VERSION "Version"

NS_ :

BS_:

BU_: LBMS CCU ZCUR_ZCUT Tester PLGM CCURT2 TMC ZCUF ZCUL ZCUR ZCUT EMS DCDC IPS NIDU DCU2 IDUR OBC OPC LPC CPC GCU DCU IPU BMS EOP DCDC2 SRS ECS SAS CBM RAS EPS RBM IBCS ICM IID IDC RCICP AMP WHUD IMR CD INU ADC IFC FAPA RRR RLR PAS PCS SCMR SCMRL SCMRR SCMRM SCMT MFS DRM IDU FCP RCP LBMSAD AVAS DLPFL FBLCM FLISD FLLCM FRLCM RLLCMA RLLCMB RRLCMA RRLCMB RLISD RRISD DLPML DLPMR PSDL PSDR HVSPRL HVSPRR TBOX2 TBOX EPB RFR SBM WCM ETC EVCC CCURT1 EDL

BO_ 1016 LBMS_3: 64 LBMS
 SG_ LBMS_UnSfLoadCurrent : 31|22@0+ (0.001,-1500) [-1500|2694.303] "A"  CCU,CCURT1,CCURT2
 SG_ LBMS_UnSftyLoadCurrentVD : 200|1@0+ (1,0) [0|1] ""  CCU,CCURT1,CCURT2
 SG_ LBMS_SfLoadCurrent : 41|22@0+ (0.001,-1500) [-1500|2694.303] "A"  CCU,CCURT1,CCURT2
 SG_ LBMS_SfLoadCurrentVD : 201|1@0+ (1,0) [0|1] ""  CCU,CCURT1,CCURT2
 SG_ LBMS_ComSoVolt : 99|12@0+ (0.01,0) [0|40.95] "V"  CCU,CCURT1,CCURT2
 SG_ LBMS_ComSoVoltVD : 202|1@0+ (1,0) [0|1] ""  CCU,CCURT1,CCURT2
 SG_ LBMS_UnSfLoadComSoVolt : 119|12@0+ (0.01,0) [0|40.95] "V"  CCU,CCURT1,CCURT2
 SG_ LBMS_UnSfLoadComSoVoltVD : 203|1@0+ (1,0) [0|1] ""  CCU,CCURT1,CCURT2
 SG_ LBMS_UnsfLoadMosst : 171|3@0+ (1,0) [0|7] ""  CCU,CCURT1,CCURT2
 SG_ LBMS_UnSfLoadMosTemp1 : 67|8@0+ (1,-40) [-40|215] "℃"  CCU,CCURT1,CCURT2
 SG_ LBMS_UnSfLoadMosTemp1VD : 204|1@0+ (1,0) [0|1] ""  CCU,CCURT1,CCURT2
 SG_ LBMS_UnSfLoadMosTemp2 : 75|8@0+ (1,-40) [-40|215] "℃"  CCU,CCURT1,CCURT2
 SG_ LBMS_UnSfLoadMosTemp2VD : 205|1@0+ (1,0) [0|1] ""  CCU,CCURT1,CCURT2
 SG_ LBMS_UnSfLoadShuntTemp : 83|8@0+ (1,-40) [-40|215] "℃"  CCU,CCURT1,CCURT2
 SG_ LBMS_UnSfLoadShuntTempVD : 206|1@0+ (1,0) [0|1] ""  CCU,CCURT1,CCURT2
 SG_ LBMS_SfLoadShuntTemp : 91|8@0+ (1,-40) [-40|215] "℃"  CCU,CCURT1,CCURT2
 SG_ LBMS_SfLoadShuntTempVD : 207|1@0+ (1,0) [0|1] ""  CCU,CCURT1,CCURT2
 SG_ LBMS_UnSfLoadChgMosDrvVolt : 123|12@0+ (0.01,0) [0|40.95] "V"  CCU,CCURT1,CCURT2
 SG_ LBMS_UnSfLoadChgMosDrvVoltVD : 212|1@0+ (1,0) [0|1] ""  CCU,CCURT1,CCURT2
 SG_ LBMS_UnSfLoadDsgMosDrvVolt : 143|12@0+ (0.01,0) [0|40.95] "V"  CCU,CCURT1,CCURT2
 SG_ LBMS_UnSfLoadDsgMosDrvVoltVD : 213|1@0+ (1,0) [0|1] ""  CCU,CCURT1,CCURT2
 SG_ LBMS_ChgMosDrvVolt : 147|12@0+ (0.01,0) [0|40.95] "V"  CCU,CCURT1,CCURT2
 SG_ LBMS_ChgMosDrvVoltVD : 214|1@0+ (1,0) [0|1] ""  CCU,CCURT1,CCURT2
 SG_ LBMS_DsgMosDrvVolt : 167|12@0+ (0.01,0) [0|40.95] "V"  CCU,CCURT1,CCURT2
 SG_ LBMS_DsgMosDrvVoltVD : 215|1@0+ (1,0) [0|1] ""  CCU,CCURT1,CCURT2
 SG_ LBMS_UnSfLoadFaultOTMOS : 185|2@0+ (1,0) [0|3] ""  CCU,CCURT1,CCURT2
 SG_ LBMS_UnSfLoadFaultOTS : 187|2@0+ (1,0) [0|3] ""  CCU,CCURT1,CCURT2
 SG_ LBMS_SfLoadFaultOTS : 189|2@0+ (1,0) [0|3] ""  CCU,CCURT1,CCURT2
 SG_ LBMS_UnSfLoadFaultChgOC : 191|2@0+ (1,0) [0|3] ""  CCU,CCURT1,CCURT2
 SG_ LBMS_UnSfLoadFaultDsgOC : 178|3@0+ (1,0) [0|7] ""  CCU,CCURT1,CCURT2
 SG_ LBMS_SfLoadFaultDsgOC : 181|3@0+ (1,0) [0|7] ""  CCU,CCURT1,CCURT2
 SG_ LBMS_UnSfLoadFaultHardTCMOS : 193|2@0+ (1,0) [0|3] ""  CCU,CCURT1,CCURT2
 SG_ LBMS_UnSfLoadFaultHardShunt : 195|2@0+ (1,0) [0|3] ""  CCU,CCURT1,CCURT2
 SG_ LBMS_SfLoadFaultHardShunt : 197|2@0+ (1,0) [0|3] ""  CCU,CCURT1,CCURT2
 SG_ LBMS_UnSfLoadFaultHardChgMOS : 199|2@0+ (1,0) [0|3] ""  CCU,CCURT1,CCURT2
 SG_ LBMS_UnSfLoadFaultHardDsgMOS : 168|3@0+ (1,0) [0|7] ""  CCU,CCURT1,CCURT2
 SG_ LBMS_SOCTolerance : 211|8@0+ (1,0) [0|255] "%"  CCU,CCURT1,CCURT2
 SG_ LBMS_ChgMosDrvCmd : 240|1@0+ (1,0) [0|1] ""  CCU,CCURT1,CCURT2
 SG_ LBMS_DsgMosDrvCmd : 241|1@0+ (1,0) [0|1] ""  CCU,CCURT1,CCURT2
 SG_ LBMS_Cell1BalCtrlCmd : 242|1@0+ (1,0) [0|1] ""  CCU,CCURT1,CCURT2
 SG_ LBMS_Cell2BalCtrlCmd : 243|1@0+ (1,0) [0|1] ""  CCU,CCURT1,CCURT2
 SG_ LBMS_Cell3BalCtrlCmd : 252|1@0+ (1,0) [0|1] ""  CCU,CCURT1,CCURT2
 SG_ LBMS_Cell4BalCtrlCmd : 253|1@0+ (1,0) [0|1] ""  CCU,CCURT1,CCURT2
 SG_ LBMS_FaultStHardPackVolCol : 233|2@0+ (1,0) [0|3] ""  CCU,CCURT1,CCURT2
 SG_ LBMS_FaultStHardUnSfPackVolCol : 235|2@0+ (1,0) [0|3] ""  CCU,CCURT1,CCURT2
 SG_ LBMS_PoleTemp : 219|8@0+ (1,-40) [-40|215] "℃"  CCU,CCURT1,CCURT2
 SG_ LBMS_PoleTempVD : 254|1@0+ (1,0) [0|1] ""  CCU,CCURT1,CCURT2
 SG_ LBMS_SfLoadPoleTemp : 227|8@0+ (1,-40) [-40|215] "℃"  CCU,CCURT1,CCURT2
 SG_ LBMS_SfLoadPoleTempVD : 255|1@0+ (1,0) [0|1] ""  CCU,CCURT1,CCURT2
 SG_ LBMS_FaultStHardCellTotVolCol : 245|2@0+ (1,0) [0|3] ""  CCU,CCURT1,CCURT2
 SG_ LBMS_FaultStHardComSoVoltCol : 247|2@0+ (1,0) [0|3] ""  CCU,CCURT1,CCURT2
 SG_ LBMS_AvailableCapacity : 374|9@0+ (0.1,0) [0|50] "Ah"  CCU,CCURT1,CCURT2
 SG_ LBMS_DCDCMosOpenReason : 291|8@0+ (1,0) [0|255] ""  CCU,CCURT1,CCURT2
 SG_ LBMS_AutoChgReason : 381|3@0+ (1,0) [0|7] ""  CCU,CCURT1,CCURT2
 SG_ LBMS_LockSOCThreshold_Trans : 299|8@0+ (1,0) [0|100] "%"  CCU,CCURT1,CCURT2
 SG_ LBMS_LockSOCThreshold_Level1 : 307|8@0+ (1,0) [0|100] "%"  CCU,CCURT1,CCURT2
 SG_ LBMS_LockSOCThreshold_Level2 : 315|8@0+ (1,0) [0|100] "%"  CCU,CCURT1,CCURT2
 SG_ LBMS_AutoChgThres_TransLo : 323|8@0+ (1,0) [0|100] "%"  CCU,CCURT1,CCURT2
 SG_ LBMS_AutoChgThres_TransUp : 331|8@0+ (1,0) [0|100] "%"  CCU,CCURT1,CCURT2
 SG_ LBMS_AutoChgThres_NtransLo : 339|8@0+ (1,0) [0|100] "%"  CCU,CCURT1,CCURT2
 SG_ LBMS_AutoChgThres_NtransUp : 347|8@0+ (1,0) [0|100] "%"  CCU,CCURT1,CCURT2
 SG_ LBMS_Last2LocWakeUpTime : 251|20@0+ (1,0) [0|1048575] "min"  CCU,CCURT1,CCURT2
 SG_ LBMS_SleepTime_NM : 279|20@0+ (1,0) [0|1048575] "min"  CCU,CCURT1,CCURT2
 SG_ LBMS_ServiceTime : 355|13@0+ (1,0) [0|8191] "day"  CCU,CCURT1,CCURT2
 SG_ LBMS_DsgMosOpenReason : 391|8@0+ (1,0) [0|255] ""  CCU,CCURT1,CCURT2
 SG_ LBMS_ChgMosOpenReason : 399|8@0+ (1,0) [0|255] ""  CCU,CCURT1,CCURT2
 SG_ LBMS_LocalNotSleep_Reason : 423|4@0+ (1,0) [0|15] ""  CCU,CCURT1,CCURT2
 SG_ LBMS_SfUpackRvsVolt : 407|12@0+ (0.01,-20) [-20|20] "V"  CCU,CCURT1,CCURT2
 SG_ LBMS_SfUpackRvsVoltVD : 378|1@0+ (1,0) [0|1] ""  CCU,CCURT1,CCURT2
 SG_ LBMS_SfFaultStHardComSoVoltCol : 377|2@0+ (1,0) [0|3] ""  CCU,CCURT1,CCURT2
 SG_ LBMS_SfChgMosDrvCmd : 411|1@0+ (1,0) [0|1] ""  CCU,CCURT1,CCURT2
 SG_ LBMS_SfDsgMosDrvCmd : 410|1@0+ (1,0) [0|1] ""  CCU,CCURT1,CCURT2
 SG_ LBMS_SfLoadUpackRvsVolt : 419|12@0+ (0.01,-20) [-20|20] "V"  CCU,CCURT1,CCURT2
 SG_ LBMS_SfLoadUpackRvsVoltVD : 409|1@0+ (1,0) [0|1] ""  CCU,CCURT1,CCURT2
 SG_ LBMS_UnSfLoadChgMosDrvCmd : 408|1@0+ (1,0) [0|1] ""  CCU,CCURT1,CCURT2
 SG_ LBMS_UnSfLoadDsgMosDrvCmd : 455|1@0+ (1,0) [0|1] ""  CCU,CCURT1,CCURT2
 SG_ LBMS_UnsfLoadDsgMosOpenReason : 439|8@0+ (1,0) [0|255] ""  CCU,CCURT1,CCURT2
 SG_ LBMS_UnsfLoadChgMosOpenReason : 447|8@0+ (1,0) [0|255] ""  CCU,CCURT1,CCURT2
 SG_ LBMS_FaultStHarddUnSfComSoVoltCol : 454|2@0+ (1,0) [0|3] ""  CCU,CCURT1,CCURT2

BO_ 794 CCU_LBMSAD_1: 64 CCU
 SG_ LBMSAD_1_CRC : 7|16@0+ (1,0) [0|65535] ""  LBMS
 SG_ LBMSAD_1_Counter : 23|8@0+ (1,0) [0|255] ""  LBMS
 SG_ LBMSAD_SOFVD : 28|1@0+ (1,0) [0|1] ""  LBMS
 SG_ LBMSAD_SOFEN : 30|2@0+ (1,0) [0|3] ""  LBMS
 SG_ LBMSAD_ChargReq : 26|3@0+ (1,0) [0|7] ""  LBMS
 SG_ LBMSAD_SOCVD : 27|1@0+ (1,0) [0|1] ""  LBMS
 SG_ LBMSAD_SOC : 39|8@0+ (1,0) [0|100] "%"  LBMS
 SG_ LBMSAD_AlrmDispSt : 60|3@0+ (1,0) [0|7] ""  LBMS
 SG_ LBMSAD_CurrentRange : 57|2@0+ (1,0) [0|3] ""  LBMS
 SG_ LBMSAD_RefChargReq : 75|2@0+ (1,0) [0|3] ""  LBMS
 SG_ LBMSAD_ThermalRunawayErr : 77|2@0+ (1,0) [0|3] ""  LBMS
 SG_ LBMSAD_ChrgVoltReq : 71|10@0+ (0.01,9) [9|19.23] "V"  LBMS
 SG_ LBMSAD_IPDS_BAT1PowerReq : 107|1@0+ (1,0) [0|1] ""  LBMS
 SG_ LBMSAD_IPDS_BAT2PowerReq : 108|1@0+ (1,0) [0|1] ""  LBMS
 SG_ LBMSAD_IPDS_GridlsoPowerReq : 109|1@0+ (1,0) [0|1] ""  LBMS

BO_ 974 CCU_LBMSAD_2: 64 CCU
 SG_ LBMSAD_SOH : 7|8@0+ (1,0) [0|255] ""  LBMS
 SG_ LBMSAD_SOHVD : 25|1@0+ (1,0) [0|1] ""  LBMS
 SG_ LBMSAD_Current : 15|22@0+ (0.001,-1500) [-1500|2694.303] "A"  LBMS
 SG_ LBMSAD_CellTotVolt : 43|11@0+ (0.01,0) [0|20.47] "V"  LBMS
 SG_ LBMSAD_CellTotVoltVD : 24|1@0+ (1,0) [0|1] ""  LBMS
 SG_ LBMSAD_ChargReqEn : 48|1@0+ (1,0) [0|1] ""  LBMS
 SG_ LBMSAD_WorkSt : 63|4@0+ (1,0) [0|15] ""  LBMS
 SG_ LBMSAD_MOSSt : 71|3@0+ (1,0) [0|7] ""  LBMS
 SG_ LBMSAD_WireHarnConSt : 202|1@0+ (1,0) [0|1] ""  LBMS
 SG_ LBMSAD_CellMaxVolt : 183|13@0+ (0.001,0) [0|8.191] "V"  LBMS
 SG_ LBMSAD_CellMinVolt : 199|13@0+ (0.001,0) [0|8.191] "V"  LBMS
 SG_ LBMSAD_CellTemp1 : 215|8@0+ (1,-40) [-40|215] "℃"  LBMS
 SG_ LBMSAD_CellTemp2 : 223|8@0+ (1,-40) [-40|215] "℃"  LBMS
 SG_ LBMSAD_CellTemp3 : 231|8@0+ (1,-40) [-40|215] "℃"  LBMS

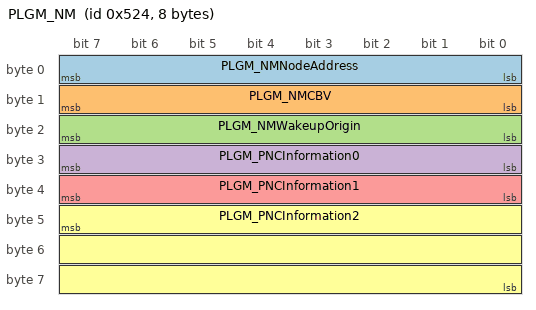
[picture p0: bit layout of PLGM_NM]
BO_ 1316 PLGM_NM: 8 PLGM
 SG_ PLGM_NMNodeAddress : 7|8@0+ (1,0) [0|255] ""  CCU,ZCUR,LBMS
 SG_ PLGM_NMCBV : 15|8@0+ (1,0) [0|0] ""  CCU,ZCUR,LBMS
 SG_ PLGM_NMWakeupOrigin : 23|8@0+ (1,0) [0|255] ""  CCU,ZCUR,LBMS
 SG_ PLGM_PNCInformation0 : 31|8@0+ (1,0) [0|255] ""  CCU,ZCUR,LBMS
 SG_ PLGM_PNCInformation1 : 39|8@0+ (1,0) [0|255] ""  CCU,ZCUR,LBMS
 SG_ PLGM_PNCInformation2 : 47|24@0+ (1,0) [0|0] ""  CCU,ZCUR,LBMS

BO_ 387 CCU_ADC_4_New: 64 CCU
 SG_ ADC_4_New_CRC : 7|16@0+ (1,0) [0|65535] ""  ZCUF,ZCUL,ZCUR,ZCUT,SRS,EPS,RBM,IBCS,LBMSAD,LBMS
 SG_ ADC_4_New_Counter : 23|8@0+ (1,0) [0|255] ""  ZCUF,ZCUL,ZCUR,ZCUT,SRS,EPS,RBM,IBCS,LBMSAD,LBMS
 SG_ ADC_AD_NetMode : 65|2@0+ (1,0) [0|3] "/"  ZCUF,ZCUL,ZCUR,ZCUT,SRS,EPS,RBM,IBCS,LBMSAD,LBMS

CM_ SG_ 1016 LBMS_UnSfLoadCurrent "Battery unsafe load current";
CM_ SG_ 1016 LBMS_UnSftyLoadCurrentVD "Battery unsafe load current validity";
CM_ SG_ 1016 LBMS_SfLoadCurrent "Battery safe load current";
CM_ SG_ 1016 LBMS_SfLoadCurrentVD "Battery safe load current validity";
CM_ SG_ 1016 LBMS_ComSoVolt "Battery  common source voltage";
CM_ SG_ 1016 LBMS_ComSoVoltVD "Battery  common source voltage validity";
CM_ SG_ 1016 LBMS_UnSfLoadComSoVolt "Battery  common source voltage of unsafe load ";
CM_ SG_ 1016 LBMS_UnSfLoadComSoVoltVD "Battery  common source voltage of unsafe load validity";
CM_ SG_ 1016 LBMS_UnsfLoadMosst "State of unsafe load mos";
CM_ SG_ 1016 LBMS_UnSfLoadMosTemp1 "UnSafe Load Mos1 temperature";
CM_ SG_ 1016 LBMS_UnSfLoadMosTemp1VD "UnSafe load Mos1 temperature validity";
CM_ SG_ 1016 LBMS_UnSfLoadMosTemp2 "UnSafe load mos2 temperature";
CM_ SG_ 1016 LBMS_UnSfLoadMosTemp2VD "UnSafe load mos2 temperature validity";
CM_ SG_ 1016 LBMS_UnSfLoadShuntTemp "UnSafe load shunt temperature signal";
CM_ SG_ 1016 LBMS_UnSfLoadShuntTempVD "UnSafe load shunt temperature signal validity";
CM_ SG_ 1016 LBMS_SfLoadShuntTemp "Safe load shunt temperature signal";
CM_ SG_ 1016 LBMS_SfLoadShuntTempVD "Safe load shunt temperature signal validity";
CM_ SG_ 1016 LBMS_UnSfLoadChgMosDrvVolt "Charge Mos driver voltage of unsafe load ";
CM_ SG_ 1016 LBMS_UnSfLoadChgMosDrvVoltVD "Charge Mos driver voltage of unsafe load Validity";
CM_ SG_ 1016 LBMS_UnSfLoadDsgMosDrvVolt "Discharge Mos driver voltage of unsafe load ";
CM_ SG_ 1016 LBMS_UnSfLoadDsgMosDrvVoltVD "Discharge Mos driver voltage of unsafe load Validity";
CM_ SG_ 1016 LBMS_ChgMosDrvVolt "Charge Mos driver voltage";
CM_ SG_ 1016 LBMS_ChgMosDrvVoltVD "Charge Mos driver voltage Validity";
CM_ SG_ 1016 LBMS_DsgMosDrvVolt "Discharge Mos driver voltage";
CM_ SG_ 1016 LBMS_DsgMosDrvVoltVD "Discharge Mos driver voltage Validity";
CM_ SG_ 1016 LBMS_UnSfLoadFaultOTMOS "Over temperature fault of UnSafe Load MOS";
CM_ SG_ 1016 LBMS_UnSfLoadFaultOTS "Over temperature fault of UnSafe Load Shunt";
CM_ SG_ 1016 LBMS_SfLoadFaultOTS "Over temperature fault of Safe Load Shunt";
CM_ SG_ 1016 LBMS_UnSfLoadFaultChgOC " UnSafe Load Charge over current fault";
CM_ SG_ 1016 LBMS_UnSfLoadFaultDsgOC " UnSafe Load Discharge over current fault";
CM_ SG_ 1016 LBMS_SfLoadFaultDsgOC " Safe Load Discharge over current fault";
CM_ SG_ 1016 LBMS_UnSfLoadFaultHardTCMOS "Temperature collect hardware fault of UnSafe Load MOS";
CM_ SG_ 1016 LBMS_UnSfLoadFaultHardShunt "UnSafe Load Shunt  hardware fault";
CM_ SG_ 1016 LBMS_SfLoadFaultHardShunt "Safe Load Shunt  hardware fault";
CM_ SG_ 1016 LBMS_UnSfLoadFaultHardChgMOS "UnSafe Load Charge mos hardware fault";
CM_ SG_ 1016 LBMS_UnSfLoadFaultHardDsgMOS "UnSafe Load Discharge mos hardware fault";
CM_ SG_ 1016 LBMS_SOCTolerance "The Tolerance of SOC";
CM_ SG_ 1016 LBMS_ChgMosDrvCmd "LBMS Charge Mosfet Driver Command";
CM_ SG_ 1016 LBMS_DsgMosDrvCmd "LBMS Discharge Mosfet Driver Command";
CM_ SG_ 1016 LBMS_Cell1BalCtrlCmd "LBMS Cell1 Balance Control Command";
CM_ SG_ 1016 LBMS_Cell2BalCtrlCmd "LBMS Cell2 Balance Control Command";
CM_ SG_ 1016 LBMS_Cell3BalCtrlCmd "LBMS Cell3 Balance Control Command";
CM_ SG_ 1016 LBMS_Cell4BalCtrlCmd "LBMS Cell4 Balance Control Command";
CM_ SG_ 1016 LBMS_FaultStHardPackVolCol "Pack volt collect open hardware fault";
CM_ SG_ 1016 LBMS_FaultStHardUnSfPackVolCol "Unsafe Load Pack volt collect open hardware fault";
CM_ SG_ 1016 LBMS_PoleTemp "UnSafe Load Pole temperature";
CM_ SG_ 1016 LBMS_PoleTempVD "UnSafe load Pole temperature validity";
CM_ SG_ 1016 LBMS_SfLoadPoleTemp "Safe Load Pole temperature";
CM_ SG_ 1016 LBMS_SfLoadPoleTempVD "Safe load Pole temperature validity";
CM_ SG_ 1016 LBMS_FaultStHardCellTotVolCol "Cell total volt collect open hardware fault";
CM_ SG_ 1016 LBMS_FaultStHardComSoVoltCol "Battery common source volt collect open hardware fault";
CM_ SG_ 1016 LBMS_AvailableCapacity "LBMS Available Capacity of Battery";
CM_ SG_ 1016 LBMS_DCDCMosOpenReason "LBMS DCDC Mosfet Open Reason";
CM_ SG_ 1016 LBMS_AutoChgReason "LBMS Automatic Charging Reason";
CM_ SG_ 1016 LBMS_LockSOCThreshold_Trans "LBMS Lock Threshold of Transport Mode";
CM_ SG_ 1016 LBMS_LockSOCThreshold_Level1 "LBMS Lock Threshold of Level1";
CM_ SG_ 1016 LBMS_LockSOCThreshold_Level2 "LBMS Lock Threshold of Level2";
CM_ SG_ 1016 LBMS_AutoChgThres_TransLo "LBMS Automatic Charging Threshold Lower Limit of Transport Mode";
CM_ SG_ 1016 LBMS_AutoChgThres_TransUp "LBMS Automatic Charging Threshold Upper Limit of Transport Mode";
CM_ SG_ 1016 LBMS_AutoChgThres_NtransLo "LBMS Automatic Charging Threshold Lower Limit of None Transport Mode";
CM_ SG_ 1016 LBMS_AutoChgThres_NtransUp "LBMS Automatic Charging Threshold Upper Limit of None Transport Mode";
CM_ SG_ 1016 LBMS_Last2LocWakeUpTime "The Time Between Last 2 Local wake up of LBMS";
CM_ SG_ 1016 LBMS_SleepTime_NM "The Sleep Time of Network";
CM_ SG_ 1016 LBMS_ServiceTime "Accumulated Battery  Service time";
CM_ SG_ 1016 LBMS_DsgMosOpenReason "LBMS Discharge Mosfet Open Reason";
CM_ SG_ 1016 LBMS_ChgMosOpenReason "LBMS Charge Mosfet Open Reason";
CM_ SG_ 1016 LBMS_LocalNotSleep_Reason "Reason of LBMS not sleep locally for a long time";
CM_ SG_ 1016 LBMS_SfUpackRvsVolt "LBMS Battery Reverse Connection Voltage of Pack";
CM_ SG_ 1016 LBMS_SfUpackRvsVoltVD "LBMS Battery Reverse Connection Voltage of Pack Validity";
CM_ SG_ 1016 LBMS_SfFaultStHardComSoVoltCol "Safe Load Battery common source volt collect open hardware fault";
CM_ SG_ 1016 LBMS_SfChgMosDrvCmd "LBMS Safe load Charge Mosfet Driver Command";
CM_ SG_ 1016 LBMS_SfDsgMosDrvCmd "LBMS Safe load Discharge Mosfet Driver Command";
CM_ SG_ 1016 LBMS_SfLoadUpackRvsVolt "LBMS Battery Negative Voltage of Pack for Sf Load";
CM_ SG_ 1016 LBMS_SfLoadUpackRvsVoltVD "LBMS Battery Negative Voltage of Pack Validity for Sf Load";
CM_ SG_ 1016 LBMS_UnSfLoadChgMosDrvCmd "LBMS Charge Mosfet Driver Command of unsafe load";
CM_ SG_ 1016 LBMS_UnSfLoadDsgMosDrvCmd "LBMS Discharge Mosfet Driver Command of unsafe load";
CM_ SG_ 1016 LBMS_UnsfLoadDsgMosOpenReason "LBMS Discharge Mosfet Open Reason";
CM_ SG_ 1016 LBMS_UnsfLoadChgMosOpenReason "LBMS Charge Mosfet Open Reason";
CM_ SG_ 1016 LBMS_FaultStHarddUnSfComSoVoltCol "Battery Unsafe Load common source volt collect open hardware fault";
CM_ SG_ 794 LBMSAD_1_CRC "E2E Profile 5 CRC";
CM_ SG_ 794 LBMSAD_1_Counter "E2E Profile 5 Counter";
CM_ SG_ 794 LBMSAD_SOFVD "LBMSAD Validity of SOF";
CM_ SG_ 794 LBMSAD_SOFEN "LBMSAD  State of Function Enable";
CM_ SG_ 794 LBMSAD_ChargReq "LBMSAD Battery Charge Request";
CM_ SG_ 794 LBMSAD_SOCVD "LBMSAD Validity of SOC";
CM_ SG_ 794 LBMSAD_SOC "LBMSAD  State of Charge";
CM_ SG_ 794 LBMSAD_AlrmDispSt "Alarm  State for Display of Low voltage battery Management System";
CM_ SG_ 794 LBMSAD_CurrentRange "LBMSAD Battery Current  Range";
CM_ SG_ 794 LBMSAD_RefChargReq "Battery fully charged signDynamic calibration";
CM_ SG_ 794 LBMSAD_ThermalRunawayErr "Lithium electrothermal runaway state signal";
CM_ SG_ 794 LBMSAD_ChrgVoltReq "Battery Charging Volt Request";
CM_ SG_ 794 LBMSAD_IPDS_BAT1PowerReq "LBMSAD Control Battery1 power Request";
CM_ SG_ 794 LBMSAD_IPDS_BAT2PowerReq "LBMSAD Control Battery2 power Request";
CM_ SG_ 794 LBMSAD_IPDS_GridlsoPowerReq "LBMSAD Control Grid Isolation Power Request";
CM_ SG_ 974 LBMSAD_SOH "LBMSAD State of Health";
CM_ SG_ 974 LBMSAD_SOHVD "LBMSAD Validity of SOH";
CM_ SG_ 974 LBMSAD_Current "LBMSAD Battery Current";
CM_ SG_ 974 LBMSAD_CellTotVolt "LBMSAD The total internal voltage of the battery";
CM_ SG_ 974 LBMSAD_CellTotVoltVD "LBMSAD The total internal voltage of the battery Validity";
CM_ SG_ 974 LBMSAD_ChargReqEn "Autocharge Request of Low voltage battery Management System Enable state";
CM_ SG_ 974 LBMSAD_WorkSt "LBMSAD Battery Working State";
CM_ SG_ 974 LBMSAD_MOSSt "State of Mos";
CM_ SG_ 974 LBMSAD_WireHarnConSt "Wire harness connect state";
CM_ SG_ 974 LBMSAD_CellMaxVolt "Cell maximum voltage";
CM_ SG_ 974 LBMSAD_CellMinVolt "Cell minimum voltage ";
CM_ SG_ 974 LBMSAD_CellTemp1 "Battery cell temperature 1";
CM_ SG_ 974 LBMSAD_CellTemp2 "Battery cell temperature 2";
CM_ SG_ 974 LBMSAD_CellTemp3 "Battery cell temperature 3";
CM_ SG_ 1316 PLGM_NMNodeAddress "PLGM node address";
CM_ SG_ 1316 PLGM_NMCBV "PLGM Network management control bit vector";
CM_ SG_ 1316 PLGM_NMWakeupOrigin "Origin of the wake up";
CM_ SG_ 1316 PLGM_PNCInformation0 "PNC Information";
CM_ SG_ 1316 PLGM_PNCInformation1 "PNC Information";
CM_ SG_ 1316 PLGM_PNCInformation2 "PNC Information";
CM_ SG_ 387 ADC_4_New_CRC "E2E Profile 5 CRC";
CM_ SG_ 387 ADC_4_New_Counter "E2E Profile 5 Counter";
CM_ SG_ 387 ADC_AD_NetMode "Autonomous_Driving Request Net Mode";

BA_DEF_ BO_  "GenMsgCycleTime" INT 0 0;
BA_DEF_ BO_  "GenMsgCycleTimeFast" INT 0 0;
BA_DEF_ BO_  "GenMsgSendType" ENUM  "Periodic","Event","IfActive","POE","PA","FixedPeriodic","Event","EnabledPeriodic","NotUsed","NotUsed","EventPeriodic","NotUsed","NotUsed","NoMsgSendType";
BA_DEF_ BO_  "VFrameFormat" ENUM  "StandardCAN","ExtendedCAN","reserved","reserved","reserved","reserved","reserved","reserved","reserved","reserved","reserved","reserved","reserved","reserved","StandardCAN_FD","ExtendedCAN_FD";
BA_DEF_ BO_  "CANFD_BRS" ENUM  "0","1";
BA_DEF_ SG_  "EventCommandSignal" ENUM  "No","Yes";
BA_DEF_ SG_  "GatewayedSignals" ENUM  "No","Yes";
BA_DEF_ SG_  "GenSigInactiveValue" HEX 0 0;
BA_DEF_ SG_  "GenSigInvalidValue" HEX 0 0;
BA_DEF_ SG_  "GenSigSendType" ENUM  "Trigger","Passive","Cyclic","OnWrite","OnWriteWithRepetition","OnChange","OnChangeWithRepetition","IfActive","IfActiveWithRepetition","NoSigSendType";
BA_DEF_ SG_  "GenSigStartValue" HEX 0 0;
BA_DEF_ SG_  "GenSigTimeoutValue" HEX 0 0;
BA_DEF_ SG_  "Remark" STRING ;
BA_ "GenMsgCycleTime" BO_ 1016 500;
BA_ "GenMsgCycleTimeFast" BO_ 1016 0;
BA_ "GenMsgSendType" BO_ 1016 0;
BA_ "VFrameFormat" BO_ 1016 14;
BA_ "CANFD_BRS" BO_ 1016 1;
BA_ "GenMsgCycleTime" BO_ 1016 500;
BA_ "GenMsgCycleTimeFast" BO_ 1016 0;
BA_ "GenMsgSendType" BO_ 1016 0;
BA_ "VFrameFormat" BO_ 1016 14;
BA_ "CANFD_BRS" BO_ 1016 1;
BA_ "GenMsgCycleTime" BO_ 1016 500;
BA_ "GenMsgCycleTimeFast" BO_ 1016 0;
BA_ "GenMsgSendType" BO_ 1016 0;
BA_ "VFrameFormat" BO_ 1016 14;
BA_ "CANFD_BRS" BO_ 1016 1;
BA_ "GenMsgCycleTime" BO_ 1016 500;
BA_ "GenMsgCycleTimeFast" BO_ 1016 0;
BA_ "GenMsgSendType" BO_ 1016 0;
BA_ "VFrameFormat" BO_ 1016 14;
BA_ "CANFD_BRS" BO_ 1016 1;
BA_ "GenMsgCycleTime" BO_ 1016 500;
BA_ "GenMsgCycleTimeFast" BO_ 1016 0;
BA_ "GenMsgSendType" BO_ 1016 0;
BA_ "VFrameFormat" BO_ 1016 14;
BA_ "CANFD_BRS" BO_ 1016 1;
BA_ "GenMsgCycleTime" BO_ 1016 500;
BA_ "GenMsgCycleTimeFast" BO_ 1016 0;
BA_ "GenMsgSendType" BO_ 1016 0;
BA_ "VFrameFormat" BO_ 1016 14;
BA_ "CANFD_BRS" BO_ 1016 1;
BA_ "GenMsgCycleTime" BO_ 1016 500;
BA_ "GenMsgCycleTimeFast" BO_ 1016 0;
BA_ "GenMsgSendType" BO_ 1016 0;
BA_ "VFrameFormat" BO_ 1016 14;
BA_ "CANFD_BRS" BO_ 1016 1;
BA_ "GenMsgCycleTime" BO_ 1016 500;
BA_ "GenMsgCycleTimeFast" BO_ 1016 0;
BA_ "GenMsgSendType" BO_ 1016 0;
BA_ "VFrameFormat" BO_ 1016 14;
BA_ "CANFD_BRS" BO_ 1016 1;
BA_ "GenMsgCycleTime" BO_ 1016 500;
BA_ "GenMsgCycleTimeFast" BO_ 1016 0;
BA_ "GenMsgSendType" BO_ 1016 0;
BA_ "VFrameFormat" BO_ 1016 14;
BA_ "CANFD_BRS" BO_ 1016 1;
BA_ "GenMsgCycleTime" BO_ 1016 500;
BA_ "GenMsgCycleTimeFast" BO_ 1016 0;
BA_ "GenMsgSendType" BO_ 1016 0;
BA_ "VFrameFormat" BO_ 1016 14;
BA_ "CANFD_BRS" BO_ 1016 1;
BA_ "GenMsgCycleTime" BO_ 1016 500;
BA_ "GenMsgCycleTimeFast" BO_ 1016 0;
BA_ "GenMsgSendType" BO_ 1016 0;
BA_ "VFrameFormat" BO_ 1016 14;
BA_ "CANFD_BRS" BO_ 1016 1;
BA_ "GenMsgCycleTime" BO_ 1016 500;
BA_ "GenMsgCycleTimeFast" BO_ 1016 0;
BA_ "GenMsgSendType" BO_ 1016 0;
BA_ "VFrameFormat" BO_ 1016 14;
BA_ "CANFD_BRS" BO_ 1016 1;
BA_ "GenMsgCycleTime" BO_ 1016 500;
BA_ "GenMsgCycleTimeFast" BO_ 1016 0;
BA_ "GenMsgSendType" BO_ 1016 0;
BA_ "VFrameFormat" BO_ 1016 14;
BA_ "CANFD_BRS" BO_ 1016 1;
BA_ "GenMsgCycleTime" BO_ 1016 500;
BA_ "GenMsgCycleTimeFast" BO_ 1016 0;
BA_ "GenMsgSendType" BO_ 1016 0;
BA_ "VFrameFormat" BO_ 1016 14;
BA_ "CANFD_BRS" BO_ 1016 1;
BA_ "GenMsgCycleTime" BO_ 1016 500;
BA_ "GenMsgCycleTimeFast" BO_ 1016 0;
BA_ "GenMsgSendType" BO_ 1016 0;
BA_ "VFrameFormat" BO_ 1016 14;
BA_ "CANFD_BRS" BO_ 1016 1;
BA_ "GenMsgCycleTime" BO_ 1016 500;
BA_ "GenMsgCycleTimeFast" BO_ 1016 0;
BA_ "GenMsgSendType" BO_ 1016 0;
BA_ "VFrameFormat" BO_ 1016 14;
BA_ "CANFD_BRS" BO_ 1016 1;
BA_ "GenMsgCycleTime" BO_ 1016 500;
BA_ "GenMsgCycleTimeFast" BO_ 1016 0;
BA_ "GenMsgSendType" BO_ 1016 0;
BA_ "VFrameFormat" BO_ 1016 14;
BA_ "CANFD_BRS" BO_ 1016 1;
BA_ "GenMsgCycleTime" BO_ 1016 500;
BA_ "GenMsgCycleTimeFast" BO_ 1016 0;
BA_ "GenMsgSendType" BO_ 1016 0;
BA_ "VFrameFormat" BO_ 1016 14;
BA_ "CANFD_BRS" BO_ 1016 1;
BA_ "GenMsgCycleTime" BO_ 1016 500;
BA_ "GenMsgCycleTimeFast" BO_ 1016 0;
BA_ "GenMsgSendType" BO_ 1016 0;
BA_ "VFrameFormat" BO_ 1016 14;
BA_ "CANFD_BRS" BO_ 1016 1;
BA_ "GenMsgCycleTime" BO_ 1016 500;
BA_ "GenMsgCycleTimeFast" BO_ 1016 0;
BA_ "GenMsgSendType" BO_ 1016 0;
BA_ "VFrameFormat" BO_ 1016 14;
BA_ "CANFD_BRS" BO_ 1016 1;
BA_ "GenMsgCycleTime" BO_ 1016 500;
BA_ "GenMsgCycleTimeFast" BO_ 1016 0;
BA_ "GenMsgSendType" BO_ 1016 0;
BA_ "VFrameFormat" BO_ 1016 14;
BA_ "CANFD_BRS" BO_ 1016 1;
BA_ "GenMsgCycleTime" BO_ 1016 500;
BA_ "GenMsgCycleTimeFast" BO_ 1016 0;
BA_ "GenMsgSendType" BO_ 1016 0;
BA_ "VFrameFormat" BO_ 1016 14;
BA_ "CANFD_BRS" BO_ 1016 1;
BA_ "GenMsgCycleTime" BO_ 1016 500;
BA_ "GenMsgCycleTimeFast" BO_ 1016 0;
BA_ "GenMsgSendType" BO_ 1016 0;
BA_ "VFrameFormat" BO_ 1016 14;
BA_ "CANFD_BRS" BO_ 1016 1;
BA_ "GenMsgCycleTime" BO_ 1016 500;
BA_ "GenMsgCycleTimeFast" BO_ 1016 0;
BA_ "GenMsgSendType" BO_ 1016 0;
BA_ "VFrameFormat" BO_ 1016 14;
BA_ "CANFD_BRS" BO_ 1016 1;
BA_ "GenMsgCycleTime" BO_ 1016 500;
BA_ "GenMsgCycleTimeFast" BO_ 1016 0;
BA_ "GenMsgSendType" BO_ 1016 0;
BA_ "VFrameFormat" BO_ 1016 14;
BA_ "CANFD_BRS" BO_ 1016 1;
BA_ "GenMsgCycleTime" BO_ 1016 500;
BA_ "GenMsgCycleTimeFast" BO_ 1016 0;
BA_ "GenMsgSendType" BO_ 1016 0;
BA_ "VFrameFormat" BO_ 1016 14;
BA_ "CANFD_BRS" BO_ 1016 1;
BA_ "GenMsgCycleTime" BO_ 1016 500;
BA_ "GenMsgCycleTimeFast" BO_ 1016 0;
BA_ "GenMsgSendType" BO_ 1016 0;
BA_ "VFrameFormat" BO_ 1016 14;
BA_ "CANFD_BRS" BO_ 1016 1;
BA_ "GenMsgCycleTime" BO_ 1016 500;
BA_ "GenMsgCycleTimeFast" BO_ 1016 0;
BA_ "GenMsgSendType" BO_ 1016 0;
BA_ "VFrameFormat" BO_ 1016 14;
BA_ "CANFD_BRS" BO_ 1016 1;
BA_ "GenMsgCycleTime" BO_ 1016 500;
BA_ "GenMsgCycleTimeFast" BO_ 1016 0;
BA_ "GenMsgSendType" BO_ 1016 0;
BA_ "VFrameFormat" BO_ 1016 14;
BA_ "CANFD_BRS" BO_ 1016 1;
BA_ "GenMsgCycleTime" BO_ 1016 500;
BA_ "GenMsgCycleTimeFast" BO_ 1016 0;
BA_ "GenMsgSendType" BO_ 1016 0;
BA_ "VFrameFormat" BO_ 1016 14;
BA_ "CANFD_BRS" BO_ 1016 1;
BA_ "GenMsgCycleTime" BO_ 1016 500;
BA_ "GenMsgCycleTimeFast" BO_ 1016 0;
BA_ "GenMsgSendType" BO_ 1016 0;
BA_ "VFrameFormat" BO_ 1016 14;
BA_ "CANFD_BRS" BO_ 1016 1;
BA_ "GenMsgCycleTime" BO_ 1016 500;
BA_ "GenMsgCycleTimeFast" BO_ 1016 0;
BA_ "GenMsgSendType" BO_ 1016 0;
BA_ "VFrameFormat" BO_ 1016 14;
BA_ "CANFD_BRS" BO_ 1016 1;
BA_ "GenMsgCycleTime" BO_ 1016 500;
BA_ "GenMsgCycleTimeFast" BO_ 1016 0;
BA_ "GenMsgSendType" BO_ 1016 0;
BA_ "VFrameFormat" BO_ 1016 14;
BA_ "CANFD_BRS" BO_ 1016 1;
BA_ "GenMsgCycleTime" BO_ 1016 500;
BA_ "GenMsgCycleTimeFast" BO_ 1016 0;
BA_ "GenMsgSendType" BO_ 1016 0;
BA_ "VFrameFormat" BO_ 1016 14;
BA_ "CANFD_BRS" BO_ 1016 1;
BA_ "GenMsgCycleTime" BO_ 1016 500;
BA_ "GenMsgCycleTimeFast" BO_ 1016 0;
BA_ "GenMsgSendType" BO_ 1016 0;
BA_ "VFrameFormat" BO_ 1016 14;
BA_ "CANFD_BRS" BO_ 1016 1;
BA_ "GenMsgCycleTime" BO_ 1016 500;
BA_ "GenMsgCycleTimeFast" BO_ 1016 0;
BA_ "GenMsgSendType" BO_ 1016 0;
BA_ "VFrameFormat" BO_ 1016 14;
BA_ "CANFD_BRS" BO_ 1016 1;
BA_ "GenMsgCycleTime" BO_ 1016 500;
BA_ "GenMsgCycleTimeFast" BO_ 1016 0;
BA_ "GenMsgSendType" BO_ 1016 0;
BA_ "VFrameFormat" BO_ 1016 14;
BA_ "CANFD_BRS" BO_ 1016 1;
BA_ "GenMsgCycleTime" BO_ 1016 500;
BA_ "GenMsgCycleTimeFast" BO_ 1016 0;
BA_ "GenMsgSendType" BO_ 1016 0;
BA_ "VFrameFormat" BO_ 1016 14;
BA_ "CANFD_BRS" BO_ 1016 1;
BA_ "GenMsgCycleTime" BO_ 1016 500;
BA_ "GenMsgCycleTimeFast" BO_ 1016 0;
BA_ "GenMsgSendType" BO_ 1016 0;
BA_ "VFrameFormat" BO_ 1016 14;
BA_ "CANFD_BRS" BO_ 1016 1;
BA_ "GenMsgCycleTime" BO_ 1016 500;
BA_ "GenMsgCycleTimeFast" BO_ 1016 0;
BA_ "GenMsgSendType" BO_ 1016 0;
BA_ "VFrameFormat" BO_ 1016 14;
BA_ "CANFD_BRS" BO_ 1016 1;
BA_ "GenMsgCycleTime" BO_ 1016 500;
BA_ "GenMsgCycleTimeFast" BO_ 1016 0;
BA_ "GenMsgSendType" BO_ 1016 0;
BA_ "VFrameFormat" BO_ 1016 14;
BA_ "CANFD_BRS" BO_ 1016 1;
BA_ "GenMsgCycleTime" BO_ 1016 500;
BA_ "GenMsgCycleTimeFast" BO_ 1016 0;
BA_ "GenMsgSendType" BO_ 1016 0;
BA_ "VFrameFormat" BO_ 1016 14;
BA_ "CANFD_BRS" BO_ 1016 1;
BA_ "GenMsgCycleTime" BO_ 1016 500;
BA_ "GenMsgCycleTimeFast" BO_ 1016 0;
BA_ "GenMsgSendType" BO_ 1016 0;
BA_ "VFrameFormat" BO_ 1016 14;
BA_ "CANFD_BRS" BO_ 1016 1;
BA_ "GenMsgCycleTime" BO_ 1016 500;
BA_ "GenMsgCycleTimeFast" BO_ 1016 0;
BA_ "GenMsgSendType" BO_ 1016 0;
BA_ "VFrameFormat" BO_ 1016 14;
BA_ "CANFD_BRS" BO_ 1016 1;
BA_ "GenMsgCycleTime" BO_ 1016 500;
BA_ "GenMsgCycleTimeFast" BO_ 1016 0;
BA_ "GenMsgSendType" BO_ 1016 0;
BA_ "VFrameFormat" BO_ 1016 14;
BA_ "CANFD_BRS" BO_ 1016 1;
BA_ "GenMsgCycleTime" BO_ 1016 500;
BA_ "GenMsgCycleTimeFast" BO_ 1016 0;
BA_ "GenMsgSendType" BO_ 1016 0;
BA_ "VFrameFormat" BO_ 1016 14;
BA_ "CANFD_BRS" BO_ 1016 1;
BA_ "GenMsgCycleTime" BO_ 1016 500;
BA_ "GenMsgCycleTimeFast" BO_ 1016 0;
BA_ "GenMsgSendType" BO_ 1016 0;
BA_ "VFrameFormat" BO_ 1016 14;
BA_ "CANFD_BRS" BO_ 1016 1;
BA_ "GenMsgCycleTime" BO_ 1016 500;
BA_ "GenMsgCycleTimeFast" BO_ 1016 0;
BA_ "GenMsgSendType" BO_ 1016 0;
BA_ "VFrameFormat" BO_ 1016 14;
BA_ "CANFD_BRS" BO_ 1016 1;
BA_ "GenMsgCycleTime" BO_ 1016 500;
BA_ "GenMsgCycleTimeFast" BO_ 1016 0;
BA_ "GenMsgSendType" BO_ 1016 0;
BA_ "VFrameFormat" BO_ 1016 14;
BA_ "CANFD_BRS" BO_ 1016 1;
BA_ "GenMsgCycleTime" BO_ 1016 500;
BA_ "GenMsgCycleTimeFast" BO_ 1016 0;
BA_ "GenMsgSendType" BO_ 1016 0;
BA_ "VFrameFormat" BO_ 1016 14;
BA_ "CANFD_BRS" BO_ 1016 1;
BA_ "GenMsgCycleTime" BO_ 1016 500;
BA_ "GenMsgCycleTimeFast" BO_ 1016 0;
BA_ "GenMsgSendType" BO_ 1016 0;
BA_ "VFrameFormat" BO_ 1016 14;
BA_ "CANFD_BRS" BO_ 1016 1;
BA_ "GenMsgCycleTime" BO_ 1016 500;
BA_ "GenMsgCycleTimeFast" BO_ 1016 0;
BA_ "GenMsgSendType" BO_ 1016 0;
BA_ "VFrameFormat" BO_ 1016 14;
BA_ "CANFD_BRS" BO_ 1016 1;
BA_ "GenMsgCycleTime" BO_ 1016 500;
BA_ "GenMsgCycleTimeFast" BO_ 1016 0;
BA_ "GenMsgSendType" BO_ 1016 0;
BA_ "VFrameFormat" BO_ 1016 14;
BA_ "CANFD_BRS" BO_ 1016 1;
BA_ "GenMsgCycleTime" BO_ 1016 500;
BA_ "GenMsgCycleTimeFast" BO_ 1016 0;
BA_ "GenMsgSendType" BO_ 1016 0;
BA_ "VFrameFormat" BO_ 1016 14;
BA_ "CANFD_BRS" BO_ 1016 1;
BA_ "GenMsgCycleTime" BO_ 1016 500;
BA_ "GenMsgCycleTimeFast" BO_ 1016 0;
BA_ "GenMsgSendType" BO_ 1016 0;
BA_ "VFrameFormat" BO_ 1016 14;
BA_ "CANFD_BRS" BO_ 1016 1;
BA_ "GenMsgCycleTime" BO_ 1016 500;
BA_ "GenMsgCycleTimeFast" BO_ 1016 0;
BA_ "GenMsgSendType" BO_ 1016 0;
BA_ "VFrameFormat" BO_ 1016 14;
BA_ "CANFD_BRS" BO_ 1016 1;
BA_ "GenMsgCycleTime" BO_ 1016 500;
BA_ "GenMsgCycleTimeFast" BO_ 1016 0;
BA_ "GenMsgSendType" BO_ 1016 0;
BA_ "VFrameFormat" BO_ 1016 14;
BA_ "CANFD_BRS" BO_ 1016 1;
BA_ "GenMsgCycleTime" BO_ 1016 500;
BA_ "GenMsgCycleTimeFast" BO_ 1016 0;
BA_ "GenMsgSendType" BO_ 1016 0;
BA_ "VFrameFormat" BO_ 1016 14;
BA_ "CANFD_BRS" BO_ 1016 1;
BA_ "GenMsgCycleTime" BO_ 1016 500;
BA_ "GenMsgCycleTimeFast" BO_ 1016 0;
BA_ "GenMsgSendType" BO_ 1016 0;
BA_ "VFrameFormat" BO_ 1016 14;
BA_ "CANFD_BRS" BO_ 1016 1;
BA_ "GenMsgCycleTime" BO_ 1016 500;
BA_ "GenMsgCycleTimeFast" BO_ 1016 0;
BA_ "GenMsgSendType" BO_ 1016 0;
BA_ "VFrameFormat" BO_ 1016 14;
BA_ "CANFD_BRS" BO_ 1016 1;
BA_ "GenMsgCycleTime" BO_ 1016 500;
BA_ "GenMsgCycleTimeFast" BO_ 1016 0;
BA_ "GenMsgSendType" BO_ 1016 0;
BA_ "VFrameFormat" BO_ 1016 14;
BA_ "CANFD_BRS" BO_ 1016 1;
BA_ "GenMsgCycleTime" BO_ 1016 500;
BA_ "GenMsgCycleTimeFast" BO_ 1016 0;
BA_ "GenMsgSendType" BO_ 1016 0;
BA_ "VFrameFormat" BO_ 1016 14;
BA_ "CANFD_BRS" BO_ 1016 1;
BA_ "GenMsgCycleTime" BO_ 1016 500;
BA_ "GenMsgCycleTimeFast" BO_ 1016 0;
BA_ "GenMsgSendType" BO_ 1016 0;
BA_ "VFrameFormat" BO_ 1016 14;
BA_ "CANFD_BRS" BO_ 1016 1;
BA_ "GenMsgCycleTime" BO_ 1016 500;
BA_ "GenMsgCycleTimeFast" BO_ 1016 0;
BA_ "GenMsgSendType" BO_ 1016 0;
BA_ "VFrameFormat" BO_ 1016 14;
BA_ "CANFD_BRS" BO_ 1016 1;
BA_ "GenMsgCycleTime" BO_ 1016 500;
BA_ "GenMsgCycleTimeFast" BO_ 1016 0;
BA_ "GenMsgSendType" BO_ 1016 0;
BA_ "VFrameFormat" BO_ 1016 14;
BA_ "CANFD_BRS" BO_ 1016 1;
BA_ "GenMsgCycleTime" BO_ 1016 500;
BA_ "GenMsgCycleTimeFast" BO_ 1016 0;
BA_ "GenMsgSendType" BO_ 1016 0;
BA_ "VFrameFormat" BO_ 1016 14;
BA_ "CANFD_BRS" BO_ 1016 1;
BA_ "GenMsgCycleTime" BO_ 1016 500;
BA_ "GenMsgCycleTimeFast" BO_ 1016 0;
BA_ "GenMsgSendType" BO_ 1016 0;
BA_ "VFrameFormat" BO_ 1016 14;
BA_ "CANFD_BRS" BO_ 1016 1;
BA_ "GenMsgCycleTime" BO_ 1016 500;
BA_ "GenMsgCycleTimeFast" BO_ 1016 0;
BA_ "GenMsgSendType" BO_ 1016 0;
BA_ "VFrameFormat" BO_ 1016 14;
BA_ "CANFD_BRS" BO_ 1016 1;
BA_ "GenMsgCycleTime" BO_ 1016 500;
BA_ "GenMsgCycleTimeFast" BO_ 1016 0;
BA_ "GenMsgSendType" BO_ 1016 0;
BA_ "VFrameFormat" BO_ 1016 14;
BA_ "CANFD_BRS" BO_ 1016 1;
BA_ "GenMsgCycleTime" BO_ 1016 500;
BA_ "GenMsgCycleTimeFast" BO_ 1016 0;
BA_ "GenMsgSendType" BO_ 1016 0;
BA_ "VFrameFormat" BO_ 1016 14;
BA_ "CANFD_BRS" BO_ 1016 1;
BA_ "GenMsgCycleTime" BO_ 1016 500;
BA_ "GenMsgCycleTimeFast" BO_ 1016 0;
BA_ "GenMsgSendType" BO_ 1016 0;
BA_ "VFrameFormat" BO_ 1016 14;
BA_ "CANFD_BRS" BO_ 1016 1;
BA_ "GenMsgCycleTime" BO_ 1016 500;
BA_ "GenMsgCycleTimeFast" BO_ 1016 0;
BA_ "GenMsgSendType" BO_ 1016 0;
BA_ "VFrameFormat" BO_ 1016 14;
BA_ "CANFD_BRS" BO_ 1016 1;
BA_ "GenMsgCycleTime" BO_ 1016 500;
BA_ "GenMsgCycleTimeFast" BO_ 1016 0;
BA_ "GenMsgSendType" BO_ 1016 0;
BA_ "VFrameFormat" BO_ 1016 14;
BA_ "CANFD_BRS" BO_ 1016 1;
BA_ "GenMsgCycleTime" BO_ 1016 500;
BA_ "GenMsgCycleTimeFast" BO_ 1016 0;
BA_ "GenMsgSendType" BO_ 1016 0;
BA_ "VFrameFormat" BO_ 1016 14;
BA_ "CANFD_BRS" BO_ 1016 1;
BA_ "GenMsgCycleTime" BO_ 1016 500;
BA_ "GenMsgCycleTimeFast" BO_ 1016 0;
BA_ "GenMsgSendType" BO_ 1016 0;
BA_ "VFrameFormat" BO_ 1016 14;
BA_ "CANFD_BRS" BO_ 1016 1;
BA_ "GenMsgCycleTime" BO_ 1016 500;
BA_ "GenMsgCycleTimeFast" BO_ 1016 0;
BA_ "GenMsgSendType" BO_ 1016 0;
BA_ "VFrameFormat" BO_ 1016 14;
BA_ "CANFD_BRS" BO_ 1016 1;
BA_ "GenMsgCycleTime" BO_ 1016 500;
BA_ "GenMsgCycleTimeFast" BO_ 1016 0;
BA_ "GenMsgSendType" BO_ 1016 0;
BA_ "VFrameFormat" BO_ 1016 14;
BA_ "CANFD_BRS" BO_ 1016 1;
BA_ "GenMsgCycleTime" BO_ 1016 500;
BA_ "GenMsgCycleTimeFast" BO_ 1016 0;
BA_ "GenMsgSendType" BO_ 1016 0;
BA_ "VFrameFormat" BO_ 1016 14;
BA_ "CANFD_BRS" BO_ 1016 1;
BA_ "GenMsgCycleTime" BO_ 1016 500;
BA_ "GenMsgCycleTimeFast" BO_ 1016 0;
BA_ "GenMsgSendType" BO_ 1016 0;
BA_ "VFrameFormat" BO_ 1016 14;
BA_ "CANFD_BRS" BO_ 1016 1;
BA_ "GenMsgCycleTime" BO_ 794 100;
BA_ "GenMsgCycleTimeFast" BO_ 794 0;
BA_ "GenMsgSendType" BO_ 794 0;
BA_ "VFrameFormat" BO_ 794 14;
BA_ "CANFD_BRS" BO_ 794 1;
BA_ "GenMsgCycleTime" BO_ 794 100;
BA_ "GenMsgCycleTimeFast" BO_ 794 0;
BA_ "GenMsgSendType" BO_ 794 0;
BA_ "VFrameFormat" BO_ 794 14;
BA_ "CANFD_BRS" BO_ 794 1;
BA_ "GenMsgCycleTime" BO_ 794 100;
BA_ "GenMsgCycleTimeFast" BO_ 794 0;
BA_ "GenMsgSendType" BO_ 794 0;
BA_ "VFrameFormat" BO_ 794 14;
BA_ "CANFD_BRS" BO_ 794 1;
BA_ "GenMsgCycleTime" BO_ 794 100;
BA_ "GenMsgCycleTimeFast" BO_ 794 0;
BA_ "GenMsgSendType" BO_ 794 0;
BA_ "VFrameFormat" BO_ 794 14;
BA_ "CANFD_BRS" BO_ 794 1;
BA_ "GenMsgCycleTime" BO_ 794 100;
BA_ "GenMsgCycleTimeFast" BO_ 794 0;
BA_ "GenMsgSendType" BO_ 794 0;
BA_ "VFrameFormat" BO_ 794 14;
BA_ "CANFD_BRS" BO_ 794 1;
BA_ "GenMsgCycleTime" BO_ 794 100;
BA_ "GenMsgCycleTimeFast" BO_ 794 0;
BA_ "GenMsgSendType" BO_ 794 0;
BA_ "VFrameFormat" BO_ 794 14;
BA_ "CANFD_BRS" BO_ 794 1;
BA_ "GenMsgCycleTime" BO_ 794 100;
BA_ "GenMsgCycleTimeFast" BO_ 794 0;
BA_ "GenMsgSendType" BO_ 794 0;
BA_ "VFrameFormat" BO_ 794 14;
BA_ "CANFD_BRS" BO_ 794 1;
BA_ "GenMsgCycleTime" BO_ 794 100;
BA_ "GenMsgCycleTimeFast" BO_ 794 0;
BA_ "GenMsgSendType" BO_ 794 0;
BA_ "VFrameFormat" BO_ 794 14;
BA_ "CANFD_BRS" BO_ 794 1;
BA_ "GenMsgCycleTime" BO_ 794 100;
BA_ "GenMsgCycleTimeFast" BO_ 794 0;
BA_ "GenMsgSendType" BO_ 794 0;
BA_ "VFrameFormat" BO_ 794 14;
BA_ "CANFD_BRS" BO_ 794 1;
BA_ "GenMsgCycleTime" BO_ 794 100;
BA_ "GenMsgCycleTimeFast" BO_ 794 0;
BA_ "GenMsgSendType" BO_ 794 0;
BA_ "VFrameFormat" BO_ 794 14;
BA_ "CANFD_BRS" BO_ 794 1;
BA_ "GenMsgCycleTime" BO_ 794 100;
BA_ "GenMsgCycleTimeFast" BO_ 794 0;
BA_ "GenMsgSendType" BO_ 794 0;
BA_ "VFrameFormat" BO_ 794 14;
BA_ "CANFD_BRS" BO_ 794 1;
BA_ "GenMsgCycleTime" BO_ 794 100;
BA_ "GenMsgCycleTimeFast" BO_ 794 0;
BA_ "GenMsgSendType" BO_ 794 0;
BA_ "VFrameFormat" BO_ 794 14;
BA_ "CANFD_BRS" BO_ 794 1;
BA_ "GenMsgCycleTime" BO_ 794 100;
BA_ "GenMsgCycleTimeFast" BO_ 794 0;
BA_ "GenMsgSendType" BO_ 794 0;
BA_ "VFrameFormat" BO_ 794 14;
BA_ "CANFD_BRS" BO_ 794 1;
BA_ "GenMsgCycleTime" BO_ 794 100;
BA_ "GenMsgCycleTimeFast" BO_ 794 0;
BA_ "GenMsgSendType" BO_ 794 0;
BA_ "VFrameFormat" BO_ 794 14;
BA_ "CANFD_BRS" BO_ 794 1;
BA_ "GenMsgCycleTime" BO_ 794 100;
BA_ "GenMsgCycleTimeFast" BO_ 794 0;
BA_ "GenMsgSendType" BO_ 794 0;
BA_ "VFrameFormat" BO_ 794 14;
BA_ "CANFD_BRS" BO_ 794 1;
BA_ "GenMsgCycleTime" BO_ 974 500;
BA_ "GenMsgCycleTimeFast" BO_ 974 0;
BA_ "GenMsgSendType" BO_ 974 0;
BA_ "VFrameFormat" BO_ 974 14;
BA_ "CANFD_BRS" BO_ 974 1;
BA_ "GenMsgCycleTime" BO_ 974 500;
BA_ "GenMsgCycleTimeFast" BO_ 974 0;
BA_ "GenMsgSendType" BO_ 974 0;
BA_ "VFrameFormat" BO_ 974 14;
BA_ "CANFD_BRS" BO_ 974 1;
BA_ "GenMsgCycleTime" BO_ 974 500;
BA_ "GenMsgCycleTimeFast" BO_ 974 0;
BA_ "GenMsgSendType" BO_ 974 0;
BA_ "VFrameFormat" BO_ 974 14;
BA_ "CANFD_BRS" BO_ 974 1;
BA_ "GenMsgCycleTime" BO_ 974 500;
BA_ "GenMsgCycleTimeFast" BO_ 974 0;
BA_ "GenMsgSendType" BO_ 974 0;
BA_ "VFrameFormat" BO_ 974 14;
BA_ "CANFD_BRS" BO_ 974 1;
BA_ "GenMsgCycleTime" BO_ 974 500;
BA_ "GenMsgCycleTimeFast" BO_ 974 0;
BA_ "GenMsgSendType" BO_ 974 0;
BA_ "VFrameFormat" BO_ 974 14;
BA_ "CANFD_BRS" BO_ 974 1;
BA_ "GenMsgCycleTime" BO_ 974 500;
BA_ "GenMsgCycleTimeFast" BO_ 974 0;
BA_ "GenMsgSendType" BO_ 974 0;
BA_ "VFrameFormat" BO_ 974 14;
BA_ "CANFD_BRS" BO_ 974 1;
BA_ "GenMsgCycleTime" BO_ 974 500;
BA_ "GenMsgCycleTimeFast" BO_ 974 0;
BA_ "GenMsgSendType" BO_ 974 0;
BA_ "VFrameFormat" BO_ 974 14;
BA_ "CANFD_BRS" BO_ 974 1;
BA_ "GenMsgCycleTime" BO_ 974 500;
BA_ "GenMsgCycleTimeFast" BO_ 974 0;
BA_ "GenMsgSendType" BO_ 974 0;
BA_ "VFrameFormat" BO_ 974 14;
BA_ "CANFD_BRS" BO_ 974 1;
BA_ "GenMsgCycleTime" BO_ 974 500;
BA_ "GenMsgCycleTimeFast" BO_ 974 0;
BA_ "GenMsgSendType" BO_ 974 0;
BA_ "VFrameFormat" BO_ 974 14;
BA_ "CANFD_BRS" BO_ 974 1;
BA_ "GenMsgCycleTime" BO_ 974 500;
BA_ "GenMsgCycleTimeFast" BO_ 974 0;
BA_ "GenMsgSendType" BO_ 974 0;
BA_ "VFrameFormat" BO_ 974 14;
BA_ "CANFD_BRS" BO_ 974 1;
BA_ "GenMsgCycleTime" BO_ 974 500;
BA_ "GenMsgCycleTimeFast" BO_ 974 0;
BA_ "GenMsgSendType" BO_ 974 0;
BA_ "VFrameFormat" BO_ 974 14;
BA_ "CANFD_BRS" BO_ 974 1;
BA_ "GenMsgCycleTime" BO_ 974 500;
BA_ "GenMsgCycleTimeFast" BO_ 974 0;
BA_ "GenMsgSendType" BO_ 974 0;
BA_ "VFrameFormat" BO_ 974 14;
BA_ "CANFD_BRS" BO_ 974 1;
BA_ "GenMsgCycleTime" BO_ 974 500;
BA_ "GenMsgCycleTimeFast" BO_ 974 0;
BA_ "GenMsgSendType" BO_ 974 0;
BA_ "VFrameFormat" BO_ 974 14;
BA_ "CANFD_BRS" BO_ 974 1;
BA_ "GenMsgCycleTime" BO_ 974 500;
BA_ "GenMsgCycleTimeFast" BO_ 974 0;
BA_ "GenMsgSendType" BO_ 974 0;
BA_ "VFrameFormat" BO_ 974 14;
BA_ "CANFD_BRS" BO_ 974 1;
BA_ "GenMsgCycleTime" BO_ 1316 200;
BA_ "GenMsgCycleTimeFast" BO_ 1316 0;
BA_ "GenMsgSendType" BO_ 1316 0;
BA_ "VFrameFormat" BO_ 1316 0;
BA_ "CANFD_BRS" BO_ 1316 1;
BA_ "GenMsgCycleTime" BO_ 1316 200;
BA_ "GenMsgCycleTimeFast" BO_ 1316 0;
BA_ "GenMsgSendType" BO_ 1316 0;
BA_ "VFrameFormat" BO_ 1316 0;
BA_ "CANFD_BRS" BO_ 1316 1;
BA_ "GenMsgCycleTime" BO_ 1316 200;
BA_ "GenMsgCycleTimeFast" BO_ 1316 0;
BA_ "GenMsgSendType" BO_ 1316 0;
BA_ "VFrameFormat" BO_ 1316 0;
BA_ "CANFD_BRS" BO_ 1316 1;
BA_ "GenMsgCycleTime" BO_ 1316 200;
BA_ "GenMsgCycleTimeFast" BO_ 1316 0;
BA_ "GenMsgSendType" BO_ 1316 0;
BA_ "VFrameFormat" BO_ 1316 0;
BA_ "CANFD_BRS" BO_ 1316 1;
BA_ "GenMsgCycleTime" BO_ 1316 200;
BA_ "GenMsgCycleTimeFast" BO_ 1316 0;
BA_ "GenMsgSendType" BO_ 1316 0;
BA_ "VFrameFormat" BO_ 1316 0;
BA_ "CANFD_BRS" BO_ 1316 1;
BA_ "GenMsgCycleTime" BO_ 1316 200;
BA_ "GenMsgCycleTimeFast" BO_ 1316 0;
BA_ "GenMsgSendType" BO_ 1316 0;
BA_ "VFrameFormat" BO_ 1316 0;
BA_ "CANFD_BRS" BO_ 1316 1;
BA_ "GenMsgCycleTime" BO_ 387 10;
BA_ "GenMsgCycleTimeFast" BO_ 387 0;
BA_ "GenMsgSendType" BO_ 387 0;
BA_ "VFrameFormat" BO_ 387 14;
BA_ "CANFD_BRS" BO_ 387 1;
BA_ "GenMsgCycleTime" BO_ 387 10;
BA_ "GenMsgCycleTimeFast" BO_ 387 0;
BA_ "GenMsgSendType" BO_ 387 0;
BA_ "VFrameFormat" BO_ 387 14;
BA_ "CANFD_BRS" BO_ 387 1;
BA_ "GenMsgCycleTime" BO_ 387 10;
BA_ "GenMsgCycleTimeFast" BO_ 387 0;
BA_ "GenMsgSendType" BO_ 387 0;
BA_ "VFrameFormat" BO_ 387 14;
BA_ "CANFD_BRS" BO_ 387 1;
BA_ "EventCommandSignal" SG_ 1016 LBMS_UnSfLoadCurrent 0;
BA_ "GatewayedSignals" SG_ 1016 LBMS_UnSfLoadCurrent 0;
BA_ "GenSigInactiveValue" SG_ 1016 LBMS_UnSfLoadCurrent 0;
BA_ "GenSigInvalidValue" SG_ 1016 LBMS_UnSfLoadCurrent 0;
BA_ "GenSigSendType" SG_ 1016 LBMS_UnSfLoadCurrent 1;
BA_ "GenSigStartValue" SG_ 1016 LBMS_UnSfLoadCurrent 4194303;
BA_ "GenSigTimeoutValue" SG_ 1016 LBMS_UnSfLoadCurrent 0;
BA_ "Remark" SG_ 1016 LBMS_UnSfLoadCurrent "";
BA_ "EventCommandSignal" SG_ 1016 LBMS_UnSftyLoadCurrentVD 0;
BA_ "GatewayedSignals" SG_ 1016 LBMS_UnSftyLoadCurrentVD 0;
BA_ "GenSigInactiveValue" SG_ 1016 LBMS_UnSftyLoadCurrentVD 0;
BA_ "GenSigInvalidValue" SG_ 1016 LBMS_UnSftyLoadCurrentVD 0;
BA_ "GenSigSendType" SG_ 1016 LBMS_UnSftyLoadCurrentVD 1;
BA_ "GenSigStartValue" SG_ 1016 LBMS_UnSftyLoadCurrentVD 0;
BA_ "GenSigTimeoutValue" SG_ 1016 LBMS_UnSftyLoadCurrentVD 0;
BA_ "Remark" SG_ 1016 LBMS_UnSftyLoadCurrentVD "";
BA_ "EventCommandSignal" SG_ 1016 LBMS_SfLoadCurrent 0;
BA_ "GatewayedSignals" SG_ 1016 LBMS_SfLoadCurrent 0;
BA_ "GenSigInactiveValue" SG_ 1016 LBMS_SfLoadCurrent 0;
BA_ "GenSigInvalidValue" SG_ 1016 LBMS_SfLoadCurrent 0;
BA_ "GenSigSendType" SG_ 1016 LBMS_SfLoadCurrent 1;
BA_ "GenSigStartValue" SG_ 1016 LBMS_SfLoadCurrent 4194303;
BA_ "GenSigTimeoutValue" SG_ 1016 LBMS_SfLoadCurrent 0;
BA_ "Remark" SG_ 1016 LBMS_SfLoadCurrent "";
BA_ "EventCommandSignal" SG_ 1016 LBMS_SfLoadCurrentVD 0;
BA_ "GatewayedSignals" SG_ 1016 LBMS_SfLoadCurrentVD 0;
BA_ "GenSigInactiveValue" SG_ 1016 LBMS_SfLoadCurrentVD 0;
BA_ "GenSigInvalidValue" SG_ 1016 LBMS_SfLoadCurrentVD 0;
BA_ "GenSigSendType" SG_ 1016 LBMS_SfLoadCurrentVD 1;
BA_ "GenSigStartValue" SG_ 1016 LBMS_SfLoadCurrentVD 0;
BA_ "GenSigTimeoutValue" SG_ 1016 LBMS_SfLoadCurrentVD 0;
BA_ "Remark" SG_ 1016 LBMS_SfLoadCurrentVD "";
BA_ "EventCommandSignal" SG_ 1016 LBMS_ComSoVolt 0;
BA_ "GatewayedSignals" SG_ 1016 LBMS_ComSoVolt 0;
BA_ "GenSigInactiveValue" SG_ 1016 LBMS_ComSoVolt 0;
BA_ "GenSigInvalidValue" SG_ 1016 LBMS_ComSoVolt 0;
BA_ "GenSigSendType" SG_ 1016 LBMS_ComSoVolt 1;
BA_ "GenSigStartValue" SG_ 1016 LBMS_ComSoVolt 4095;
BA_ "GenSigTimeoutValue" SG_ 1016 LBMS_ComSoVolt 0;
BA_ "Remark" SG_ 1016 LBMS_ComSoVolt "";
BA_ "EventCommandSignal" SG_ 1016 LBMS_ComSoVoltVD 0;
BA_ "GatewayedSignals" SG_ 1016 LBMS_ComSoVoltVD 0;
BA_ "GenSigInactiveValue" SG_ 1016 LBMS_ComSoVoltVD 0;
BA_ "GenSigInvalidValue" SG_ 1016 LBMS_ComSoVoltVD 0;
BA_ "GenSigSendType" SG_ 1016 LBMS_ComSoVoltVD 1;
BA_ "GenSigStartValue" SG_ 1016 LBMS_ComSoVoltVD 0;
BA_ "GenSigTimeoutValue" SG_ 1016 LBMS_ComSoVoltVD 0;
BA_ "Remark" SG_ 1016 LBMS_ComSoVoltVD "";
BA_ "EventCommandSignal" SG_ 1016 LBMS_UnSfLoadComSoVolt 0;
BA_ "GatewayedSignals" SG_ 1016 LBMS_UnSfLoadComSoVolt 0;
BA_ "GenSigInactiveValue" SG_ 1016 LBMS_UnSfLoadComSoVolt 0;
BA_ "GenSigInvalidValue" SG_ 1016 LBMS_UnSfLoadComSoVolt 0;
BA_ "GenSigSendType" SG_ 1016 LBMS_UnSfLoadComSoVolt 1;
BA_ "GenSigStartValue" SG_ 1016 LBMS_UnSfLoadComSoVolt 4095;
BA_ "GenSigTimeoutValue" SG_ 1016 LBMS_UnSfLoadComSoVolt 0;
BA_ "Remark" SG_ 1016 LBMS_UnSfLoadComSoVolt "";
BA_ "EventCommandSignal" SG_ 1016 LBMS_UnSfLoadComSoVoltVD 0;
BA_ "GatewayedSignals" SG_ 1016 LBMS_UnSfLoadComSoVoltVD 0;
BA_ "GenSigInactiveValue" SG_ 1016 LBMS_UnSfLoadComSoVoltVD 0;
BA_ "GenSigInvalidValue" SG_ 1016 LBMS_UnSfLoadComSoVoltVD 0;
BA_ "GenSigSendType" SG_ 1016 LBMS_UnSfLoadComSoVoltVD 1;
BA_ "GenSigStartValue" SG_ 1016 LBMS_UnSfLoadComSoVoltVD 0;
BA_ "GenSigTimeoutValue" SG_ 1016 LBMS_UnSfLoadComSoVoltVD 0;
BA_ "Remark" SG_ 1016 LBMS_UnSfLoadComSoVoltVD "";
BA_ "EventCommandSignal" SG_ 1016 LBMS_UnsfLoadMosst 0;
BA_ "GatewayedSignals" SG_ 1016 LBMS_UnsfLoadMosst 0;
BA_ "GenSigInactiveValue" SG_ 1016 LBMS_UnsfLoadMosst 0;
BA_ "GenSigInvalidValue" SG_ 1016 LBMS_UnsfLoadMosst 0;
BA_ "GenSigSendType" SG_ 1016 LBMS_UnsfLoadMosst 1;
BA_ "GenSigStartValue" SG_ 1016 LBMS_UnsfLoadMosst 7;
BA_ "GenSigTimeoutValue" SG_ 1016 LBMS_UnsfLoadMosst 0;
BA_ "Remark" SG_ 1016 LBMS_UnsfLoadMosst "";
BA_ "EventCommandSignal" SG_ 1016 LBMS_UnSfLoadMosTemp1 0;
BA_ "GatewayedSignals" SG_ 1016 LBMS_UnSfLoadMosTemp1 0;
BA_ "GenSigInactiveValue" SG_ 1016 LBMS_UnSfLoadMosTemp1 0;
BA_ "GenSigInvalidValue" SG_ 1016 LBMS_UnSfLoadMosTemp1 0;
BA_ "GenSigSendType" SG_ 1016 LBMS_UnSfLoadMosTemp1 1;
BA_ "GenSigStartValue" SG_ 1016 LBMS_UnSfLoadMosTemp1 255;
BA_ "GenSigTimeoutValue" SG_ 1016 LBMS_UnSfLoadMosTemp1 0;
BA_ "Remark" SG_ 1016 LBMS_UnSfLoadMosTemp1 "";
BA_ "EventCommandSignal" SG_ 1016 LBMS_UnSfLoadMosTemp1VD 0;
BA_ "GatewayedSignals" SG_ 1016 LBMS_UnSfLoadMosTemp1VD 0;
BA_ "GenSigInactiveValue" SG_ 1016 LBMS_UnSfLoadMosTemp1VD 0;
BA_ "GenSigInvalidValue" SG_ 1016 LBMS_UnSfLoadMosTemp1VD 0;
BA_ "GenSigSendType" SG_ 1016 LBMS_UnSfLoadMosTemp1VD 1;
BA_ "GenSigStartValue" SG_ 1016 LBMS_UnSfLoadMosTemp1VD 0;
BA_ "GenSigTimeoutValue" SG_ 1016 LBMS_UnSfLoadMosTemp1VD 0;
BA_ "Remark" SG_ 1016 LBMS_UnSfLoadMosTemp1VD "";
BA_ "EventCommandSignal" SG_ 1016 LBMS_UnSfLoadMosTemp2 0;
BA_ "GatewayedSignals" SG_ 1016 LBMS_UnSfLoadMosTemp2 0;
BA_ "GenSigInactiveValue" SG_ 1016 LBMS_UnSfLoadMosTemp2 0;
BA_ "GenSigInvalidValue" SG_ 1016 LBMS_UnSfLoadMosTemp2 0;
BA_ "GenSigSendType" SG_ 1016 LBMS_UnSfLoadMosTemp2 1;
BA_ "GenSigStartValue" SG_ 1016 LBMS_UnSfLoadMosTemp2 255;
BA_ "GenSigTimeoutValue" SG_ 1016 LBMS_UnSfLoadMosTemp2 0;
BA_ "Remark" SG_ 1016 LBMS_UnSfLoadMosTemp2 "";
BA_ "EventCommandSignal" SG_ 1016 LBMS_UnSfLoadMosTemp2VD 0;
BA_ "GatewayedSignals" SG_ 1016 LBMS_UnSfLoadMosTemp2VD 0;
BA_ "GenSigInactiveValue" SG_ 1016 LBMS_UnSfLoadMosTemp2VD 0;
BA_ "GenSigInvalidValue" SG_ 1016 LBMS_UnSfLoadMosTemp2VD 0;
BA_ "GenSigSendType" SG_ 1016 LBMS_UnSfLoadMosTemp2VD 1;
BA_ "GenSigStartValue" SG_ 1016 LBMS_UnSfLoadMosTemp2VD 0;
BA_ "GenSigTimeoutValue" SG_ 1016 LBMS_UnSfLoadMosTemp2VD 0;
BA_ "Remark" SG_ 1016 LBMS_UnSfLoadMosTemp2VD "";
BA_ "EventCommandSignal" SG_ 1016 LBMS_UnSfLoadShuntTemp 0;
BA_ "GatewayedSignals" SG_ 1016 LBMS_UnSfLoadShuntTemp 0;
BA_ "GenSigInactiveValue" SG_ 1016 LBMS_UnSfLoadShuntTemp 0;
BA_ "GenSigInvalidValue" SG_ 1016 LBMS_UnSfLoadShuntTemp 0;
BA_ "GenSigSendType" SG_ 1016 LBMS_UnSfLoadShuntTemp 1;
BA_ "GenSigStartValue" SG_ 1016 LBMS_UnSfLoadShuntTemp 255;
BA_ "GenSigTimeoutValue" SG_ 1016 LBMS_UnSfLoadShuntTemp 0;
BA_ "Remark" SG_ 1016 LBMS_UnSfLoadShuntTemp "";
BA_ "EventCommandSignal" SG_ 1016 LBMS_UnSfLoadShuntTempVD 0;
BA_ "GatewayedSignals" SG_ 1016 LBMS_UnSfLoadShuntTempVD 0;
BA_ "GenSigInactiveValue" SG_ 1016 LBMS_UnSfLoadShuntTempVD 0;
BA_ "GenSigInvalidValue" SG_ 1016 LBMS_UnSfLoadShuntTempVD 0;
BA_ "GenSigSendType" SG_ 1016 LBMS_UnSfLoadShuntTempVD 1;
BA_ "GenSigStartValue" SG_ 1016 LBMS_UnSfLoadShuntTempVD 0;
BA_ "GenSigTimeoutValue" SG_ 1016 LBMS_UnSfLoadShuntTempVD 0;
BA_ "Remark" SG_ 1016 LBMS_UnSfLoadShuntTempVD "";
BA_ "EventCommandSignal" SG_ 1016 LBMS_SfLoadShuntTemp 0;
BA_ "GatewayedSignals" SG_ 1016 LBMS_SfLoadShuntTemp 0;
BA_ "GenSigInactiveValue" SG_ 1016 LBMS_SfLoadShuntTemp 0;
BA_ "GenSigInvalidValue" SG_ 1016 LBMS_SfLoadShuntTemp 0;
BA_ "GenSigSendType" SG_ 1016 LBMS_SfLoadShuntTemp 1;
BA_ "GenSigStartValue" SG_ 1016 LBMS_SfLoadShuntTemp 255;
BA_ "GenSigTimeoutValue" SG_ 1016 LBMS_SfLoadShuntTemp 0;
BA_ "Remark" SG_ 1016 LBMS_SfLoadShuntTemp "";
BA_ "EventCommandSignal" SG_ 1016 LBMS_SfLoadShuntTempVD 0;
BA_ "GatewayedSignals" SG_ 1016 LBMS_SfLoadShuntTempVD 0;
BA_ "GenSigInactiveValue" SG_ 1016 LBMS_SfLoadShuntTempVD 0;
BA_ "GenSigInvalidValue" SG_ 1016 LBMS_SfLoadShuntTempVD 0;
BA_ "GenSigSendType" SG_ 1016 LBMS_SfLoadShuntTempVD 1;
BA_ "GenSigStartValue" SG_ 1016 LBMS_SfLoadShuntTempVD 0;
BA_ "GenSigTimeoutValue" SG_ 1016 LBMS_SfLoadShuntTempVD 0;
BA_ "Remark" SG_ 1016 LBMS_SfLoadShuntTempVD "";
BA_ "EventCommandSignal" SG_ 1016 LBMS_UnSfLoadChgMosDrvVolt 0;
BA_ "GatewayedSignals" SG_ 1016 LBMS_UnSfLoadChgMosDrvVolt 0;
BA_ "GenSigInactiveValue" SG_ 1016 LBMS_UnSfLoadChgMosDrvVolt 0;
BA_ "GenSigInvalidValue" SG_ 1016 LBMS_UnSfLoadChgMosDrvVolt 0;
BA_ "GenSigSendType" SG_ 1016 LBMS_UnSfLoadChgMosDrvVolt 1;
BA_ "GenSigStartValue" SG_ 1016 LBMS_UnSfLoadChgMosDrvVolt 4095;
BA_ "GenSigTimeoutValue" SG_ 1016 LBMS_UnSfLoadChgMosDrvVolt 0;
BA_ "Remark" SG_ 1016 LBMS_UnSfLoadChgMosDrvVolt "";
BA_ "EventCommandSignal" SG_ 1016 LBMS_UnSfLoadChgMosDrvVoltVD 0;
BA_ "GatewayedSignals" SG_ 1016 LBMS_UnSfLoadChgMosDrvVoltVD 0;
BA_ "GenSigInactiveValue" SG_ 1016 LBMS_UnSfLoadChgMosDrvVoltVD 0;
BA_ "GenSigInvalidValue" SG_ 1016 LBMS_UnSfLoadChgMosDrvVoltVD 0;
BA_ "GenSigSendType" SG_ 1016 LBMS_UnSfLoadChgMosDrvVoltVD 1;
BA_ "GenSigStartValue" SG_ 1016 LBMS_UnSfLoadChgMosDrvVoltVD 0;
BA_ "GenSigTimeoutValue" SG_ 1016 LBMS_UnSfLoadChgMosDrvVoltVD 0;
BA_ "Remark" SG_ 1016 LBMS_UnSfLoadChgMosDrvVoltVD "";
BA_ "EventCommandSignal" SG_ 1016 LBMS_UnSfLoadDsgMosDrvVolt 0;
BA_ "GatewayedSignals" SG_ 1016 LBMS_UnSfLoadDsgMosDrvVolt 0;
BA_ "GenSigInactiveValue" SG_ 1016 LBMS_UnSfLoadDsgMosDrvVolt 0;
BA_ "GenSigInvalidValue" SG_ 1016 LBMS_UnSfLoadDsgMosDrvVolt 0;
BA_ "GenSigSendType" SG_ 1016 LBMS_UnSfLoadDsgMosDrvVolt 1;
BA_ "GenSigStartValue" SG_ 1016 LBMS_UnSfLoadDsgMosDrvVolt 4095;
BA_ "GenSigTimeoutValue" SG_ 1016 LBMS_UnSfLoadDsgMosDrvVolt 0;
BA_ "Remark" SG_ 1016 LBMS_UnSfLoadDsgMosDrvVolt "";
BA_ "EventCommandSignal" SG_ 1016 LBMS_UnSfLoadDsgMosDrvVoltVD 0;
BA_ "GatewayedSignals" SG_ 1016 LBMS_UnSfLoadDsgMosDrvVoltVD 0;
BA_ "GenSigInactiveValue" SG_ 1016 LBMS_UnSfLoadDsgMosDrvVoltVD 0;
BA_ "GenSigInvalidValue" SG_ 1016 LBMS_UnSfLoadDsgMosDrvVoltVD 0;
BA_ "GenSigSendType" SG_ 1016 LBMS_UnSfLoadDsgMosDrvVoltVD 1;
BA_ "GenSigStartValue" SG_ 1016 LBMS_UnSfLoadDsgMosDrvVoltVD 0;
BA_ "GenSigTimeoutValue" SG_ 1016 LBMS_UnSfLoadDsgMosDrvVoltVD 0;
BA_ "Remark" SG_ 1016 LBMS_UnSfLoadDsgMosDrvVoltVD "";
BA_ "EventCommandSignal" SG_ 1016 LBMS_ChgMosDrvVolt 0;
BA_ "GatewayedSignals" SG_ 1016 LBMS_ChgMosDrvVolt 0;
BA_ "GenSigInactiveValue" SG_ 1016 LBMS_ChgMosDrvVolt 0;
BA_ "GenSigInvalidValue" SG_ 1016 LBMS_ChgMosDrvVolt 0;
BA_ "GenSigSendType" SG_ 1016 LBMS_ChgMosDrvVolt 1;
BA_ "GenSigStartValue" SG_ 1016 LBMS_ChgMosDrvVolt 4095;
BA_ "GenSigTimeoutValue" SG_ 1016 LBMS_ChgMosDrvVolt 0;
BA_ "Remark" SG_ 1016 LBMS_ChgMosDrvVolt "";
BA_ "EventCommandSignal" SG_ 1016 LBMS_ChgMosDrvVoltVD 0;
BA_ "GatewayedSignals" SG_ 1016 LBMS_ChgMosDrvVoltVD 0;
BA_ "GenSigInactiveValue" SG_ 1016 LBMS_ChgMosDrvVoltVD 0;
BA_ "GenSigInvalidValue" SG_ 1016 LBMS_ChgMosDrvVoltVD 0;
BA_ "GenSigSendType" SG_ 1016 LBMS_ChgMosDrvVoltVD 1;
BA_ "GenSigStartValue" SG_ 1016 LBMS_ChgMosDrvVoltVD 0;
BA_ "GenSigTimeoutValue" SG_ 1016 LBMS_ChgMosDrvVoltVD 0;
BA_ "Remark" SG_ 1016 LBMS_ChgMosDrvVoltVD "";
BA_ "EventCommandSignal" SG_ 1016 LBMS_DsgMosDrvVolt 0;
BA_ "GatewayedSignals" SG_ 1016 LBMS_DsgMosDrvVolt 0;
BA_ "GenSigInactiveValue" SG_ 1016 LBMS_DsgMosDrvVolt 0;
BA_ "GenSigInvalidValue" SG_ 1016 LBMS_DsgMosDrvVolt 0;
BA_ "GenSigSendType" SG_ 1016 LBMS_DsgMosDrvVolt 1;
BA_ "GenSigStartValue" SG_ 1016 LBMS_DsgMosDrvVolt 4095;
BA_ "GenSigTimeoutValue" SG_ 1016 LBMS_DsgMosDrvVolt 0;
BA_ "Remark" SG_ 1016 LBMS_DsgMosDrvVolt "";
BA_ "EventCommandSignal" SG_ 1016 LBMS_DsgMosDrvVoltVD 0;
BA_ "GatewayedSignals" SG_ 1016 LBMS_DsgMosDrvVoltVD 0;
BA_ "GenSigInactiveValue" SG_ 1016 LBMS_DsgMosDrvVoltVD 0;
BA_ "GenSigInvalidValue" SG_ 1016 LBMS_DsgMosDrvVoltVD 0;
BA_ "GenSigSendType" SG_ 1016 LBMS_DsgMosDrvVoltVD 1;
BA_ "GenSigStartValue" SG_ 1016 LBMS_DsgMosDrvVoltVD 0;
BA_ "GenSigTimeoutValue" SG_ 1016 LBMS_DsgMosDrvVoltVD 0;
BA_ "Remark" SG_ 1016 LBMS_DsgMosDrvVoltVD "";
BA_ "EventCommandSignal" SG_ 1016 LBMS_UnSfLoadFaultOTMOS 0;
BA_ "GatewayedSignals" SG_ 1016 LBMS_UnSfLoadFaultOTMOS 0;
BA_ "GenSigInactiveValue" SG_ 1016 LBMS_UnSfLoadFaultOTMOS 0;
BA_ "GenSigInvalidValue" SG_ 1016 LBMS_UnSfLoadFaultOTMOS 0;
BA_ "GenSigSendType" SG_ 1016 LBMS_UnSfLoadFaultOTMOS 1;
BA_ "GenSigStartValue" SG_ 1016 LBMS_UnSfLoadFaultOTMOS 0;
BA_ "GenSigTimeoutValue" SG_ 1016 LBMS_UnSfLoadFaultOTMOS 0;
BA_ "Remark" SG_ 1016 LBMS_UnSfLoadFaultOTMOS "";
BA_ "EventCommandSignal" SG_ 1016 LBMS_UnSfLoadFaultOTS 0;
BA_ "GatewayedSignals" SG_ 1016 LBMS_UnSfLoadFaultOTS 0;
BA_ "GenSigInactiveValue" SG_ 1016 LBMS_UnSfLoadFaultOTS 0;
BA_ "GenSigInvalidValue" SG_ 1016 LBMS_UnSfLoadFaultOTS 0;
BA_ "GenSigSendType" SG_ 1016 LBMS_UnSfLoadFaultOTS 1;
BA_ "GenSigStartValue" SG_ 1016 LBMS_UnSfLoadFaultOTS 0;
BA_ "GenSigTimeoutValue" SG_ 1016 LBMS_UnSfLoadFaultOTS 0;
BA_ "Remark" SG_ 1016 LBMS_UnSfLoadFaultOTS "";
BA_ "EventCommandSignal" SG_ 1016 LBMS_SfLoadFaultOTS 0;
BA_ "GatewayedSignals" SG_ 1016 LBMS_SfLoadFaultOTS 0;
BA_ "GenSigInactiveValue" SG_ 1016 LBMS_SfLoadFaultOTS 0;
BA_ "GenSigInvalidValue" SG_ 1016 LBMS_SfLoadFaultOTS 0;
BA_ "GenSigSendType" SG_ 1016 LBMS_SfLoadFaultOTS 1;
BA_ "GenSigStartValue" SG_ 1016 LBMS_SfLoadFaultOTS 0;
BA_ "GenSigTimeoutValue" SG_ 1016 LBMS_SfLoadFaultOTS 0;
BA_ "Remark" SG_ 1016 LBMS_SfLoadFaultOTS "";
BA_ "EventCommandSignal" SG_ 1016 LBMS_UnSfLoadFaultChgOC 0;
BA_ "GatewayedSignals" SG_ 1016 LBMS_UnSfLoadFaultChgOC 0;
BA_ "GenSigInactiveValue" SG_ 1016 LBMS_UnSfLoadFaultChgOC 0;
BA_ "GenSigInvalidValue" SG_ 1016 LBMS_UnSfLoadFaultChgOC 0;
BA_ "GenSigSendType" SG_ 1016 LBMS_UnSfLoadFaultChgOC 1;
BA_ "GenSigStartValue" SG_ 1016 LBMS_UnSfLoadFaultChgOC 0;
BA_ "GenSigTimeoutValue" SG_ 1016 LBMS_UnSfLoadFaultChgOC 0;
BA_ "Remark" SG_ 1016 LBMS_UnSfLoadFaultChgOC "";
BA_ "EventCommandSignal" SG_ 1016 LBMS_UnSfLoadFaultDsgOC 0;
BA_ "GatewayedSignals" SG_ 1016 LBMS_UnSfLoadFaultDsgOC 0;
BA_ "GenSigInactiveValue" SG_ 1016 LBMS_UnSfLoadFaultDsgOC 0;
BA_ "GenSigInvalidValue" SG_ 1016 LBMS_UnSfLoadFaultDsgOC 0;
BA_ "GenSigSendType" SG_ 1016 LBMS_UnSfLoadFaultDsgOC 1;
BA_ "GenSigStartValue" SG_ 1016 LBMS_UnSfLoadFaultDsgOC 0;
BA_ "GenSigTimeoutValue" SG_ 1016 LBMS_UnSfLoadFaultDsgOC 0;
BA_ "Remark" SG_ 1016 LBMS_UnSfLoadFaultDsgOC "";
BA_ "EventCommandSignal" SG_ 1016 LBMS_SfLoadFaultDsgOC 0;
BA_ "GatewayedSignals" SG_ 1016 LBMS_SfLoadFaultDsgOC 0;
BA_ "GenSigInactiveValue" SG_ 1016 LBMS_SfLoadFaultDsgOC 0;
BA_ "GenSigInvalidValue" SG_ 1016 LBMS_SfLoadFaultDsgOC 0;
BA_ "GenSigSendType" SG_ 1016 LBMS_SfLoadFaultDsgOC 1;
BA_ "GenSigStartValue" SG_ 1016 LBMS_SfLoadFaultDsgOC 0;
BA_ "GenSigTimeoutValue" SG_ 1016 LBMS_SfLoadFaultDsgOC 0;
BA_ "Remark" SG_ 1016 LBMS_SfLoadFaultDsgOC "";
BA_ "EventCommandSignal" SG_ 1016 LBMS_UnSfLoadFaultHardTCMOS 0;
BA_ "GatewayedSignals" SG_ 1016 LBMS_UnSfLoadFaultHardTCMOS 0;
BA_ "GenSigInactiveValue" SG_ 1016 LBMS_UnSfLoadFaultHardTCMOS 0;
BA_ "GenSigInvalidValue" SG_ 1016 LBMS_UnSfLoadFaultHardTCMOS 0;
BA_ "GenSigSendType" SG_ 1016 LBMS_UnSfLoadFaultHardTCMOS 1;
BA_ "GenSigStartValue" SG_ 1016 LBMS_UnSfLoadFaultHardTCMOS 0;
BA_ "GenSigTimeoutValue" SG_ 1016 LBMS_UnSfLoadFaultHardTCMOS 0;
BA_ "Remark" SG_ 1016 LBMS_UnSfLoadFaultHardTCMOS "";
BA_ "EventCommandSignal" SG_ 1016 LBMS_UnSfLoadFaultHardShunt 0;
BA_ "GatewayedSignals" SG_ 1016 LBMS_UnSfLoadFaultHardShunt 0;
BA_ "GenSigInactiveValue" SG_ 1016 LBMS_UnSfLoadFaultHardShunt 0;
BA_ "GenSigInvalidValue" SG_ 1016 LBMS_UnSfLoadFaultHardShunt 0;
BA_ "GenSigSendType" SG_ 1016 LBMS_UnSfLoadFaultHardShunt 1;
BA_ "GenSigStartValue" SG_ 1016 LBMS_UnSfLoadFaultHardShunt 0;
BA_ "GenSigTimeoutValue" SG_ 1016 LBMS_UnSfLoadFaultHardShunt 0;
BA_ "Remark" SG_ 1016 LBMS_UnSfLoadFaultHardShunt "";
BA_ "EventCommandSignal" SG_ 1016 LBMS_SfLoadFaultHardShunt 0;
BA_ "GatewayedSignals" SG_ 1016 LBMS_SfLoadFaultHardShunt 0;
BA_ "GenSigInactiveValue" SG_ 1016 LBMS_SfLoadFaultHardShunt 0;
BA_ "GenSigInvalidValue" SG_ 1016 LBMS_SfLoadFaultHardShunt 0;
BA_ "GenSigSendType" SG_ 1016 LBMS_SfLoadFaultHardShunt 1;
BA_ "GenSigStartValue" SG_ 1016 LBMS_SfLoadFaultHardShunt 0;
BA_ "GenSigTimeoutValue" SG_ 1016 LBMS_SfLoadFaultHardShunt 0;
BA_ "Remark" SG_ 1016 LBMS_SfLoadFaultHardShunt "";
BA_ "EventCommandSignal" SG_ 1016 LBMS_UnSfLoadFaultHardChgMOS 0;
BA_ "GatewayedSignals" SG_ 1016 LBMS_UnSfLoadFaultHardChgMOS 0;
BA_ "GenSigInactiveValue" SG_ 1016 LBMS_UnSfLoadFaultHardChgMOS 0;
BA_ "GenSigInvalidValue" SG_ 1016 LBMS_UnSfLoadFaultHardChgMOS 0;
BA_ "GenSigSendType" SG_ 1016 LBMS_UnSfLoadFaultHardChgMOS 1;
BA_ "GenSigStartValue" SG_ 1016 LBMS_UnSfLoadFaultHardChgMOS 0;
BA_ "GenSigTimeoutValue" SG_ 1016 LBMS_UnSfLoadFaultHardChgMOS 0;
BA_ "Remark" SG_ 1016 LBMS_UnSfLoadFaultHardChgMOS "";
BA_ "EventCommandSignal" SG_ 1016 LBMS_UnSfLoadFaultHardDsgMOS 0;
BA_ "GatewayedSignals" SG_ 1016 LBMS_UnSfLoadFaultHardDsgMOS 0;
BA_ "GenSigInactiveValue" SG_ 1016 LBMS_UnSfLoadFaultHardDsgMOS 0;
BA_ "GenSigInvalidValue" SG_ 1016 LBMS_UnSfLoadFaultHardDsgMOS 0;
BA_ "GenSigSendType" SG_ 1016 LBMS_UnSfLoadFaultHardDsgMOS 1;
BA_ "GenSigStartValue" SG_ 1016 LBMS_UnSfLoadFaultHardDsgMOS 0;
BA_ "GenSigTimeoutValue" SG_ 1016 LBMS_UnSfLoadFaultHardDsgMOS 0;
BA_ "Remark" SG_ 1016 LBMS_UnSfLoadFaultHardDsgMOS "";
BA_ "EventCommandSignal" SG_ 1016 LBMS_SOCTolerance 0;
BA_ "GatewayedSignals" SG_ 1016 LBMS_SOCTolerance 0;
BA_ "GenSigInactiveValue" SG_ 1016 LBMS_SOCTolerance 0;
BA_ "GenSigInvalidValue" SG_ 1016 LBMS_SOCTolerance 0;
BA_ "GenSigSendType" SG_ 1016 LBMS_SOCTolerance 1;
BA_ "GenSigStartValue" SG_ 1016 LBMS_SOCTolerance 0;
BA_ "GenSigTimeoutValue" SG_ 1016 LBMS_SOCTolerance 0;
BA_ "Remark" SG_ 1016 LBMS_SOCTolerance "";
BA_ "EventCommandSignal" SG_ 1016 LBMS_ChgMosDrvCmd 0;
BA_ "GatewayedSignals" SG_ 1016 LBMS_ChgMosDrvCmd 0;
BA_ "GenSigInactiveValue" SG_ 1016 LBMS_ChgMosDrvCmd 0;
BA_ "GenSigInvalidValue" SG_ 1016 LBMS_ChgMosDrvCmd 0;
BA_ "GenSigSendType" SG_ 1016 LBMS_ChgMosDrvCmd 1;
BA_ "GenSigStartValue" SG_ 1016 LBMS_ChgMosDrvCmd 0;
BA_ "GenSigTimeoutValue" SG_ 1016 LBMS_ChgMosDrvCmd 0;
BA_ "Remark" SG_ 1016 LBMS_ChgMosDrvCmd "";
BA_ "EventCommandSignal" SG_ 1016 LBMS_DsgMosDrvCmd 0;
BA_ "GatewayedSignals" SG_ 1016 LBMS_DsgMosDrvCmd 0;
BA_ "GenSigInactiveValue" SG_ 1016 LBMS_DsgMosDrvCmd 0;
BA_ "GenSigInvalidValue" SG_ 1016 LBMS_DsgMosDrvCmd 0;
BA_ "GenSigSendType" SG_ 1016 LBMS_DsgMosDrvCmd 1;
BA_ "GenSigStartValue" SG_ 1016 LBMS_DsgMosDrvCmd 0;
BA_ "GenSigTimeoutValue" SG_ 1016 LBMS_DsgMosDrvCmd 0;
BA_ "Remark" SG_ 1016 LBMS_DsgMosDrvCmd "";
BA_ "EventCommandSignal" SG_ 1016 LBMS_Cell1BalCtrlCmd 0;
BA_ "GatewayedSignals" SG_ 1016 LBMS_Cell1BalCtrlCmd 0;
BA_ "GenSigInactiveValue" SG_ 1016 LBMS_Cell1BalCtrlCmd 0;
BA_ "GenSigInvalidValue" SG_ 1016 LBMS_Cell1BalCtrlCmd 0;
BA_ "GenSigSendType" SG_ 1016 LBMS_Cell1BalCtrlCmd 1;
BA_ "GenSigStartValue" SG_ 1016 LBMS_Cell1BalCtrlCmd 0;
BA_ "GenSigTimeoutValue" SG_ 1016 LBMS_Cell1BalCtrlCmd 0;
BA_ "Remark" SG_ 1016 LBMS_Cell1BalCtrlCmd "";
BA_ "EventCommandSignal" SG_ 1016 LBMS_Cell2BalCtrlCmd 0;
BA_ "GatewayedSignals" SG_ 1016 LBMS_Cell2BalCtrlCmd 0;
BA_ "GenSigInactiveValue" SG_ 1016 LBMS_Cell2BalCtrlCmd 0;
BA_ "GenSigInvalidValue" SG_ 1016 LBMS_Cell2BalCtrlCmd 0;
BA_ "GenSigSendType" SG_ 1016 LBMS_Cell2BalCtrlCmd 1;
BA_ "GenSigStartValue" SG_ 1016 LBMS_Cell2BalCtrlCmd 0;
BA_ "GenSigTimeoutValue" SG_ 1016 LBMS_Cell2BalCtrlCmd 0;
BA_ "Remark" SG_ 1016 LBMS_Cell2BalCtrlCmd "";
BA_ "EventCommandSignal" SG_ 1016 LBMS_Cell3BalCtrlCmd 0;
BA_ "GatewayedSignals" SG_ 1016 LBMS_Cell3BalCtrlCmd 0;
BA_ "GenSigInactiveValue" SG_ 1016 LBMS_Cell3BalCtrlCmd 0;
BA_ "GenSigInvalidValue" SG_ 1016 LBMS_Cell3BalCtrlCmd 0;
BA_ "GenSigSendType" SG_ 1016 LBMS_Cell3BalCtrlCmd 1;
BA_ "GenSigStartValue" SG_ 1016 LBMS_Cell3BalCtrlCmd 0;
BA_ "GenSigTimeoutValue" SG_ 1016 LBMS_Cell3BalCtrlCmd 0;
BA_ "Remark" SG_ 1016 LBMS_Cell3BalCtrlCmd "";
BA_ "EventCommandSignal" SG_ 1016 LBMS_Cell4BalCtrlCmd 0;
BA_ "GatewayedSignals" SG_ 1016 LBMS_Cell4BalCtrlCmd 0;
BA_ "GenSigInactiveValue" SG_ 1016 LBMS_Cell4BalCtrlCmd 0;
BA_ "GenSigInvalidValue" SG_ 1016 LBMS_Cell4BalCtrlCmd 0;
BA_ "GenSigSendType" SG_ 1016 LBMS_Cell4BalCtrlCmd 1;
BA_ "GenSigStartValue" SG_ 1016 LBMS_Cell4BalCtrlCmd 0;
BA_ "GenSigTimeoutValue" SG_ 1016 LBMS_Cell4BalCtrlCmd 0;
BA_ "Remark" SG_ 1016 LBMS_Cell4BalCtrlCmd "";
BA_ "EventCommandSignal" SG_ 1016 LBMS_FaultStHardPackVolCol 0;
BA_ "GatewayedSignals" SG_ 1016 LBMS_FaultStHardPackVolCol 0;
BA_ "GenSigInactiveValue" SG_ 1016 LBMS_FaultStHardPackVolCol 0;
BA_ "GenSigInvalidValue" SG_ 1016 LBMS_FaultStHardPackVolCol 0;
BA_ "GenSigSendType" SG_ 1016 LBMS_FaultStHardPackVolCol 1;
BA_ "GenSigStartValue" SG_ 1016 LBMS_FaultStHardPackVolCol 0;
BA_ "GenSigTimeoutValue" SG_ 1016 LBMS_FaultStHardPackVolCol 0;
BA_ "Remark" SG_ 1016 LBMS_FaultStHardPackVolCol "";
BA_ "EventCommandSignal" SG_ 1016 LBMS_FaultStHardUnSfPackVolCol 0;
BA_ "GatewayedSignals" SG_ 1016 LBMS_FaultStHardUnSfPackVolCol 0;
BA_ "GenSigInactiveValue" SG_ 1016 LBMS_FaultStHardUnSfPackVolCol 0;
BA_ "GenSigInvalidValue" SG_ 1016 LBMS_FaultStHardUnSfPackVolCol 0;
BA_ "GenSigSendType" SG_ 1016 LBMS_FaultStHardUnSfPackVolCol 1;
BA_ "GenSigStartValue" SG_ 1016 LBMS_FaultStHardUnSfPackVolCol 0;
BA_ "GenSigTimeoutValue" SG_ 1016 LBMS_FaultStHardUnSfPackVolCol 0;
BA_ "Remark" SG_ 1016 LBMS_FaultStHardUnSfPackVolCol "";
BA_ "EventCommandSignal" SG_ 1016 LBMS_PoleTemp 0;
BA_ "GatewayedSignals" SG_ 1016 LBMS_PoleTemp 0;
BA_ "GenSigInactiveValue" SG_ 1016 LBMS_PoleTemp 0;
BA_ "GenSigInvalidValue" SG_ 1016 LBMS_PoleTemp 0;
BA_ "GenSigSendType" SG_ 1016 LBMS_PoleTemp 1;
BA_ "GenSigStartValue" SG_ 1016 LBMS_PoleTemp 255;
BA_ "GenSigTimeoutValue" SG_ 1016 LBMS_PoleTemp 0;
BA_ "Remark" SG_ 1016 LBMS_PoleTemp "";
BA_ "EventCommandSignal" SG_ 1016 LBMS_PoleTempVD 0;
BA_ "GatewayedSignals" SG_ 1016 LBMS_PoleTempVD 0;
BA_ "GenSigInactiveValue" SG_ 1016 LBMS_PoleTempVD 0;
BA_ "GenSigInvalidValue" SG_ 1016 LBMS_PoleTempVD 0;
BA_ "GenSigSendType" SG_ 1016 LBMS_PoleTempVD 1;
BA_ "GenSigStartValue" SG_ 1016 LBMS_PoleTempVD 0;
BA_ "GenSigTimeoutValue" SG_ 1016 LBMS_PoleTempVD 0;
BA_ "Remark" SG_ 1016 LBMS_PoleTempVD "";
BA_ "EventCommandSignal" SG_ 1016 LBMS_SfLoadPoleTemp 0;
BA_ "GatewayedSignals" SG_ 1016 LBMS_SfLoadPoleTemp 0;
BA_ "GenSigInactiveValue" SG_ 1016 LBMS_SfLoadPoleTemp 0;
BA_ "GenSigInvalidValue" SG_ 1016 LBMS_SfLoadPoleTemp 0;
BA_ "GenSigSendType" SG_ 1016 LBMS_SfLoadPoleTemp 1;
BA_ "GenSigStartValue" SG_ 1016 LBMS_SfLoadPoleTemp 255;
BA_ "GenSigTimeoutValue" SG_ 1016 LBMS_SfLoadPoleTemp 0;
BA_ "Remark" SG_ 1016 LBMS_SfLoadPoleTemp "";
BA_ "EventCommandSignal" SG_ 1016 LBMS_SfLoadPoleTempVD 0;
BA_ "GatewayedSignals" SG_ 1016 LBMS_SfLoadPoleTempVD 0;
BA_ "GenSigInactiveValue" SG_ 1016 LBMS_SfLoadPoleTempVD 0;
BA_ "GenSigInvalidValue" SG_ 1016 LBMS_SfLoadPoleTempVD 0;
BA_ "GenSigSendType" SG_ 1016 LBMS_SfLoadPoleTempVD 1;
BA_ "GenSigStartValue" SG_ 1016 LBMS_SfLoadPoleTempVD 0;
BA_ "GenSigTimeoutValue" SG_ 1016 LBMS_SfLoadPoleTempVD 0;
BA_ "Remark" SG_ 1016 LBMS_SfLoadPoleTempVD "";
BA_ "EventCommandSignal" SG_ 1016 LBMS_FaultStHardCellTotVolCol 0;
BA_ "GatewayedSignals" SG_ 1016 LBMS_FaultStHardCellTotVolCol 0;
BA_ "GenSigInactiveValue" SG_ 1016 LBMS_FaultStHardCellTotVolCol 0;
BA_ "GenSigInvalidValue" SG_ 1016 LBMS_FaultStHardCellTotVolCol 0;
BA_ "GenSigSendType" SG_ 1016 LBMS_FaultStHardCellTotVolCol 1;
BA_ "GenSigStartValue" SG_ 1016 LBMS_FaultStHardCellTotVolCol 0;
BA_ "GenSigTimeoutValue" SG_ 1016 LBMS_FaultStHardCellTotVolCol 0;
BA_ "Remark" SG_ 1016 LBMS_FaultStHardCellTotVolCol "";
BA_ "EventCommandSignal" SG_ 1016 LBMS_FaultStHardComSoVoltCol 0;
BA_ "GatewayedSignals" SG_ 1016 LBMS_FaultStHardComSoVoltCol 0;
BA_ "GenSigInactiveValue" SG_ 1016 LBMS_FaultStHardComSoVoltCol 0;
BA_ "GenSigInvalidValue" SG_ 1016 LBMS_FaultStHardComSoVoltCol 0;
BA_ "GenSigSendType" SG_ 1016 LBMS_FaultStHardComSoVoltCol 1;
BA_ "GenSigStartValue" SG_ 1016 LBMS_FaultStHardComSoVoltCol 0;
BA_ "GenSigTimeoutValue" SG_ 1016 LBMS_FaultStHardComSoVoltCol 0;
BA_ "Remark" SG_ 1016 LBMS_FaultStHardComSoVoltCol "";
BA_ "EventCommandSignal" SG_ 1016 LBMS_AvailableCapacity 0;
BA_ "GatewayedSignals" SG_ 1016 LBMS_AvailableCapacity 0;
BA_ "GenSigInactiveValue" SG_ 1016 LBMS_AvailableCapacity 0;
BA_ "GenSigInvalidValue" SG_ 1016 LBMS_AvailableCapacity 0;
BA_ "GenSigSendType" SG_ 1016 LBMS_AvailableCapacity 1;
BA_ "GenSigStartValue" SG_ 1016 LBMS_AvailableCapacity 40;
BA_ "GenSigTimeoutValue" SG_ 1016 LBMS_AvailableCapacity 0;
BA_ "Remark" SG_ 1016 LBMS_AvailableCapacity "";
BA_ "EventCommandSignal" SG_ 1016 LBMS_DCDCMosOpenReason 0;
BA_ "GatewayedSignals" SG_ 1016 LBMS_DCDCMosOpenReason 0;
BA_ "GenSigInactiveValue" SG_ 1016 LBMS_DCDCMosOpenReason 0;
BA_ "GenSigInvalidValue" SG_ 1016 LBMS_DCDCMosOpenReason 0;
BA_ "GenSigSendType" SG_ 1016 LBMS_DCDCMosOpenReason 1;
BA_ "GenSigStartValue" SG_ 1016 LBMS_DCDCMosOpenReason 0;
BA_ "GenSigTimeoutValue" SG_ 1016 LBMS_DCDCMosOpenReason 0;
BA_ "Remark" SG_ 1016 LBMS_DCDCMosOpenReason "";
BA_ "EventCommandSignal" SG_ 1016 LBMS_AutoChgReason 0;
BA_ "GatewayedSignals" SG_ 1016 LBMS_AutoChgReason 0;
BA_ "GenSigInactiveValue" SG_ 1016 LBMS_AutoChgReason 0;
BA_ "GenSigInvalidValue" SG_ 1016 LBMS_AutoChgReason 0;
BA_ "GenSigSendType" SG_ 1016 LBMS_AutoChgReason 1;
BA_ "GenSigStartValue" SG_ 1016 LBMS_AutoChgReason 0;
BA_ "GenSigTimeoutValue" SG_ 1016 LBMS_AutoChgReason 0;
BA_ "Remark" SG_ 1016 LBMS_AutoChgReason "";
BA_ "EventCommandSignal" SG_ 1016 LBMS_LockSOCThreshold_Trans 0;
BA_ "GatewayedSignals" SG_ 1016 LBMS_LockSOCThreshold_Trans 0;
BA_ "GenSigInactiveValue" SG_ 1016 LBMS_LockSOCThreshold_Trans 0;
BA_ "GenSigInvalidValue" SG_ 1016 LBMS_LockSOCThreshold_Trans 0;
BA_ "GenSigSendType" SG_ 1016 LBMS_LockSOCThreshold_Trans 1;
BA_ "GenSigStartValue" SG_ 1016 LBMS_LockSOCThreshold_Trans 255;
BA_ "GenSigTimeoutValue" SG_ 1016 LBMS_LockSOCThreshold_Trans 0;
BA_ "Remark" SG_ 1016 LBMS_LockSOCThreshold_Trans "";
BA_ "EventCommandSignal" SG_ 1016 LBMS_LockSOCThreshold_Level1 0;
BA_ "GatewayedSignals" SG_ 1016 LBMS_LockSOCThreshold_Level1 0;
BA_ "GenSigInactiveValue" SG_ 1016 LBMS_LockSOCThreshold_Level1 0;
BA_ "GenSigInvalidValue" SG_ 1016 LBMS_LockSOCThreshold_Level1 0;
BA_ "GenSigSendType" SG_ 1016 LBMS_LockSOCThreshold_Level1 1;
BA_ "GenSigStartValue" SG_ 1016 LBMS_LockSOCThreshold_Level1 255;
BA_ "GenSigTimeoutValue" SG_ 1016 LBMS_LockSOCThreshold_Level1 0;
BA_ "Remark" SG_ 1016 LBMS_LockSOCThreshold_Level1 "";
BA_ "EventCommandSignal" SG_ 1016 LBMS_LockSOCThreshold_Level2 0;
BA_ "GatewayedSignals" SG_ 1016 LBMS_LockSOCThreshold_Level2 0;
BA_ "GenSigInactiveValue" SG_ 1016 LBMS_LockSOCThreshold_Level2 0;
BA_ "GenSigInvalidValue" SG_ 1016 LBMS_LockSOCThreshold_Level2 0;
BA_ "GenSigSendType" SG_ 1016 LBMS_LockSOCThreshold_Level2 1;
BA_ "GenSigStartValue" SG_ 1016 LBMS_LockSOCThreshold_Level2 255;
BA_ "GenSigTimeoutValue" SG_ 1016 LBMS_LockSOCThreshold_Level2 0;
BA_ "Remark" SG_ 1016 LBMS_LockSOCThreshold_Level2 "";
BA_ "EventCommandSignal" SG_ 1016 LBMS_AutoChgThres_TransLo 0;
BA_ "GatewayedSignals" SG_ 1016 LBMS_AutoChgThres_TransLo 0;
BA_ "GenSigInactiveValue" SG_ 1016 LBMS_AutoChgThres_TransLo 0;
BA_ "GenSigInvalidValue" SG_ 1016 LBMS_AutoChgThres_TransLo 0;
BA_ "GenSigSendType" SG_ 1016 LBMS_AutoChgThres_TransLo 1;
BA_ "GenSigStartValue" SG_ 1016 LBMS_AutoChgThres_TransLo 255;
BA_ "GenSigTimeoutValue" SG_ 1016 LBMS_AutoChgThres_TransLo 0;
BA_ "Remark" SG_ 1016 LBMS_AutoChgThres_TransLo "";
BA_ "EventCommandSignal" SG_ 1016 LBMS_AutoChgThres_TransUp 0;
BA_ "GatewayedSignals" SG_ 1016 LBMS_AutoChgThres_TransUp 0;
BA_ "GenSigInactiveValue" SG_ 1016 LBMS_AutoChgThres_TransUp 0;
BA_ "GenSigInvalidValue" SG_ 1016 LBMS_AutoChgThres_TransUp 0;
BA_ "GenSigSendType" SG_ 1016 LBMS_AutoChgThres_TransUp 1;
BA_ "GenSigStartValue" SG_ 1016 LBMS_AutoChgThres_TransUp 255;
BA_ "GenSigTimeoutValue" SG_ 1016 LBMS_AutoChgThres_TransUp 0;
BA_ "Remark" SG_ 1016 LBMS_AutoChgThres_TransUp "";
BA_ "EventCommandSignal" SG_ 1016 LBMS_AutoChgThres_NtransLo 0;
BA_ "GatewayedSignals" SG_ 1016 LBMS_AutoChgThres_NtransLo 0;
BA_ "GenSigInactiveValue" SG_ 1016 LBMS_AutoChgThres_NtransLo 0;
BA_ "GenSigInvalidValue" SG_ 1016 LBMS_AutoChgThres_NtransLo 0;
BA_ "GenSigSendType" SG_ 1016 LBMS_AutoChgThres_NtransLo 1;
BA_ "GenSigStartValue" SG_ 1016 LBMS_AutoChgThres_NtransLo 255;
BA_ "GenSigTimeoutValue" SG_ 1016 LBMS_AutoChgThres_NtransLo 0;
BA_ "Remark" SG_ 1016 LBMS_AutoChgThres_NtransLo "";
BA_ "EventCommandSignal" SG_ 1016 LBMS_AutoChgThres_NtransUp 0;
BA_ "GatewayedSignals" SG_ 1016 LBMS_AutoChgThres_NtransUp 0;
BA_ "GenSigInactiveValue" SG_ 1016 LBMS_AutoChgThres_NtransUp 0;
BA_ "GenSigInvalidValue" SG_ 1016 LBMS_AutoChgThres_NtransUp 0;
BA_ "GenSigSendType" SG_ 1016 LBMS_AutoChgThres_NtransUp 1;
BA_ "GenSigStartValue" SG_ 1016 LBMS_AutoChgThres_NtransUp 255;
BA_ "GenSigTimeoutValue" SG_ 1016 LBMS_AutoChgThres_NtransUp 0;
BA_ "Remark" SG_ 1016 LBMS_AutoChgThres_NtransUp "";
BA_ "EventCommandSignal" SG_ 1016 LBMS_Last2LocWakeUpTime 0;
BA_ "GatewayedSignals" SG_ 1016 LBMS_Last2LocWakeUpTime 0;
BA_ "GenSigInactiveValue" SG_ 1016 LBMS_Last2LocWakeUpTime 0;
BA_ "GenSigInvalidValue" SG_ 1016 LBMS_Last2LocWakeUpTime 0;
BA_ "GenSigSendType" SG_ 1016 LBMS_Last2LocWakeUpTime 1;
BA_ "GenSigStartValue" SG_ 1016 LBMS_Last2LocWakeUpTime 0;
BA_ "GenSigTimeoutValue" SG_ 1016 LBMS_Last2LocWakeUpTime 0;
BA_ "Remark" SG_ 1016 LBMS_Last2LocWakeUpTime "";
BA_ "EventCommandSignal" SG_ 1016 LBMS_SleepTime_NM 0;
BA_ "GatewayedSignals" SG_ 1016 LBMS_SleepTime_NM 0;
BA_ "GenSigInactiveValue" SG_ 1016 LBMS_SleepTime_NM 0;
BA_ "GenSigInvalidValue" SG_ 1016 LBMS_SleepTime_NM 0;
BA_ "GenSigSendType" SG_ 1016 LBMS_SleepTime_NM 1;
BA_ "GenSigStartValue" SG_ 1016 LBMS_SleepTime_NM 0;
BA_ "GenSigTimeoutValue" SG_ 1016 LBMS_SleepTime_NM 0;
BA_ "Remark" SG_ 1016 LBMS_SleepTime_NM "";
BA_ "EventCommandSignal" SG_ 1016 LBMS_ServiceTime 0;
BA_ "GatewayedSignals" SG_ 1016 LBMS_ServiceTime 0;
BA_ "GenSigInactiveValue" SG_ 1016 LBMS_ServiceTime 0;
BA_ "GenSigInvalidValue" SG_ 1016 LBMS_ServiceTime 0;
BA_ "GenSigSendType" SG_ 1016 LBMS_ServiceTime 1;
BA_ "GenSigStartValue" SG_ 1016 LBMS_ServiceTime 0;
BA_ "GenSigTimeoutValue" SG_ 1016 LBMS_ServiceTime 0;
BA_ "Remark" SG_ 1016 LBMS_ServiceTime "";
BA_ "EventCommandSignal" SG_ 1016 LBMS_DsgMosOpenReason 0;
BA_ "GatewayedSignals" SG_ 1016 LBMS_DsgMosOpenReason 0;
BA_ "GenSigInactiveValue" SG_ 1016 LBMS_DsgMosOpenReason 0;
BA_ "GenSigInvalidValue" SG_ 1016 LBMS_DsgMosOpenReason 0;
BA_ "GenSigSendType" SG_ 1016 LBMS_DsgMosOpenReason 1;
BA_ "GenSigStartValue" SG_ 1016 LBMS_DsgMosOpenReason 0;
BA_ "GenSigTimeoutValue" SG_ 1016 LBMS_DsgMosOpenReason 0;
BA_ "Remark" SG_ 1016 LBMS_DsgMosOpenReason "";
BA_ "EventCommandSignal" SG_ 1016 LBMS_ChgMosOpenReason 0;
BA_ "GatewayedSignals" SG_ 1016 LBMS_ChgMosOpenReason 0;
BA_ "GenSigInactiveValue" SG_ 1016 LBMS_ChgMosOpenReason 0;
BA_ "GenSigInvalidValue" SG_ 1016 LBMS_ChgMosOpenReason 0;
BA_ "GenSigSendType" SG_ 1016 LBMS_ChgMosOpenReason 1;
BA_ "GenSigStartValue" SG_ 1016 LBMS_ChgMosOpenReason 0;
BA_ "GenSigTimeoutValue" SG_ 1016 LBMS_ChgMosOpenReason 0;
BA_ "Remark" SG_ 1016 LBMS_ChgMosOpenReason "";
BA_ "EventCommandSignal" SG_ 1016 LBMS_LocalNotSleep_Reason 0;
BA_ "GatewayedSignals" SG_ 1016 LBMS_LocalNotSleep_Reason 0;
BA_ "GenSigInactiveValue" SG_ 1016 LBMS_LocalNotSleep_Reason 0;
BA_ "GenSigInvalidValue" SG_ 1016 LBMS_LocalNotSleep_Reason 15;
BA_ "GenSigSendType" SG_ 1016 LBMS_LocalNotSleep_Reason 1;
BA_ "GenSigStartValue" SG_ 1016 LBMS_LocalNotSleep_Reason 0;
BA_ "GenSigTimeoutValue" SG_ 1016 LBMS_LocalNotSleep_Reason 0;
BA_ "Remark" SG_ 1016 LBMS_LocalNotSleep_Reason "";
BA_ "EventCommandSignal" SG_ 1016 LBMS_SfUpackRvsVolt 0;
BA_ "GatewayedSignals" SG_ 1016 LBMS_SfUpackRvsVolt 0;
BA_ "GenSigInactiveValue" SG_ 1016 LBMS_SfUpackRvsVolt 0;
BA_ "GenSigInvalidValue" SG_ 1016 LBMS_SfUpackRvsVolt 0;
BA_ "GenSigSendType" SG_ 1016 LBMS_SfUpackRvsVolt 1;
BA_ "GenSigStartValue" SG_ 1016 LBMS_SfUpackRvsVolt 4095;
BA_ "GenSigTimeoutValue" SG_ 1016 LBMS_SfUpackRvsVolt 0;
BA_ "Remark" SG_ 1016 LBMS_SfUpackRvsVolt "";
BA_ "EventCommandSignal" SG_ 1016 LBMS_SfUpackRvsVoltVD 0;
BA_ "GatewayedSignals" SG_ 1016 LBMS_SfUpackRvsVoltVD 0;
BA_ "GenSigInactiveValue" SG_ 1016 LBMS_SfUpackRvsVoltVD 0;
BA_ "GenSigInvalidValue" SG_ 1016 LBMS_SfUpackRvsVoltVD 0;
BA_ "GenSigSendType" SG_ 1016 LBMS_SfUpackRvsVoltVD 1;
BA_ "GenSigStartValue" SG_ 1016 LBMS_SfUpackRvsVoltVD 0;
BA_ "GenSigTimeoutValue" SG_ 1016 LBMS_SfUpackRvsVoltVD 0;
BA_ "Remark" SG_ 1016 LBMS_SfUpackRvsVoltVD "";
BA_ "EventCommandSignal" SG_ 1016 LBMS_SfFaultStHardComSoVoltCol 0;
BA_ "GatewayedSignals" SG_ 1016 LBMS_SfFaultStHardComSoVoltCol 0;
BA_ "GenSigInactiveValue" SG_ 1016 LBMS_SfFaultStHardComSoVoltCol 0;
BA_ "GenSigInvalidValue" SG_ 1016 LBMS_SfFaultStHardComSoVoltCol 0;
BA_ "GenSigSendType" SG_ 1016 LBMS_SfFaultStHardComSoVoltCol 1;
BA_ "GenSigStartValue" SG_ 1016 LBMS_SfFaultStHardComSoVoltCol 0;
BA_ "GenSigTimeoutValue" SG_ 1016 LBMS_SfFaultStHardComSoVoltCol 0;
BA_ "Remark" SG_ 1016 LBMS_SfFaultStHardComSoVoltCol "";
BA_ "EventCommandSignal" SG_ 1016 LBMS_SfChgMosDrvCmd 0;
BA_ "GatewayedSignals" SG_ 1016 LBMS_SfChgMosDrvCmd 0;
BA_ "GenSigInactiveValue" SG_ 1016 LBMS_SfChgMosDrvCmd 0;
BA_ "GenSigInvalidValue" SG_ 1016 LBMS_SfChgMosDrvCmd 0;
BA_ "GenSigSendType" SG_ 1016 LBMS_SfChgMosDrvCmd 1;
BA_ "GenSigStartValue" SG_ 1016 LBMS_SfChgMosDrvCmd 0;
BA_ "GenSigTimeoutValue" SG_ 1016 LBMS_SfChgMosDrvCmd 0;
BA_ "Remark" SG_ 1016 LBMS_SfChgMosDrvCmd "";
BA_ "EventCommandSignal" SG_ 1016 LBMS_SfDsgMosDrvCmd 0;
BA_ "GatewayedSignals" SG_ 1016 LBMS_SfDsgMosDrvCmd 0;
BA_ "GenSigInactiveValue" SG_ 1016 LBMS_SfDsgMosDrvCmd 0;
BA_ "GenSigInvalidValue" SG_ 1016 LBMS_SfDsgMosDrvCmd 0;
BA_ "GenSigSendType" SG_ 1016 LBMS_SfDsgMosDrvCmd 1;
BA_ "GenSigStartValue" SG_ 1016 LBMS_SfDsgMosDrvCmd 0;
BA_ "GenSigTimeoutValue" SG_ 1016 LBMS_SfDsgMosDrvCmd 0;
BA_ "Remark" SG_ 1016 LBMS_SfDsgMosDrvCmd "";
BA_ "EventCommandSignal" SG_ 1016 LBMS_SfLoadUpackRvsVolt 0;
BA_ "GatewayedSignals" SG_ 1016 LBMS_SfLoadUpackRvsVolt 0;
BA_ "GenSigInactiveValue" SG_ 1016 LBMS_SfLoadUpackRvsVolt 0;
BA_ "GenSigInvalidValue" SG_ 1016 LBMS_SfLoadUpackRvsVolt 0;
BA_ "GenSigSendType" SG_ 1016 LBMS_SfLoadUpackRvsVolt 1;
BA_ "GenSigStartValue" SG_ 1016 LBMS_SfLoadUpackRvsVolt 4095;
BA_ "GenSigTimeoutValue" SG_ 1016 LBMS_SfLoadUpackRvsVolt 0;
BA_ "Remark" SG_ 1016 LBMS_SfLoadUpackRvsVolt "";
BA_ "EventCommandSignal" SG_ 1016 LBMS_SfLoadUpackRvsVoltVD 0;
BA_ "GatewayedSignals" SG_ 1016 LBMS_SfLoadUpackRvsVoltVD 0;
BA_ "GenSigInactiveValue" SG_ 1016 LBMS_SfLoadUpackRvsVoltVD 0;
BA_ "GenSigInvalidValue" SG_ 1016 LBMS_SfLoadUpackRvsVoltVD 0;
BA_ "GenSigSendType" SG_ 1016 LBMS_SfLoadUpackRvsVoltVD 1;
BA_ "GenSigStartValue" SG_ 1016 LBMS_SfLoadUpackRvsVoltVD 0;
BA_ "GenSigTimeoutValue" SG_ 1016 LBMS_SfLoadUpackRvsVoltVD 0;
BA_ "Remark" SG_ 1016 LBMS_SfLoadUpackRvsVoltVD "";
BA_ "EventCommandSignal" SG_ 1016 LBMS_UnSfLoadChgMosDrvCmd 0;
BA_ "GatewayedSignals" SG_ 1016 LBMS_UnSfLoadChgMosDrvCmd 0;
BA_ "GenSigInactiveValue" SG_ 1016 LBMS_UnSfLoadChgMosDrvCmd 0;
BA_ "GenSigInvalidValue" SG_ 1016 LBMS_UnSfLoadChgMosDrvCmd 0;
BA_ "GenSigSendType" SG_ 1016 LBMS_UnSfLoadChgMosDrvCmd 1;
BA_ "GenSigStartValue" SG_ 1016 LBMS_UnSfLoadChgMosDrvCmd 0;
BA_ "GenSigTimeoutValue" SG_ 1016 LBMS_UnSfLoadChgMosDrvCmd 0;
BA_ "Remark" SG_ 1016 LBMS_UnSfLoadChgMosDrvCmd "";
BA_ "EventCommandSignal" SG_ 1016 LBMS_UnSfLoadDsgMosDrvCmd 0;
BA_ "GatewayedSignals" SG_ 1016 LBMS_UnSfLoadDsgMosDrvCmd 0;
BA_ "GenSigInactiveValue" SG_ 1016 LBMS_UnSfLoadDsgMosDrvCmd 0;
BA_ "GenSigInvalidValue" SG_ 1016 LBMS_UnSfLoadDsgMosDrvCmd 0;
BA_ "GenSigSendType" SG_ 1016 LBMS_UnSfLoadDsgMosDrvCmd 1;
BA_ "GenSigStartValue" SG_ 1016 LBMS_UnSfLoadDsgMosDrvCmd 0;
BA_ "GenSigTimeoutValue" SG_ 1016 LBMS_UnSfLoadDsgMosDrvCmd 0;
BA_ "Remark" SG_ 1016 LBMS_UnSfLoadDsgMosDrvCmd "";
BA_ "EventCommandSignal" SG_ 1016 LBMS_UnsfLoadDsgMosOpenReason 0;
BA_ "GatewayedSignals" SG_ 1016 LBMS_UnsfLoadDsgMosOpenReason 0;
BA_ "GenSigInactiveValue" SG_ 1016 LBMS_UnsfLoadDsgMosOpenReason 0;
BA_ "GenSigInvalidValue" SG_ 1016 LBMS_UnsfLoadDsgMosOpenReason 0;
BA_ "GenSigSendType" SG_ 1016 LBMS_UnsfLoadDsgMosOpenReason 1;
BA_ "GenSigStartValue" SG_ 1016 LBMS_UnsfLoadDsgMosOpenReason 0;
BA_ "GenSigTimeoutValue" SG_ 1016 LBMS_UnsfLoadDsgMosOpenReason 0;
BA_ "Remark" SG_ 1016 LBMS_UnsfLoadDsgMosOpenReason "";
BA_ "EventCommandSignal" SG_ 1016 LBMS_UnsfLoadChgMosOpenReason 0;
BA_ "GatewayedSignals" SG_ 1016 LBMS_UnsfLoadChgMosOpenReason 0;
BA_ "GenSigInactiveValue" SG_ 1016 LBMS_UnsfLoadChgMosOpenReason 0;
BA_ "GenSigInvalidValue" SG_ 1016 LBMS_UnsfLoadChgMosOpenReason 0;
BA_ "GenSigSendType" SG_ 1016 LBMS_UnsfLoadChgMosOpenReason 1;
BA_ "GenSigStartValue" SG_ 1016 LBMS_UnsfLoadChgMosOpenReason 0;
BA_ "GenSigTimeoutValue" SG_ 1016 LBMS_UnsfLoadChgMosOpenReason 0;
BA_ "Remark" SG_ 1016 LBMS_UnsfLoadChgMosOpenReason "";
BA_ "EventCommandSignal" SG_ 1016 LBMS_FaultStHarddUnSfComSoVoltCol 0;
BA_ "GatewayedSignals" SG_ 1016 LBMS_FaultStHarddUnSfComSoVoltCol 0;
BA_ "GenSigInactiveValue" SG_ 1016 LBMS_FaultStHarddUnSfComSoVoltCol 0;
BA_ "GenSigInvalidValue" SG_ 1016 LBMS_FaultStHarddUnSfComSoVoltCol 0;
BA_ "GenSigSendType" SG_ 1016 LBMS_FaultStHarddUnSfComSoVoltCol 1;
BA_ "GenSigStartValue" SG_ 1016 LBMS_FaultStHarddUnSfComSoVoltCol 0;
BA_ "GenSigTimeoutValue" SG_ 1016 LBMS_FaultStHarddUnSfComSoVoltCol 0;
BA_ "Remark" SG_ 1016 LBMS_FaultStHarddUnSfComSoVoltCol "";
BA_ "EventCommandSignal" SG_ 794 LBMSAD_1_CRC 0;
BA_ "GatewayedSignals" SG_ 794 LBMSAD_1_CRC 0;
BA_ "GenSigInactiveValue" SG_ 794 LBMSAD_1_CRC 0;
BA_ "GenSigInvalidValue" SG_ 794 LBMSAD_1_CRC 0;
BA_ "GenSigSendType" SG_ 794 LBMSAD_1_CRC 1;
BA_ "GenSigStartValue" SG_ 794 LBMSAD_1_CRC 0;
BA_ "GenSigTimeoutValue" SG_ 794 LBMSAD_1_CRC 0;
BA_ "Remark" SG_ 794 LBMSAD_1_CRC "";
BA_ "EventCommandSignal" SG_ 794 LBMSAD_1_Counter 0;
BA_ "GatewayedSignals" SG_ 794 LBMSAD_1_Counter 0;
BA_ "GenSigInactiveValue" SG_ 794 LBMSAD_1_Counter 0;
BA_ "GenSigInvalidValue" SG_ 794 LBMSAD_1_Counter 0;
BA_ "GenSigSendType" SG_ 794 LBMSAD_1_Counter 1;
BA_ "GenSigStartValue" SG_ 794 LBMSAD_1_Counter 0;
BA_ "GenSigTimeoutValue" SG_ 794 LBMSAD_1_Counter 0;
BA_ "Remark" SG_ 794 LBMSAD_1_Counter "";
BA_ "EventCommandSignal" SG_ 794 LBMSAD_SOFVD 0;
BA_ "GatewayedSignals" SG_ 794 LBMSAD_SOFVD 0;
BA_ "GenSigInactiveValue" SG_ 794 LBMSAD_SOFVD 0;
BA_ "GenSigInvalidValue" SG_ 794 LBMSAD_SOFVD 0;
BA_ "GenSigSendType" SG_ 794 LBMSAD_SOFVD 1;
BA_ "GenSigStartValue" SG_ 794 LBMSAD_SOFVD 0;
BA_ "GenSigTimeoutValue" SG_ 794 LBMSAD_SOFVD 0;
BA_ "Remark" SG_ 794 LBMSAD_SOFVD "";
BA_ "EventCommandSignal" SG_ 794 LBMSAD_SOFEN 0;
BA_ "GatewayedSignals" SG_ 794 LBMSAD_SOFEN 0;
BA_ "GenSigInactiveValue" SG_ 794 LBMSAD_SOFEN 0;
BA_ "GenSigInvalidValue" SG_ 794 LBMSAD_SOFEN 0;
BA_ "GenSigSendType" SG_ 794 LBMSAD_SOFEN 1;
BA_ "GenSigStartValue" SG_ 794 LBMSAD_SOFEN 0;
BA_ "GenSigTimeoutValue" SG_ 794 LBMSAD_SOFEN 0;
BA_ "Remark" SG_ 794 LBMSAD_SOFEN "";
BA_ "EventCommandSignal" SG_ 794 LBMSAD_ChargReq 0;
BA_ "GatewayedSignals" SG_ 794 LBMSAD_ChargReq 0;
BA_ "GenSigInactiveValue" SG_ 794 LBMSAD_ChargReq 0;
BA_ "GenSigInvalidValue" SG_ 794 LBMSAD_ChargReq 0;
BA_ "GenSigSendType" SG_ 794 LBMSAD_ChargReq 1;
BA_ "GenSigStartValue" SG_ 794 LBMSAD_ChargReq 0;
BA_ "GenSigTimeoutValue" SG_ 794 LBMSAD_ChargReq 0;
BA_ "Remark" SG_ 794 LBMSAD_ChargReq "";
BA_ "EventCommandSignal" SG_ 794 LBMSAD_SOCVD 0;
BA_ "GatewayedSignals" SG_ 794 LBMSAD_SOCVD 0;
BA_ "GenSigInactiveValue" SG_ 794 LBMSAD_SOCVD 0;
BA_ "GenSigInvalidValue" SG_ 794 LBMSAD_SOCVD 0;
BA_ "GenSigSendType" SG_ 794 LBMSAD_SOCVD 1;
BA_ "GenSigStartValue" SG_ 794 LBMSAD_SOCVD 0;
BA_ "GenSigTimeoutValue" SG_ 794 LBMSAD_SOCVD 0;
BA_ "Remark" SG_ 794 LBMSAD_SOCVD "";
BA_ "EventCommandSignal" SG_ 794 LBMSAD_SOC 0;
BA_ "GatewayedSignals" SG_ 794 LBMSAD_SOC 0;
BA_ "GenSigInactiveValue" SG_ 794 LBMSAD_SOC 0;
BA_ "GenSigInvalidValue" SG_ 794 LBMSAD_SOC 0;
BA_ "GenSigSendType" SG_ 794 LBMSAD_SOC 1;
BA_ "GenSigStartValue" SG_ 794 LBMSAD_SOC 255;
BA_ "GenSigTimeoutValue" SG_ 794 LBMSAD_SOC 0;
BA_ "Remark" SG_ 794 LBMSAD_SOC "";
BA_ "EventCommandSignal" SG_ 794 LBMSAD_AlrmDispSt 0;
BA_ "GatewayedSignals" SG_ 794 LBMSAD_AlrmDispSt 0;
BA_ "GenSigInactiveValue" SG_ 794 LBMSAD_AlrmDispSt 0;
BA_ "GenSigInvalidValue" SG_ 794 LBMSAD_AlrmDispSt 0;
BA_ "GenSigSendType" SG_ 794 LBMSAD_AlrmDispSt 1;
BA_ "GenSigStartValue" SG_ 794 LBMSAD_AlrmDispSt 0;
BA_ "GenSigTimeoutValue" SG_ 794 LBMSAD_AlrmDispSt 0;
BA_ "Remark" SG_ 794 LBMSAD_AlrmDispSt "";
BA_ "EventCommandSignal" SG_ 794 LBMSAD_CurrentRange 0;
BA_ "GatewayedSignals" SG_ 794 LBMSAD_CurrentRange 0;
BA_ "GenSigInactiveValue" SG_ 794 LBMSAD_CurrentRange 0;
BA_ "GenSigInvalidValue" SG_ 794 LBMSAD_CurrentRange 0;
BA_ "GenSigSendType" SG_ 794 LBMSAD_CurrentRange 1;
BA_ "GenSigStartValue" SG_ 794 LBMSAD_CurrentRange 0;
BA_ "GenSigTimeoutValue" SG_ 794 LBMSAD_CurrentRange 0;
BA_ "Remark" SG_ 794 LBMSAD_CurrentRange "";
BA_ "EventCommandSignal" SG_ 794 LBMSAD_RefChargReq 0;
BA_ "GatewayedSignals" SG_ 794 LBMSAD_RefChargReq 0;
BA_ "GenSigInactiveValue" SG_ 794 LBMSAD_RefChargReq 0;
BA_ "GenSigInvalidValue" SG_ 794 LBMSAD_RefChargReq 0;
BA_ "GenSigSendType" SG_ 794 LBMSAD_RefChargReq 1;
BA_ "GenSigStartValue" SG_ 794 LBMSAD_RefChargReq 0;
BA_ "GenSigTimeoutValue" SG_ 794 LBMSAD_RefChargReq 0;
BA_ "Remark" SG_ 794 LBMSAD_RefChargReq "";
BA_ "EventCommandSignal" SG_ 794 LBMSAD_ThermalRunawayErr 0;
BA_ "GatewayedSignals" SG_ 794 LBMSAD_ThermalRunawayErr 0;
BA_ "GenSigInactiveValue" SG_ 794 LBMSAD_ThermalRunawayErr 0;
BA_ "GenSigInvalidValue" SG_ 794 LBMSAD_ThermalRunawayErr 0;
BA_ "GenSigSendType" SG_ 794 LBMSAD_ThermalRunawayErr 1;
BA_ "GenSigStartValue" SG_ 794 LBMSAD_ThermalRunawayErr 0;
BA_ "GenSigTimeoutValue" SG_ 794 LBMSAD_ThermalRunawayErr 0;
BA_ "Remark" SG_ 794 LBMSAD_ThermalRunawayErr "";
BA_ "EventCommandSignal" SG_ 794 LBMSAD_ChrgVoltReq 0;
BA_ "GatewayedSignals" SG_ 794 LBMSAD_ChrgVoltReq 0;
BA_ "GenSigInactiveValue" SG_ 794 LBMSAD_ChrgVoltReq 0;
BA_ "GenSigInvalidValue" SG_ 794 LBMSAD_ChrgVoltReq 0;
BA_ "GenSigSendType" SG_ 794 LBMSAD_ChrgVoltReq 1;
BA_ "GenSigStartValue" SG_ 794 LBMSAD_ChrgVoltReq 1023;
BA_ "GenSigTimeoutValue" SG_ 794 LBMSAD_ChrgVoltReq 0;
BA_ "Remark" SG_ 794 LBMSAD_ChrgVoltReq "";
BA_ "EventCommandSignal" SG_ 794 LBMSAD_IPDS_BAT1PowerReq 0;
BA_ "GatewayedSignals" SG_ 794 LBMSAD_IPDS_BAT1PowerReq 0;
BA_ "GenSigInactiveValue" SG_ 794 LBMSAD_IPDS_BAT1PowerReq 0;
BA_ "GenSigInvalidValue" SG_ 794 LBMSAD_IPDS_BAT1PowerReq 0;
BA_ "GenSigSendType" SG_ 794 LBMSAD_IPDS_BAT1PowerReq 1;
BA_ "GenSigStartValue" SG_ 794 LBMSAD_IPDS_BAT1PowerReq 1;
BA_ "GenSigTimeoutValue" SG_ 794 LBMSAD_IPDS_BAT1PowerReq 0;
BA_ "Remark" SG_ 794 LBMSAD_IPDS_BAT1PowerReq "";
BA_ "EventCommandSignal" SG_ 794 LBMSAD_IPDS_BAT2PowerReq 0;
BA_ "GatewayedSignals" SG_ 794 LBMSAD_IPDS_BAT2PowerReq 0;
BA_ "GenSigInactiveValue" SG_ 794 LBMSAD_IPDS_BAT2PowerReq 0;
BA_ "GenSigInvalidValue" SG_ 794 LBMSAD_IPDS_BAT2PowerReq 0;
BA_ "GenSigSendType" SG_ 794 LBMSAD_IPDS_BAT2PowerReq 1;
BA_ "GenSigStartValue" SG_ 794 LBMSAD_IPDS_BAT2PowerReq 1;
BA_ "GenSigTimeoutValue" SG_ 794 LBMSAD_IPDS_BAT2PowerReq 0;
BA_ "Remark" SG_ 794 LBMSAD_IPDS_BAT2PowerReq "";
BA_ "EventCommandSignal" SG_ 794 LBMSAD_IPDS_GridlsoPowerReq 0;
BA_ "GatewayedSignals" SG_ 794 LBMSAD_IPDS_GridlsoPowerReq 0;
BA_ "GenSigInactiveValue" SG_ 794 LBMSAD_IPDS_GridlsoPowerReq 0;
BA_ "GenSigInvalidValue" SG_ 794 LBMSAD_IPDS_GridlsoPowerReq 0;
BA_ "GenSigSendType" SG_ 794 LBMSAD_IPDS_GridlsoPowerReq 1;
BA_ "GenSigStartValue" SG_ 794 LBMSAD_IPDS_GridlsoPowerReq 1;
BA_ "GenSigTimeoutValue" SG_ 794 LBMSAD_IPDS_GridlsoPowerReq 0;
BA_ "Remark" SG_ 794 LBMSAD_IPDS_GridlsoPowerReq "功能需求纯电混动信号默认值不一致";
BA_ "EventCommandSignal" SG_ 974 LBMSAD_SOH 0;
BA_ "GatewayedSignals" SG_ 974 LBMSAD_SOH 0;
BA_ "GenSigInactiveValue" SG_ 974 LBMSAD_SOH 0;
BA_ "GenSigInvalidValue" SG_ 974 LBMSAD_SOH 0;
BA_ "GenSigSendType" SG_ 974 LBMSAD_SOH 1;
BA_ "GenSigStartValue" SG_ 974 LBMSAD_SOH 255;
BA_ "GenSigTimeoutValue" SG_ 974 LBMSAD_SOH 0;
BA_ "Remark" SG_ 974 LBMSAD_SOH "";
BA_ "EventCommandSignal" SG_ 974 LBMSAD_SOHVD 0;
BA_ "GatewayedSignals" SG_ 974 LBMSAD_SOHVD 0;
BA_ "GenSigInactiveValue" SG_ 974 LBMSAD_SOHVD 0;
BA_ "GenSigInvalidValue" SG_ 974 LBMSAD_SOHVD 0;
BA_ "GenSigSendType" SG_ 974 LBMSAD_SOHVD 1;
BA_ "GenSigStartValue" SG_ 974 LBMSAD_SOHVD 0;
BA_ "GenSigTimeoutValue" SG_ 974 LBMSAD_SOHVD 0;
BA_ "Remark" SG_ 974 LBMSAD_SOHVD "";
BA_ "EventCommandSignal" SG_ 974 LBMSAD_Current 0;
BA_ "GatewayedSignals" SG_ 974 LBMSAD_Current 0;
BA_ "GenSigInactiveValue" SG_ 974 LBMSAD_Current 0;
BA_ "GenSigInvalidValue" SG_ 974 LBMSAD_Current 0;
BA_ "GenSigSendType" SG_ 974 LBMSAD_Current 1;
BA_ "GenSigStartValue" SG_ 974 LBMSAD_Current 4194303;
BA_ "GenSigTimeoutValue" SG_ 974 LBMSAD_Current 0;
BA_ "Remark" SG_ 974 LBMSAD_Current "";
BA_ "EventCommandSignal" SG_ 974 LBMSAD_CellTotVolt 0;
BA_ "GatewayedSignals" SG_ 974 LBMSAD_CellTotVolt 0;
BA_ "GenSigInactiveValue" SG_ 974 LBMSAD_CellTotVolt 0;
BA_ "GenSigInvalidValue" SG_ 974 LBMSAD_CellTotVolt 0;
BA_ "GenSigSendType" SG_ 974 LBMSAD_CellTotVolt 1;
BA_ "GenSigStartValue" SG_ 974 LBMSAD_CellTotVolt 2047;
BA_ "GenSigTimeoutValue" SG_ 974 LBMSAD_CellTotVolt 0;
BA_ "Remark" SG_ 974 LBMSAD_CellTotVolt "";
BA_ "EventCommandSignal" SG_ 974 LBMSAD_CellTotVoltVD 0;
BA_ "GatewayedSignals" SG_ 974 LBMSAD_CellTotVoltVD 0;
BA_ "GenSigInactiveValue" SG_ 974 LBMSAD_CellTotVoltVD 0;
BA_ "GenSigInvalidValue" SG_ 974 LBMSAD_CellTotVoltVD 0;
BA_ "GenSigSendType" SG_ 974 LBMSAD_CellTotVoltVD 1;
BA_ "GenSigStartValue" SG_ 974 LBMSAD_CellTotVoltVD 0;
BA_ "GenSigTimeoutValue" SG_ 974 LBMSAD_CellTotVoltVD 0;
BA_ "Remark" SG_ 974 LBMSAD_CellTotVoltVD "";
BA_ "EventCommandSignal" SG_ 974 LBMSAD_ChargReqEn 0;
BA_ "GatewayedSignals" SG_ 974 LBMSAD_ChargReqEn 0;
BA_ "GenSigInactiveValue" SG_ 974 LBMSAD_ChargReqEn 0;
BA_ "GenSigInvalidValue" SG_ 974 LBMSAD_ChargReqEn 0;
BA_ "GenSigSendType" SG_ 974 LBMSAD_ChargReqEn 1;
BA_ "GenSigStartValue" SG_ 974 LBMSAD_ChargReqEn 0;
BA_ "GenSigTimeoutValue" SG_ 974 LBMSAD_ChargReqEn 0;
BA_ "Remark" SG_ 974 LBMSAD_ChargReqEn "";
BA_ "EventCommandSignal" SG_ 974 LBMSAD_WorkSt 0;
BA_ "GatewayedSignals" SG_ 974 LBMSAD_WorkSt 0;
BA_ "GenSigInactiveValue" SG_ 974 LBMSAD_WorkSt 0;
BA_ "GenSigInvalidValue" SG_ 974 LBMSAD_WorkSt 0;
BA_ "GenSigSendType" SG_ 974 LBMSAD_WorkSt 1;
BA_ "GenSigStartValue" SG_ 974 LBMSAD_WorkSt 0;
BA_ "GenSigTimeoutValue" SG_ 974 LBMSAD_WorkSt 0;
BA_ "Remark" SG_ 974 LBMSAD_WorkSt "";
BA_ "EventCommandSignal" SG_ 974 LBMSAD_MOSSt 0;
BA_ "GatewayedSignals" SG_ 974 LBMSAD_MOSSt 0;
BA_ "GenSigInactiveValue" SG_ 974 LBMSAD_MOSSt 0;
BA_ "GenSigInvalidValue" SG_ 974 LBMSAD_MOSSt 0;
BA_ "GenSigSendType" SG_ 974 LBMSAD_MOSSt 1;
BA_ "GenSigStartValue" SG_ 974 LBMSAD_MOSSt 7;
BA_ "GenSigTimeoutValue" SG_ 974 LBMSAD_MOSSt 0;
BA_ "Remark" SG_ 974 LBMSAD_MOSSt "";
BA_ "EventCommandSignal" SG_ 974 LBMSAD_WireHarnConSt 0;
BA_ "GatewayedSignals" SG_ 974 LBMSAD_WireHarnConSt 0;
BA_ "GenSigInactiveValue" SG_ 974 LBMSAD_WireHarnConSt 0;
BA_ "GenSigInvalidValue" SG_ 974 LBMSAD_WireHarnConSt 1;
BA_ "GenSigSendType" SG_ 974 LBMSAD_WireHarnConSt 1;
BA_ "GenSigStartValue" SG_ 974 LBMSAD_WireHarnConSt 0;
BA_ "GenSigTimeoutValue" SG_ 974 LBMSAD_WireHarnConSt 0;
BA_ "Remark" SG_ 974 LBMSAD_WireHarnConSt "";
BA_ "EventCommandSignal" SG_ 974 LBMSAD_CellMaxVolt 0;
BA_ "GatewayedSignals" SG_ 974 LBMSAD_CellMaxVolt 0;
BA_ "GenSigInactiveValue" SG_ 974 LBMSAD_CellMaxVolt 0;
BA_ "GenSigInvalidValue" SG_ 974 LBMSAD_CellMaxVolt 0;
BA_ "GenSigSendType" SG_ 974 LBMSAD_CellMaxVolt 1;
BA_ "GenSigStartValue" SG_ 974 LBMSAD_CellMaxVolt 8191;
BA_ "GenSigTimeoutValue" SG_ 974 LBMSAD_CellMaxVolt 0;
BA_ "Remark" SG_ 974 LBMSAD_CellMaxVolt "";
BA_ "EventCommandSignal" SG_ 974 LBMSAD_CellMinVolt 0;
BA_ "GatewayedSignals" SG_ 974 LBMSAD_CellMinVolt 0;
BA_ "GenSigInactiveValue" SG_ 974 LBMSAD_CellMinVolt 0;
BA_ "GenSigInvalidValue" SG_ 974 LBMSAD_CellMinVolt 0;
BA_ "GenSigSendType" SG_ 974 LBMSAD_CellMinVolt 1;
BA_ "GenSigStartValue" SG_ 974 LBMSAD_CellMinVolt 8191;
BA_ "GenSigTimeoutValue" SG_ 974 LBMSAD_CellMinVolt 0;
BA_ "Remark" SG_ 974 LBMSAD_CellMinVolt "";
BA_ "EventCommandSignal" SG_ 974 LBMSAD_CellTemp1 0;
BA_ "GatewayedSignals" SG_ 974 LBMSAD_CellTemp1 0;
BA_ "GenSigInactiveValue" SG_ 974 LBMSAD_CellTemp1 0;
BA_ "GenSigInvalidValue" SG_ 974 LBMSAD_CellTemp1 0;
BA_ "GenSigSendType" SG_ 974 LBMSAD_CellTemp1 1;
BA_ "GenSigStartValue" SG_ 974 LBMSAD_CellTemp1 255;
BA_ "GenSigTimeoutValue" SG_ 974 LBMSAD_CellTemp1 0;
BA_ "Remark" SG_ 974 LBMSAD_CellTemp1 "";
BA_ "EventCommandSignal" SG_ 974 LBMSAD_CellTemp2 0;
BA_ "GatewayedSignals" SG_ 974 LBMSAD_CellTemp2 0;
BA_ "GenSigInactiveValue" SG_ 974 LBMSAD_CellTemp2 0;
BA_ "GenSigInvalidValue" SG_ 974 LBMSAD_CellTemp2 0;
BA_ "GenSigSendType" SG_ 974 LBMSAD_CellTemp2 1;
BA_ "GenSigStartValue" SG_ 974 LBMSAD_CellTemp2 255;
BA_ "GenSigTimeoutValue" SG_ 974 LBMSAD_CellTemp2 0;
BA_ "Remark" SG_ 974 LBMSAD_CellTemp2 "";
BA_ "EventCommandSignal" SG_ 974 LBMSAD_CellTemp3 0;
BA_ "GatewayedSignals" SG_ 974 LBMSAD_CellTemp3 0;
BA_ "GenSigInactiveValue" SG_ 974 LBMSAD_CellTemp3 0;
BA_ "GenSigInvalidValue" SG_ 974 LBMSAD_CellTemp3 0;
BA_ "GenSigSendType" SG_ 974 LBMSAD_CellTemp3 1;
BA_ "GenSigStartValue" SG_ 974 LBMSAD_CellTemp3 255;
BA_ "GenSigTimeoutValue" SG_ 974 LBMSAD_CellTemp3 0;
BA_ "Remark" SG_ 974 LBMSAD_CellTemp3 "";
BA_ "EventCommandSignal" SG_ 1316 PLGM_NMNodeAddress 0;
BA_ "GatewayedSignals" SG_ 1316 PLGM_NMNodeAddress 0;
BA_ "GenSigInactiveValue" SG_ 1316 PLGM_NMNodeAddress 0;
BA_ "GenSigInvalidValue" SG_ 1316 PLGM_NMNodeAddress 0;
BA_ "GenSigSendType" SG_ 1316 PLGM_NMNodeAddress 1;
BA_ "GenSigStartValue" SG_ 1316 PLGM_NMNodeAddress 115;
BA_ "GenSigTimeoutValue" SG_ 1316 PLGM_NMNodeAddress 0;
BA_ "Remark" SG_ 1316 PLGM_NMNodeAddress "";
BA_ "EventCommandSignal" SG_ 1316 PLGM_NMCBV 0;
BA_ "GatewayedSignals" SG_ 1316 PLGM_NMCBV 0;
BA_ "GenSigInactiveValue" SG_ 1316 PLGM_NMCBV 0;
BA_ "GenSigInvalidValue" SG_ 1316 PLGM_NMCBV 0;
BA_ "GenSigSendType" SG_ 1316 PLGM_NMCBV 1;
BA_ "GenSigStartValue" SG_ 1316 PLGM_NMCBV 0;
BA_ "GenSigTimeoutValue" SG_ 1316 PLGM_NMCBV 0;
BA_ "Remark" SG_ 1316 PLGM_NMCBV "";
BA_ "EventCommandSignal" SG_ 1316 PLGM_NMWakeupOrigin 0;
BA_ "GatewayedSignals" SG_ 1316 PLGM_NMWakeupOrigin 0;
BA_ "GenSigInactiveValue" SG_ 1316 PLGM_NMWakeupOrigin 0;
BA_ "GenSigInvalidValue" SG_ 1316 PLGM_NMWakeupOrigin 0;
BA_ "GenSigSendType" SG_ 1316 PLGM_NMWakeupOrigin 1;
BA_ "GenSigStartValue" SG_ 1316 PLGM_NMWakeupOrigin 0;
BA_ "GenSigTimeoutValue" SG_ 1316 PLGM_NMWakeupOrigin 0;
BA_ "Remark" SG_ 1316 PLGM_NMWakeupOrigin "";
BA_ "EventCommandSignal" SG_ 1316 PLGM_PNCInformation0 0;
BA_ "GatewayedSignals" SG_ 1316 PLGM_PNCInformation0 0;
BA_ "GenSigInactiveValue" SG_ 1316 PLGM_PNCInformation0 0;
BA_ "GenSigInvalidValue" SG_ 1316 PLGM_PNCInformation0 0;
BA_ "GenSigSendType" SG_ 1316 PLGM_PNCInformation0 1;
BA_ "GenSigStartValue" SG_ 1316 PLGM_PNCInformation0 0;
BA_ "GenSigTimeoutValue" SG_ 1316 PLGM_PNCInformation0 0;
BA_ "Remark" SG_ 1316 PLGM_PNCInformation0 "";
BA_ "EventCommandSignal" SG_ 1316 PLGM_PNCInformation1 0;
BA_ "GatewayedSignals" SG_ 1316 PLGM_PNCInformation1 0;
BA_ "GenSigInactiveValue" SG_ 1316 PLGM_PNCInformation1 0;
BA_ "GenSigInvalidValue" SG_ 1316 PLGM_PNCInformation1 0;
BA_ "GenSigSendType" SG_ 1316 PLGM_PNCInformation1 1;
BA_ "GenSigStartValue" SG_ 1316 PLGM_PNCInformation1 0;
BA_ "GenSigTimeoutValue" SG_ 1316 PLGM_PNCInformation1 0;
BA_ "Remark" SG_ 1316 PLGM_PNCInformation1 "";
BA_ "EventCommandSignal" SG_ 1316 PLGM_PNCInformation2 0;
BA_ "GatewayedSignals" SG_ 1316 PLGM_PNCInformation2 0;
BA_ "GenSigInactiveValue" SG_ 1316 PLGM_PNCInformation2 0;
BA_ "GenSigInvalidValue" SG_ 1316 PLGM_PNCInformation2 0;
BA_ "GenSigSendType" SG_ 1316 PLGM_PNCInformation2 1;
BA_ "GenSigStartValue" SG_ 1316 PLGM_PNCInformation2 0;
BA_ "GenSigTimeoutValue" SG_ 1316 PLGM_PNCInformation2 0;
BA_ "Remark" SG_ 1316 PLGM_PNCInformation2 "";
BA_ "EventCommandSignal" SG_ 387 ADC_4_New_CRC 0;
BA_ "GatewayedSignals" SG_ 387 ADC_4_New_CRC 0;
BA_ "GenSigInactiveValue" SG_ 387 ADC_4_New_CRC 0;
BA_ "GenSigInvalidValue" SG_ 387 ADC_4_New_CRC 0;
BA_ "GenSigSendType" SG_ 387 ADC_4_New_CRC 1;
BA_ "GenSigStartValue" SG_ 387 ADC_4_New_CRC 0;
BA_ "GenSigTimeoutValue" SG_ 387 ADC_4_New_CRC 0;
BA_ "Remark" SG_ 387 ADC_4_New_CRC "";
BA_ "EventCommandSignal" SG_ 387 ADC_4_New_Counter 0;
BA_ "GatewayedSignals" SG_ 387 ADC_4_New_Counter 0;
BA_ "GenSigInactiveValue" SG_ 387 ADC_4_New_Counter 0;
BA_ "GenSigInvalidValue" SG_ 387 ADC_4_New_Counter 0;
BA_ "GenSigSendType" SG_ 387 ADC_4_New_Counter 1;
BA_ "GenSigStartValue" SG_ 387 ADC_4_New_Counter 0;
BA_ "GenSigTimeoutValue" SG_ 387 ADC_4_New_Counter 0;
BA_ "Remark" SG_ 387 ADC_4_New_Counter "";
BA_ "EventCommandSignal" SG_ 387 ADC_AD_NetMode 0;
BA_ "GatewayedSignals" SG_ 387 ADC_AD_NetMode 0;
BA_ "GenSigInactiveValue" SG_ 387 ADC_AD_NetMode 0;
BA_ "GenSigInvalidValue" SG_ 387 ADC_AD_NetMode 0;
BA_ "GenSigSendType" SG_ 387 ADC_AD_NetMode 1;
BA_ "GenSigStartValue" SG_ 387 ADC_AD_NetMode 0;
BA_ "GenSigTimeoutValue" SG_ 387 ADC_AD_NetMode 0;
BA_ "Remark" SG_ 387 ADC_AD_NetMode "";
VAL_ 1016 LBMS_UnSftyLoadCurrentVD 0 "Invalid" 1 "Valid"  ;
VAL_ 1016 LBMS_SfLoadCurrentVD 0 "Invalid" 1 "Valid"  ;
VAL_ 1016 LBMS_ComSoVoltVD 0 "Invalid" 1 "Valid"  ;
VAL_ 1016 LBMS_UnSfLoadComSoVoltVD 0 "Invalid" 1 "Valid"  ;
VAL_ 1016 LBMS_UnsfLoadMosst 0 "All Opened" 1 "All Closed" 2 "Unsafe Load Charge Mos Closed&Unsafe Load Dischrge Mos Opened" 3 "Unsafe Load Charge Mos Opened&Unsafe Load Discharge Mos Closed"  ;
VAL_ 1016 LBMS_UnSfLoadMosTemp1VD 0 "Invalid" 1 "Valid"  ;
VAL_ 1016 LBMS_UnSfLoadMosTemp2VD 0 "Invalid" 1 "Valid"  ;
VAL_ 1016 LBMS_UnSfLoadShuntTempVD 0 "Invalid" 1 "Valid"  ;
VAL_ 1016 LBMS_SfLoadShuntTempVD 0 "Invalid" 1 "Valid"  ;
VAL_ 1016 LBMS_UnSfLoadChgMosDrvVoltVD 0 "Invalid" 1 "Valid"  ;
VAL_ 1016 LBMS_UnSfLoadDsgMosDrvVoltVD 0 "Invalid" 1 "Valid"  ;
VAL_ 1016 LBMS_ChgMosDrvVoltVD 0 "Invalid" 1 "Valid"  ;
VAL_ 1016 LBMS_DsgMosDrvVoltVD 0 "Invalid" 1 "Valid"  ;
VAL_ 1016 LBMS_UnSfLoadFaultOTMOS 0 "No Fault" 1 "LBMS_UnSafeLoad_FaultSt_MOSOT_Level1" 2 "LBMS_UnSafeLoad_FaultSt_MOSOT_Level2" 3 "Occurred LBMS_UnSafeLoad_FaultSt_MOSOT_Level1"  ;
VAL_ 1016 LBMS_UnSfLoadFaultOTS 0 "No Fault" 1 "LBMS_UnSafeLoad_FaultSt_ShuntOT_Level1" 2 "LBMS_UnSafeLoad_FaultSt_ShuntOT_Level2" 3 "Occurred LBMS_UnSafeLoad_FaultSt_ShuntOT_Level1"  ;
VAL_ 1016 LBMS_SfLoadFaultOTS 0 "No Fault" 1 "LBMS_SafeLoad_FaultSt_ShuntOT_Level1" 2 "LBMS_SafeLoad_FaultSt_ShuntOT_Level2" 3 "Occurred LBMS_SafeLoad_FaultSt_ShuntOT_Level1"  ;
VAL_ 1016 LBMS_UnSfLoadFaultChgOC 0 "No Fault" 1 "LBMS_UnSafeLoad_FaultSt_ChgOC_Extremity" 2 "LBMS_UnSafeLoad_FaultSt_ChgOC_Level1" 3 "LBMS_UnSafeLoad_FaultSt_ChgOC_Level2"  ;
VAL_ 1016 LBMS_UnSfLoadFaultDsgOC 0 "No Fault" 1 "LBMS_UnSafeLoad_FaultSt_DsgOC_ShortCircuit" 2 "LBMS_UnSafeLoad_FaultSt_DsgOC_Level1" 3 "LBMS_UnSafeLoad_FaultSt_DsgOC_Level2" 4 "Occurred LBMS_UnSafeLoad_FaultSt_DsgOC_ShortCircuit" 5 "Occurred LBMS_UnSafeLoad_FaultSt_DsgOC_Level1" 6 "Occurred LBMS_UnSafeLoad_FaultSt_DsgOC_Level2" 7 "Reserved"  ;
VAL_ 1016 LBMS_SfLoadFaultDsgOC 0 "No Fault" 1 "LBMS_SafeLoad_FaultSt_DsgOC_ShortCircuit" 2 "LBMS_SafeLoad_FaultSt_DsgOC_Level1" 3 "LBMS_SafeLoad_FaultSt_DsgOC_Level2" 4 "Occurred LBMS_SafeLoad_FaultSt_DsgOC_ShortCircuit" 5 "Occurred LBMS_SafeLoad_FaultSt_DsgOC_Level1" 6 "Occurred LBMS_SafeLoad_FaultSt_DsgOC_Level2" 7 "Reserved"  ;
VAL_ 1016 LBMS_UnSfLoadFaultHardTCMOS 0 "No Fault" 1 "LBMS_UnSafeLoad_FaultSt_Hard_MOSTemSensor;" 2 "LBMS_UnSafeLoad_FaultSt_Hard_MOSTemColShort" 3 "LBMS_UnSafeLoad_FaultSt_Hard_MOSTemColOpen"  ;
VAL_ 1016 LBMS_UnSfLoadFaultHardShunt 0 "No Fault" 1 "LBMS_UnSafeLoad_FaultSt_Hard_ShuntOpen"  ;
VAL_ 1016 LBMS_SfLoadFaultHardShunt 0 "No Fault" 1 "LBMS_SafeLoad_FaultSt_Hard_ShuntOpen"  ;
VAL_ 1016 LBMS_UnSfLoadFaultHardChgMOS 0 "No Fault" 1 "LBMS_UnSafeLoad_FaultSt_Hard_ChgMOSAdhesion" 2 "LBMS_UnSafeLoad_FaultSt_Hard_ChgMOSOpen" 3 "LBMS_UnSafeLoad_FaultSt_Hard_ChgMOSDriverErr"  ;
VAL_ 1016 LBMS_UnSfLoadFaultHardDsgMOS 0 "No Fault" 1 "LBMS_UnSafeLoad_FaultSt_Hard_DsgMOSAdhesion" 2 "LBMS_UnSafeLoad_FaultSt_Hard_DsgMOSOpen" 3 "LBMS_UnSafeLoad_FaultSt_Hard_DsgMOSDriverErr" 4 "Occurred LBMS_FaultSt_Hard_DsgMOSOpen"  ;
VAL_ 1016 LBMS_ChgMosDrvCmd 0 "Open" 1 "Close"  ;
VAL_ 1016 LBMS_DsgMosDrvCmd 0 "Open" 1 "Close"  ;
VAL_ 1016 LBMS_Cell1BalCtrlCmd 0 "Open" 1 "Close"  ;
VAL_ 1016 LBMS_Cell2BalCtrlCmd 0 "Open" 1 "Close"  ;
VAL_ 1016 LBMS_Cell3BalCtrlCmd 0 "Open" 1 "Close"  ;
VAL_ 1016 LBMS_Cell4BalCtrlCmd 0 "Open" 1 "Close"  ;
VAL_ 1016 LBMS_FaultStHardPackVolCol 0 "No Fault" 1 "Fault"  ;
VAL_ 1016 LBMS_FaultStHardUnSfPackVolCol 0 "No Fault" 1 "Fault"  ;
VAL_ 1016 LBMS_PoleTempVD 0 "Invalid" 1 "Valid"  ;
VAL_ 1016 LBMS_SfLoadPoleTempVD 0 "Invalid" 1 "Valid"  ;
VAL_ 1016 LBMS_FaultStHardCellTotVolCol 0 "No Fault" 1 "Fault"  ;
VAL_ 1016 LBMS_FaultStHardComSoVoltCol 0 "No Fault" 1 "Fault"  ;
VAL_ 1016 LBMS_DCDCMosOpenReason 0 "None" 1 "Cell Over Voltage Fault" 2 "Cell Under Voltage Fault" 3 "Cell Total Over Voltage Fault" 4 "Cell Total Under Voltage Fault" 5 "Pack Over Charge Current Fault" 6 "Pack Over Discharge Current Fault" 7 "Pack Over Temperature Fault" 8 "Pack Under Temperature Fault" 9 "Pack Thermal Runaway Fault" 10 "MOS Over Temperature Fault" 11 "MCU Over Temperature Fault" 12 "Shunt Over Temperature Fault" 13 "ChgMosfet Stuck Open Fault" 14 "Pack Output Line Conect Reverse" 15 "LBMS Hardware Fault" 16 "Reserved" 17 "Reserved" 18 "Reserved" 19 "Reserved" 20 "Reserved" 21 "Reserved" 22 "Reserved" 23 "Reserved" 24 "Reserved" 25 "Reserved" 26 "Reserved" 27 "Reserved" 28 "Reserved" 29 "Reserved" 30 "Reserved" 31 "Reserved" 32 "Reserved" 33 "Reserved" 34 "Reserved" 35 "Reserved" 36 "Reserved" 37 "Reserved" 38 "Reserved" 39 "Reserved" 40 "Reserved" 41 "Reserved" 42 "Reserved" 43 "Reserved" 44 "Reserved" 45 "Reserved" 46 "Reserved" 47 "Reserved" 48 "Reserved" 49 "Reserved" 50 "Reserved" 51 "Reserved" 52 "Reserved" 53 "Reserved" 54 "Reserved" 55 "Reserved" 56 "Reserved" 57 "Reserved" 58 "Reserved" 59 "Reserved" 60 "Reserved" 61 "Reserved" 62 "Reserved" 63 "Reserved" 64 "Reserved" 65 "Reserved" 66 "Reserved" 67 "Reserved" 68 "Reserved" 69 "Reserved" 70 "Reserved" 71 "Reserved" 72 "Reserved" 73 "Reserved" 74 "Reserved" 75 "Reserved" 76 "Reserved" 77 "Reserved" 78 "Reserved" 79 "Reserved" 80 "Reserved" 81 "Reserved" 82 "Reserved" 83 "Reserved" 84 "Reserved" 85 "Reserved" 86 "Reserved" 87 "Reserved" 88 "Reserved" 89 "Reserved" 90 "Reserved" 91 "Reserved" 92 "Reserved" 93 "Reserved" 94 "Reserved" 95 "Reserved" 96 "Reserved" 97 "Reserved" 98 "Reserved" 99 "Reserved" 100 "Reserved" 101 "Reserved" 102 "Reserved" 103 "Reserved" 104 "Reserved" 105 "Reserved" 106 "Reserved" 107 "Reserved" 108 "Reserved" 109 "Reserved" 110 "Reserved" 111 "Reserved" 112 "Reserved" 113 "Reserved" 114 "Reserved" 115 "Reserved" 116 "Reserved" 117 "Reserved" 118 "Reserved" 119 "Reserved" 120 "Reserved" 121 "Reserved" 122 "Reserved" 123 "Reserved" 124 "Reserved" 125 "Reserved" 126 "Reserved" 127 "Reserved" 128 "Reserved" 129 "Reserved" 130 "Reserved" 131 "Reserved" 132 "Reserved" 133 "Reserved" 134 "Reserved" 135 "Reserved" 136 "Reserved" 137 "Reserved" 138 "Reserved" 139 "Reserved" 140 "Reserved" 141 "Reserved" 142 "Reserved" 143 "Reserved" 144 "Reserved" 145 "Reserved" 146 "Reserved" 147 "Reserved" 148 "Reserved" 149 "Reserved" 150 "Reserved" 151 "Reserved" 152 "Reserved" 153 "Reserved" 154 "Reserved" 155 "Reserved" 156 "Reserved" 157 "Reserved" 158 "Reserved" 159 "Reserved" 160 "Reserved" 161 "Reserved" 162 "Reserved" 163 "Reserved" 164 "Reserved" 165 "Reserved" 166 "Reserved" 167 "Reserved" 168 "Reserved" 169 "Reserved" 170 "Reserved" 171 "Reserved" 172 "Reserved" 173 "Reserved" 174 "Reserved" 175 "Reserved" 176 "Reserved" 177 "Reserved" 178 "Reserved" 179 "Reserved" 180 "Reserved" 181 "Reserved" 182 "Reserved" 183 "Reserved" 184 "Reserved" 185 "Reserved" 186 "Reserved" 187 "Reserved" 188 "Reserved" 189 "Reserved" 190 "Reserved" 191 "Reserved" 192 "Reserved" 193 "Reserved" 194 "Reserved" 195 "Reserved" 196 "Reserved" 197 "Reserved" 198 "Reserved" 199 "Reserved" 200 "Reserved" 201 "Reserved" 202 "Reserved" 203 "Reserved" 204 "Reserved" 205 "Reserved" 206 "Reserved" 207 "Reserved" 208 "Reserved" 209 "Reserved" 210 "Reserved" 211 "Reserved" 212 "Reserved" 213 "Reserved" 214 "Reserved" 215 "Reserved" 216 "Reserved" 217 "Reserved" 218 "Reserved" 219 "Reserved" 220 "Reserved" 221 "Reserved" 222 "Reserved" 223 "Reserved" 224 "Reserved" 225 "Reserved" 226 "Reserved" 227 "Reserved" 228 "Reserved" 229 "Reserved" 230 "Reserved" 231 "Reserved" 232 "Reserved" 233 "Reserved" 234 "Reserved" 235 "Reserved" 236 "Reserved" 237 "Reserved" 238 "Reserved" 239 "Reserved" 240 "Reserved" 241 "Reserved" 242 "Reserved" 243 "Reserved" 244 "Reserved" 245 "Reserved" 246 "Reserved" 247 "Reserved" 248 "Reserved" 249 "Reserved" 250 "Reserved" 251 "Reserved" 252 "Reserved" 253 "Reserved" 254 "Reserved" 255 "Reserved"  ;
VAL_ 1016 LBMS_AutoChgReason 0 "None" 1 "SOC Satisfy The Thershold of Transport" 2 "SOC Satisfy The Thershold of None Transport" 3 "SOFEN_False" 4 "LBMS_RefChargReq Reach The Thershold" 5 "LBMS_LastFullChargeTime Reach The Thershold" 6 "Reserved" 7 "Reserved"  ;
VAL_ 1016 LBMS_DsgMosOpenReason 0 "None" 1 "Cell Over Voltage Fault" 2 "Cell Under Voltage Fault" 3 "Cell Total Over Voltage Fault" 4 "Cell Total Under Voltage Fault" 5 "Pack Over Charge Current Fault" 6 "Pack Over Discharge Current Fault" 7 "Pack Over Temperature Fault" 8 "Pack Under Temperature Fault" 9 "Pack Thermal Runaway Fault" 10 "MOS Over Temperature Fault" 11 "MCU Over Temperature Fault" 12 "Shunt Over Temperature Fault" 13 "DsgMosfet Stuck Open Fault" 14 "Pack Output Line Conect Reverse" 15 "LBMS Hardware Fault" 16 "Reserved" 17 "Reserved" 18 "Reserved" 19 "Reserved" 20 "Reserved" 21 "Reserved" 22 "Reserved" 23 "Reserved" 24 "Reserved" 25 "Reserved" 26 "Reserved" 27 "Reserved" 28 "Reserved" 29 "Reserved" 30 "Reserved" 31 "Reserved" 32 "Reserved" 33 "Reserved" 34 "Reserved" 35 "Reserved" 36 "Reserved" 37 "Reserved" 38 "Reserved" 39 "Reserved" 40 "Reserved" 41 "Reserved" 42 "Reserved" 43 "Reserved" 44 "Reserved" 45 "Reserved" 46 "Reserved" 47 "Reserved" 48 "Reserved" 49 "Reserved" 50 "Reserved" 51 "Reserved" 52 "Reserved" 53 "Reserved" 54 "Reserved" 55 "Reserved" 56 "Reserved" 57 "Reserved" 58 "Reserved" 59 "Reserved" 60 "Reserved" 61 "Reserved" 62 "Reserved" 63 "Reserved" 64 "Reserved" 65 "Reserved" 66 "Reserved" 67 "Reserved" 68 "Reserved" 69 "Reserved" 70 "Reserved" 71 "Reserved" 72 "Reserved" 73 "Reserved" 74 "Reserved" 75 "Reserved" 76 "Reserved" 77 "Reserved" 78 "Reserved" 79 "Reserved" 80 "Reserved" 81 "Reserved" 82 "Reserved" 83 "Reserved" 84 "Reserved" 85 "Reserved" 86 "Reserved" 87 "Reserved" 88 "Reserved" 89 "Reserved" 90 "Reserved" 91 "Reserved" 92 "Reserved" 93 "Reserved" 94 "Reserved" 95 "Reserved" 96 "Reserved" 97 "Reserved" 98 "Reserved" 99 "Reserved" 100 "Reserved" 101 "Reserved" 102 "Reserved" 103 "Reserved" 104 "Reserved" 105 "Reserved" 106 "Reserved" 107 "Reserved" 108 "Reserved" 109 "Reserved" 110 "Reserved" 111 "Reserved" 112 "Reserved" 113 "Reserved" 114 "Reserved" 115 "Reserved" 116 "Reserved" 117 "Reserved" 118 "Reserved" 119 "Reserved" 120 "Reserved" 121 "Reserved" 122 "Reserved" 123 "Reserved" 124 "Reserved" 125 "Reserved" 126 "Reserved" 127 "Reserved" 128 "Reserved" 129 "Reserved" 130 "Reserved" 131 "Reserved" 132 "Reserved" 133 "Reserved" 134 "Reserved" 135 "Reserved" 136 "Reserved" 137 "Reserved" 138 "Reserved" 139 "Reserved" 140 "Reserved" 141 "Reserved" 142 "Reserved" 143 "Reserved" 144 "Reserved" 145 "Reserved" 146 "Reserved" 147 "Reserved" 148 "Reserved" 149 "Reserved" 150 "Reserved" 151 "Reserved" 152 "Reserved" 153 "Reserved" 154 "Reserved" 155 "Reserved" 156 "Reserved" 157 "Reserved" 158 "Reserved" 159 "Reserved" 160 "Reserved" 161 "Reserved" 162 "Reserved" 163 "Reserved" 164 "Reserved" 165 "Reserved" 166 "Reserved" 167 "Reserved" 168 "Reserved" 169 "Reserved" 170 "Reserved" 171 "Reserved" 172 "Reserved" 173 "Reserved" 174 "Reserved" 175 "Reserved" 176 "Reserved" 177 "Reserved" 178 "Reserved" 179 "Reserved" 180 "Reserved" 181 "Reserved" 182 "Reserved" 183 "Reserved" 184 "Reserved" 185 "Reserved" 186 "Reserved" 187 "Reserved" 188 "Reserved" 189 "Reserved" 190 "Reserved" 191 "Reserved" 192 "Reserved" 193 "Reserved" 194 "Reserved" 195 "Reserved" 196 "Reserved" 197 "Reserved" 198 "Reserved" 199 "Reserved" 200 "Reserved" 201 "Reserved" 202 "Reserved" 203 "Reserved" 204 "Reserved" 205 "Reserved" 206 "Reserved" 207 "Reserved" 208 "Reserved" 209 "Reserved" 210 "Reserved" 211 "Reserved" 212 "Reserved" 213 "Reserved" 214 "Reserved" 215 "Reserved" 216 "Reserved" 217 "Reserved" 218 "Reserved" 219 "Reserved" 220 "Reserved" 221 "Reserved" 222 "Reserved" 223 "Reserved" 224 "Reserved" 225 "Reserved" 226 "Reserved" 227 "Reserved" 228 "Reserved" 229 "Reserved" 230 "Reserved" 231 "Reserved" 232 "Reserved" 233 "Reserved" 234 "Reserved" 235 "Reserved" 236 "Reserved" 237 "Reserved" 238 "Reserved" 239 "Reserved" 240 "Reserved" 241 "Reserved" 242 "Reserved" 243 "Reserved" 244 "Reserved" 245 "Reserved" 246 "Reserved" 247 "Reserved" 248 "Reserved" 249 "Reserved" 250 "Reserved" 251 "Reserved" 252 "Reserved" 253 "Reserved" 254 "Reserved" 255 "Reserved"  ;
VAL_ 1016 LBMS_ChgMosOpenReason 0 "None" 1 "Cell Over Voltage Fault" 2 "Cell Under Voltage Fault" 3 "Cell Total Over Voltage Fault" 4 "Cell Total Under Voltage Fault" 5 "Pack Over Charge Current Fault" 6 "Pack Over Discharge Current Fault" 7 "Pack Over Temperature Fault" 8 "Pack Under Temperature Fault" 9 "Pack Thermal Runaway Fault" 10 "MOS Over Temperature Fault" 11 "MCU Over Temperature Fault" 12 "Shunt Over Temperature Fault" 13 "ChgMosfet Stuck Open Fault" 14 "Pack Output Line Conect Reverse" 15 "LBMS Hardware Fault" 16 "Reserved" 17 "Reserved" 18 "Reserved" 19 "Reserved" 20 "Reserved" 21 "Reserved" 22 "Reserved" 23 "Reserved" 24 "Reserved" 25 "Reserved" 26 "Reserved" 27 "Reserved" 28 "Reserved" 29 "Reserved" 30 "Reserved" 31 "Reserved" 32 "Reserved" 33 "Reserved" 34 "Reserved" 35 "Reserved" 36 "Reserved" 37 "Reserved" 38 "Reserved" 39 "Reserved" 40 "Reserved" 41 "Reserved" 42 "Reserved" 43 "Reserved" 44 "Reserved" 45 "Reserved" 46 "Reserved" 47 "Reserved" 48 "Reserved" 49 "Reserved" 50 "Reserved" 51 "Reserved" 52 "Reserved" 53 "Reserved" 54 "Reserved" 55 "Reserved" 56 "Reserved" 57 "Reserved" 58 "Reserved" 59 "Reserved" 60 "Reserved" 61 "Reserved" 62 "Reserved" 63 "Reserved" 64 "Reserved" 65 "Reserved" 66 "Reserved" 67 "Reserved" 68 "Reserved" 69 "Reserved" 70 "Reserved" 71 "Reserved" 72 "Reserved" 73 "Reserved" 74 "Reserved" 75 "Reserved" 76 "Reserved" 77 "Reserved" 78 "Reserved" 79 "Reserved" 80 "Reserved" 81 "Reserved" 82 "Reserved" 83 "Reserved" 84 "Reserved" 85 "Reserved" 86 "Reserved" 87 "Reserved" 88 "Reserved" 89 "Reserved" 90 "Reserved" 91 "Reserved" 92 "Reserved" 93 "Reserved" 94 "Reserved" 95 "Reserved" 96 "Reserved" 97 "Reserved" 98 "Reserved" 99 "Reserved" 100 "Reserved" 101 "Reserved" 102 "Reserved" 103 "Reserved" 104 "Reserved" 105 "Reserved" 106 "Reserved" 107 "Reserved" 108 "Reserved" 109 "Reserved" 110 "Reserved" 111 "Reserved" 112 "Reserved" 113 "Reserved" 114 "Reserved" 115 "Reserved" 116 "Reserved" 117 "Reserved" 118 "Reserved" 119 "Reserved" 120 "Reserved" 121 "Reserved" 122 "Reserved" 123 "Reserved" 124 "Reserved" 125 "Reserved" 126 "Reserved" 127 "Reserved" 128 "Reserved" 129 "Reserved" 130 "Reserved" 131 "Reserved" 132 "Reserved" 133 "Reserved" 134 "Reserved" 135 "Reserved" 136 "Reserved" 137 "Reserved" 138 "Reserved" 139 "Reserved" 140 "Reserved" 141 "Reserved" 142 "Reserved" 143 "Reserved" 144 "Reserved" 145 "Reserved" 146 "Reserved" 147 "Reserved" 148 "Reserved" 149 "Reserved" 150 "Reserved" 151 "Reserved" 152 "Reserved" 153 "Reserved" 154 "Reserved" 155 "Reserved" 156 "Reserved" 157 "Reserved" 158 "Reserved" 159 "Reserved" 160 "Reserved" 161 "Reserved" 162 "Reserved" 163 "Reserved" 164 "Reserved" 165 "Reserved" 166 "Reserved" 167 "Reserved" 168 "Reserved" 169 "Reserved" 170 "Reserved" 171 "Reserved" 172 "Reserved" 173 "Reserved" 174 "Reserved" 175 "Reserved" 176 "Reserved" 177 "Reserved" 178 "Reserved" 179 "Reserved" 180 "Reserved" 181 "Reserved" 182 "Reserved" 183 "Reserved" 184 "Reserved" 185 "Reserved" 186 "Reserved" 187 "Reserved" 188 "Reserved" 189 "Reserved" 190 "Reserved" 191 "Reserved" 192 "Reserved" 193 "Reserved" 194 "Reserved" 195 "Reserved" 196 "Reserved" 197 "Reserved" 198 "Reserved" 199 "Reserved" 200 "Reserved" 201 "Reserved" 202 "Reserved" 203 "Reserved" 204 "Reserved" 205 "Reserved" 206 "Reserved" 207 "Reserved" 208 "Reserved" 209 "Reserved" 210 "Reserved" 211 "Reserved" 212 "Reserved" 213 "Reserved" 214 "Reserved" 215 "Reserved" 216 "Reserved" 217 "Reserved" 218 "Reserved" 219 "Reserved" 220 "Reserved" 221 "Reserved" 222 "Reserved" 223 "Reserved" 224 "Reserved" 225 "Reserved" 226 "Reserved" 227 "Reserved" 228 "Reserved" 229 "Reserved" 230 "Reserved" 231 "Reserved" 232 "Reserved" 233 "Reserved" 234 "Reserved" 235 "Reserved" 236 "Reserved" 237 "Reserved" 238 "Reserved" 239 "Reserved" 240 "Reserved" 241 "Reserved" 242 "Reserved" 243 "Reserved" 244 "Reserved" 245 "Reserved" 246 "Reserved" 247 "Reserved" 248 "Reserved" 249 "Reserved" 250 "Reserved" 251 "Reserved" 252 "Reserved" 253 "Reserved" 254 "Reserved" 255 "Reserved"  ;
VAL_ 1016 LBMS_LocalNotSleep_Reason 0 "No wakeup" 1 "wakeup by MCU reset" 2 "wakeup by OV" 3 "wakeup by RTC" 4 "wakeup by OT" 5 "wakeup by OC" 6 "wakeup by Hardwire" 7 "wakeup by short-circuit protection" 8 "wakeup by Bonding power"  ;
VAL_ 1016 LBMS_SfUpackRvsVoltVD 0 "Invalid" 1 "Valid"  ;
VAL_ 1016 LBMS_SfFaultStHardComSoVoltCol 0 "No Fault" 1 "Fault"  ;
VAL_ 1016 LBMS_SfChgMosDrvCmd 0 "Open" 1 "Close"  ;
VAL_ 1016 LBMS_SfDsgMosDrvCmd 0 "Open" 1 "Close"  ;
VAL_ 1016 LBMS_SfLoadUpackRvsVoltVD 0 "Invalid" 1 "Valid"  ;
VAL_ 1016 LBMS_UnSfLoadChgMosDrvCmd 0 "Open" 1 "Close"  ;
VAL_ 1016 LBMS_UnSfLoadDsgMosDrvCmd 0 "Open" 1 "Close"  ;
VAL_ 1016 LBMS_UnsfLoadDsgMosOpenReason 0 "None" 1 "Cell Over Voltage Fault" 2 "Cell Under Voltage Fault" 3 "Cell Total Over Voltage Fault" 4 "Cell Total Under Voltage Fault" 5 "Pack Over Charge Current Fault" 6 "Pack Over Discharge Current Fault" 7 "Pack Over Temperature Fault" 8 "Pack Under Temperature Fault" 9 "Pack Thermal Runaway Fault" 10 "MOS Over Temperature Fault" 11 "MCU Over Temperature Fault" 12 "Shunt Over Temperature Fault" 13 "DsgMosfet Stuck Open Fault" 14 "Pack Output Line Conect Reverse" 15 "LBMS Hardware Fault" 16 "Reserved" 17 "Reserved" 18 "Reserved" 19 "Reserved" 20 "Reserved" 21 "Reserved" 22 "Reserved" 23 "Reserved" 24 "Reserved" 25 "Reserved" 26 "Reserved" 27 "Reserved" 28 "Reserved" 29 "Reserved" 30 "Reserved" 31 "Reserved" 32 "Reserved" 33 "Reserved" 34 "Reserved" 35 "Reserved" 36 "Reserved" 37 "Reserved" 38 "Reserved" 39 "Reserved" 40 "Reserved" 41 "Reserved" 42 "Reserved" 43 "Reserved" 44 "Reserved" 45 "Reserved" 46 "Reserved" 47 "Reserved" 48 "Reserved" 49 "Reserved" 50 "Reserved" 51 "Reserved" 52 "Reserved" 53 "Reserved" 54 "Reserved" 55 "Reserved" 56 "Reserved" 57 "Reserved" 58 "Reserved" 59 "Reserved" 60 "Reserved" 61 "Reserved" 62 "Reserved" 63 "Reserved" 64 "Reserved" 65 "Reserved" 66 "Reserved" 67 "Reserved" 68 "Reserved" 69 "Reserved" 70 "Reserved" 71 "Reserved" 72 "Reserved" 73 "Reserved" 74 "Reserved" 75 "Reserved" 76 "Reserved" 77 "Reserved" 78 "Reserved" 79 "Reserved" 80 "Reserved" 81 "Reserved" 82 "Reserved" 83 "Reserved" 84 "Reserved" 85 "Reserved" 86 "Reserved" 87 "Reserved" 88 "Reserved" 89 "Reserved" 90 "Reserved" 91 "Reserved" 92 "Reserved" 93 "Reserved" 94 "Reserved" 95 "Reserved" 96 "Reserved" 97 "Reserved" 98 "Reserved" 99 "Reserved" 100 "Reserved" 101 "Reserved" 102 "Reserved" 103 "Reserved" 104 "Reserved" 105 "Reserved" 106 "Reserved" 107 "Reserved" 108 "Reserved" 109 "Reserved" 110 "Reserved" 111 "Reserved" 112 "Reserved" 113 "Reserved" 114 "Reserved" 115 "Reserved" 116 "Reserved" 117 "Reserved" 118 "Reserved" 119 "Reserved" 120 "Reserved" 121 "Reserved" 122 "Reserved" 123 "Reserved" 124 "Reserved" 125 "Reserved" 126 "Reserved" 127 "Reserved" 128 "Reserved" 129 "Reserved" 130 "Reserved" 131 "Reserved" 132 "Reserved" 133 "Reserved" 134 "Reserved" 135 "Reserved" 136 "Reserved" 137 "Reserved" 138 "Reserved" 139 "Reserved" 140 "Reserved" 141 "Reserved" 142 "Reserved" 143 "Reserved" 144 "Reserved" 145 "Reserved" 146 "Reserved" 147 "Reserved" 148 "Reserved" 149 "Reserved" 150 "Reserved" 151 "Reserved" 152 "Reserved" 153 "Reserved" 154 "Reserved" 155 "Reserved" 156 "Reserved" 157 "Reserved" 158 "Reserved" 159 "Reserved" 160 "Reserved" 161 "Reserved" 162 "Reserved" 163 "Reserved" 164 "Reserved" 165 "Reserved" 166 "Reserved" 167 "Reserved" 168 "Reserved" 169 "Reserved" 170 "Reserved" 171 "Reserved" 172 "Reserved" 173 "Reserved" 174 "Reserved" 175 "Reserved" 176 "Reserved" 177 "Reserved" 178 "Reserved" 179 "Reserved" 180 "Reserved" 181 "Reserved" 182 "Reserved" 183 "Reserved" 184 "Reserved" 185 "Reserved" 186 "Reserved" 187 "Reserved" 188 "Reserved" 189 "Reserved" 190 "Reserved" 191 "Reserved" 192 "Reserved" 193 "Reserved" 194 "Reserved" 195 "Reserved" 196 "Reserved" 197 "Reserved" 198 "Reserved" 199 "Reserved" 200 "Reserved" 201 "Reserved" 202 "Reserved" 203 "Reserved" 204 "Reserved" 205 "Reserved" 206 "Reserved" 207 "Reserved" 208 "Reserved" 209 "Reserved" 210 "Reserved" 211 "Reserved" 212 "Reserved" 213 "Reserved" 214 "Reserved" 215 "Reserved" 216 "Reserved" 217 "Reserved" 218 "Reserved" 219 "Reserved" 220 "Reserved" 221 "Reserved" 222 "Reserved" 223 "Reserved" 224 "Reserved" 225 "Reserved" 226 "Reserved" 227 "Reserved" 228 "Reserved" 229 "Reserved" 230 "Reserved" 231 "Reserved" 232 "Reserved" 233 "Reserved" 234 "Reserved" 235 "Reserved" 236 "Reserved" 237 "Reserved" 238 "Reserved" 239 "Reserved" 240 "Reserved" 241 "Reserved" 242 "Reserved" 243 "Reserved" 244 "Reserved" 245 "Reserved" 246 "Reserved" 247 "Reserved" 248 "Reserved" 249 "Reserved" 250 "Reserved" 251 "Reserved" 252 "Reserved" 253 "Reserved" 254 "Reserved" 255 "Reserved"  ;
VAL_ 1016 LBMS_UnsfLoadChgMosOpenReason 0 "None" 1 "Cell Over Voltage Fault" 2 "Cell Under Voltage Fault" 3 "Cell Total Over Voltage Fault" 4 "Cell Total Under Voltage Fault" 5 "Pack Over Charge Current Fault" 6 "Pack Over Discharge Current Fault" 7 "Pack Over Temperature Fault" 8 "Pack Under Temperature Fault" 9 "Pack Thermal Runaway Fault" 10 "MOS Over Temperature Fault" 11 "MCU Over Temperature Fault" 12 "Shunt Over Temperature Fault" 13 "ChgMosfet Stuck Open Fault" 14 "Pack Output Line Conect Reverse" 15 "LBMS Hardware Fault" 16 "Reserved" 17 "Reserved" 18 "Reserved" 19 "Reserved" 20 "Reserved" 21 "Reserved" 22 "Reserved" 23 "Reserved" 24 "Reserved" 25 "Reserved" 26 "Reserved" 27 "Reserved" 28 "Reserved" 29 "Reserved" 30 "Reserved" 31 "Reserved" 32 "Reserved" 33 "Reserved" 34 "Reserved" 35 "Reserved" 36 "Reserved" 37 "Reserved" 38 "Reserved" 39 "Reserved" 40 "Reserved" 41 "Reserved" 42 "Reserved" 43 "Reserved" 44 "Reserved" 45 "Reserved" 46 "Reserved" 47 "Reserved" 48 "Reserved" 49 "Reserved" 50 "Reserved" 51 "Reserved" 52 "Reserved" 53 "Reserved" 54 "Reserved" 55 "Reserved" 56 "Reserved" 57 "Reserved" 58 "Reserved" 59 "Reserved" 60 "Reserved" 61 "Reserved" 62 "Reserved" 63 "Reserved" 64 "Reserved" 65 "Reserved" 66 "Reserved" 67 "Reserved" 68 "Reserved" 69 "Reserved" 70 "Reserved" 71 "Reserved" 72 "Reserved" 73 "Reserved" 74 "Reserved" 75 "Reserved" 76 "Reserved" 77 "Reserved" 78 "Reserved" 79 "Reserved" 80 "Reserved" 81 "Reserved" 82 "Reserved" 83 "Reserved" 84 "Reserved" 85 "Reserved" 86 "Reserved" 87 "Reserved" 88 "Reserved" 89 "Reserved" 90 "Reserved" 91 "Reserved" 92 "Reserved" 93 "Reserved" 94 "Reserved" 95 "Reserved" 96 "Reserved" 97 "Reserved" 98 "Reserved" 99 "Reserved" 100 "Reserved" 101 "Reserved" 102 "Reserved" 103 "Reserved" 104 "Reserved" 105 "Reserved" 106 "Reserved" 107 "Reserved" 108 "Reserved" 109 "Reserved" 110 "Reserved" 111 "Reserved" 112 "Reserved" 113 "Reserved" 114 "Reserved" 115 "Reserved" 116 "Reserved" 117 "Reserved" 118 "Reserved" 119 "Reserved" 120 "Reserved" 121 "Reserved" 122 "Reserved" 123 "Reserved" 124 "Reserved" 125 "Reserved" 126 "Reserved" 127 "Reserved" 128 "Reserved" 129 "Reserved" 130 "Reserved" 131 "Reserved" 132 "Reserved" 133 "Reserved" 134 "Reserved" 135 "Reserved" 136 "Reserved" 137 "Reserved" 138 "Reserved" 139 "Reserved" 140 "Reserved" 141 "Reserved" 142 "Reserved" 143 "Reserved" 144 "Reserved" 145 "Reserved" 146 "Reserved" 147 "Reserved" 148 "Reserved" 149 "Reserved" 150 "Reserved" 151 "Reserved" 152 "Reserved" 153 "Reserved" 154 "Reserved" 155 "Reserved" 156 "Reserved" 157 "Reserved" 158 "Reserved" 159 "Reserved" 160 "Reserved" 161 "Reserved" 162 "Reserved" 163 "Reserved" 164 "Reserved" 165 "Reserved" 166 "Reserved" 167 "Reserved" 168 "Reserved" 169 "Reserved" 170 "Reserved" 171 "Reserved" 172 "Reserved" 173 "Reserved" 174 "Reserved" 175 "Reserved" 176 "Reserved" 177 "Reserved" 178 "Reserved" 179 "Reserved" 180 "Reserved" 181 "Reserved" 182 "Reserved" 183 "Reserved" 184 "Reserved" 185 "Reserved" 186 "Reserved" 187 "Reserved" 188 "Reserved" 189 "Reserved" 190 "Reserved" 191 "Reserved" 192 "Reserved" 193 "Reserved" 194 "Reserved" 195 "Reserved" 196 "Reserved" 197 "Reserved" 198 "Reserved" 199 "Reserved" 200 "Reserved" 201 "Reserved" 202 "Reserved" 203 "Reserved" 204 "Reserved" 205 "Reserved" 206 "Reserved" 207 "Reserved" 208 "Reserved" 209 "Reserved" 210 "Reserved" 211 "Reserved" 212 "Reserved" 213 "Reserved" 214 "Reserved" 215 "Reserved" 216 "Reserved" 217 "Reserved" 218 "Reserved" 219 "Reserved" 220 "Reserved" 221 "Reserved" 222 "Reserved" 223 "Reserved" 224 "Reserved" 225 "Reserved" 226 "Reserved" 227 "Reserved" 228 "Reserved" 229 "Reserved" 230 "Reserved" 231 "Reserved" 232 "Reserved" 233 "Reserved" 234 "Reserved" 235 "Reserved" 236 "Reserved" 237 "Reserved" 238 "Reserved" 239 "Reserved" 240 "Reserved" 241 "Reserved" 242 "Reserved" 243 "Reserved" 244 "Reserved" 245 "Reserved" 246 "Reserved" 247 "Reserved" 248 "Reserved" 249 "Reserved" 250 "Reserved" 251 "Reserved" 252 "Reserved" 253 "Reserved" 254 "Reserved" 255 "Reserved"  ;
VAL_ 1016 LBMS_FaultStHarddUnSfComSoVoltCol 0 "No Fault" 1 "Fault"  ;
VAL_ 794 LBMSAD_SOFVD 0 "Invalid" 1 "Valid"  ;
VAL_ 794 LBMSAD_SOFEN 0 "Keep to the side parking False,Original lane parking False" 1 "Keep to the side parking True,Original lane parking False" 2 "Keep to the side parking False,Original lane parking True" 3 "Keep to the side parking True,Original lane parking True"  ;
VAL_ 794 LBMSAD_ChargReq 0 "No Charge Request" 1 "Low SOC Charge Request" 2 "Low Volt Charge Request"  ;
VAL_ 794 LBMSAD_SOCVD 0 "Invalid" 1 "Valid"  ;
VAL_ 794 LBMSAD_AlrmDispSt 0 "No alarm" 1 "fault" 2 "Low power to lock" 3 "Thermal Out of Control" 4 "Low power to EOL" 5 "Low power to lock of Transport Mode" 6 "SOH low" 7 "SOF low"  ;
VAL_ 794 LBMSAD_CurrentRange 0 "current range (0A,0.3A]" 1 "current range (0.3A,1500A]" 2 "current range (-1500A,0A]" 3 "Reserved"  ;
VAL_ 794 LBMSAD_RefChargReq 0 "No Refesh Charge Request" 1 "Refesh  Charge Request"  ;
VAL_ 794 LBMSAD_ThermalRunawayErr 0 "No Error" 1 "Process Error" 2 "Mauture Error" 3 "Reserved"  ;
VAL_ 794 LBMSAD_IPDS_BAT1PowerReq 0 "Open" 1 "Close"  ;
VAL_ 794 LBMSAD_IPDS_BAT2PowerReq 0 "Open" 1 "Close"  ;
VAL_ 794 LBMSAD_IPDS_GridlsoPowerReq 0 "Open" 1 "Close"  ;
VAL_ 974 LBMSAD_SOHVD 0 "Invalid" 1 "Valid"  ;
VAL_ 974 LBMSAD_CellTotVoltVD 0 "Invalid" 1 "Valid"  ;
VAL_ 974 LBMSAD_ChargReqEn 0 "Disable" 1 "Enable"  ;
VAL_ 974 LBMSAD_WorkSt 0 "Init" 1 "Discharge" 2 "Voltage Regulation Charge" 3 "Full Charge Mode" 4 "Float Charge Mode" 5 "DCDC Charge" 6 "FAULT" 7 "Blind Charge"  ;
VAL_ 974 LBMSAD_MOSSt 0 "All Opened" 1 "All Closed" 2 "Charge Mos Closed&Dischrge Mos Opened" 3 "Charge Mos Opened&Discharge Mos Closed"  ;
VAL_ 974 LBMSAD_WireHarnConSt 0 "Normal" 1 "Fault"  ;
VAL_ 1316 PLGM_NMCBV 0 "Node has not woken up the    network(passive wakeup);" 1 "Node has woken up the network(active wakeup)" 0 "NM PDU contains no Partial Network request information" 1 "NM PDU contains Partial Network request information"  ;
VAL_ 1316 PLGM_NMWakeupOrigin 0 "Not used" 1 "Message wake up" 2 "Not Used" 3 "Not Used" 4 "Not Used" 5 "Not Used" 6 "Not Used" 7 "Not Used" 8 "Not Used" 9 "Not Used" 10 "Not Used" 11 "Not Used" 12 "Not Used" 13 "Not Used" 14 "Not Used" 15 "Not Used" 16 "Not Used" 17 "LatchAjarSW" 18 "LatchDetentSW" 19 "Inside Gate close SW" 20 "Hall" 21 "LatchHalfSW" 22 "Reserved" 23 "Reserved" 24 "Reserved" 25 "Reserved" 26 "Reserved" 27 "Reserved" 28 "Reserved" 29 "Reserved" 30 "Reserved" 31 "Reserved" 32 "Reserved" 33 "Reserved" 34 "Reserved" 35 "Reserved" 36 "Reserved" 37 "Reserved" 38 "Reserved" 39 "Reserved" 40 "Reserved" 41 "Reserved" 42 "Reserved" 43 "Reserved" 44 "Reserved" 45 "Reserved" 46 "Reserved" 47 "Reserved" 48 "Reserved" 49 "Reserved" 50 "Reserved" 51 "Reserved" 52 "Reserved" 53 "Reserved" 54 "Reserved" 55 "Reserved" 56 "Reserved" 57 "Reserved" 58 "Reserved" 59 "Reserved" 60 "Reserved" 61 "Reserved" 62 "Reserved" 63 "Reserved" 64 "Reserved" 65 "Reserved" 66 "Reserved" 67 "Reserved" 68 "Reserved" 69 "Reserved" 70 "Reserved" 71 "Reserved" 72 "Reserved" 73 "Reserved" 74 "Reserved" 75 "Reserved" 76 "Reserved" 77 "Reserved" 78 "Reserved" 79 "Reserved" 80 "Reserved" 81 "Reserved" 82 "Reserved" 83 "Reserved" 84 "Reserved" 85 "Reserved" 86 "Reserved" 87 "Reserved" 88 "Reserved" 89 "Reserved" 90 "Reserved" 91 "Reserved" 92 "Reserved" 93 "Reserved" 94 "Reserved" 95 "Reserved" 96 "Reserved" 97 "Reserved" 98 "Reserved" 99 "Reserved" 100 "Reserved" 101 "Reserved" 102 "Reserved" 103 "Reserved" 104 "Reserved" 105 "Reserved" 106 "Reserved" 107 "Reserved" 108 "Reserved" 109 "Reserved" 110 "Reserved" 111 "Reserved" 112 "Reserved" 113 "Reserved" 114 "Reserved" 115 "Reserved" 116 "Reserved" 117 "Reserved" 118 "Reserved" 119 "Reserved" 120 "Reserved" 121 "Reserved" 122 "Reserved" 123 "Reserved" 124 "Reserved" 125 "Reserved" 126 "Reserved" 127 "Reserved" 128 "Reserved" 129 "Reserved" 130 "Reserved" 131 "Reserved" 132 "Reserved" 133 "Reserved" 134 "Reserved" 135 "Reserved" 136 "Reserved" 137 "Reserved" 138 "Reserved" 139 "Reserved" 140 "Reserved" 141 "Reserved" 142 "Reserved" 143 "Reserved" 144 "Reserved" 145 "Reserved" 146 "Reserved" 147 "Reserved" 148 "Reserved" 149 "Reserved" 150 "Reserved" 151 "Reserved" 152 "Reserved" 153 "Reserved" 154 "Reserved" 155 "Reserved" 156 "Reserved" 157 "Reserved" 158 "Reserved" 159 "Reserved" 160 "Reserved" 161 "Reserved" 162 "Reserved" 163 "Reserved" 164 "Reserved" 165 "Reserved" 166 "Reserved" 167 "Reserved" 168 "Reserved" 169 "Reserved" 170 "Reserved" 171 "Reserved" 172 "Reserved" 173 "Reserved" 174 "Reserved" 175 "Reserved" 176 "Reserved" 177 "Reserved" 178 "Reserved" 179 "Reserved" 180 "Reserved" 181 "Reserved" 182 "Reserved" 183 "Reserved" 184 "Reserved" 185 "Reserved" 186 "Reserved" 187 "Reserved" 188 "Reserved" 189 "Reserved" 190 "Reserved" 191 "Reserved" 192 "Reserved" 193 "Reserved" 194 "Reserved" 195 "Reserved" 196 "Reserved" 197 "Reserved" 198 "Reserved" 199 "Reserved" 200 "Reserved" 201 "Reserved" 202 "Reserved" 203 "Reserved" 204 "Reserved" 205 "Reserved" 206 "Reserved" 207 "Reserved" 208 "Reserved" 209 "Reserved" 210 "Reserved" 211 "Reserved" 212 "Reserved" 213 "Reserved" 214 "Reserved" 215 "Reserved" 216 "Reserved" 217 "Reserved" 218 "Reserved" 219 "Reserved" 220 "Reserved" 221 "Reserved" 222 "Reserved" 223 "Reserved" 224 "Reserved" 225 "Reserved" 226 "Reserved" 227 "Reserved" 228 "Reserved" 229 "Reserved" 230 "Reserved" 231 "Reserved" 232 "Reserved" 233 "Reserved" 234 "Reserved" 235 "Reserved" 236 "Reserved" 237 "Reserved" 238 "Reserved" 239 "Reserved" 240 "Reserved" 241 "Reserved" 242 "Reserved" 243 "Reserved" 244 "Reserved" 245 "Reserved" 246 "Reserved" 247 "Reserved" 248 "Reserved" 249 "Reserved" 250 "Reserved" 251 "Reserved" 252 "Reserved" 253 "Reserved" 254 "Reserved" 255 "Reserved"  ;
VAL_ 1316 PLGM_PNCInformation0 0 "No request" 1 "Request" 0 "No request" 1 "Request" 0 "No request" 1 "Request" 0 "No request" 1 "Request" 1 "Request" 0 "No request" 1 "Request" 0 "No request" 1 "Request"  ;
VAL_ 1316 PLGM_PNCInformation1 0 "No request" 1 "Request" 0 "No request" 1 "Request"  ;
VAL_ 387 ADC_AD_NetMode 0 "Main Net" 1 "Main and Sub Net" 2 "Reserved" 3 "Reserved"  ;
